VERSION "HNNBNNNYNNNNNNNNNNNNNNNNNNNNNNNNNNNNNNNNNN/4/%%%/4/'%**4NNN///"

NS_ :

BS_:

BU_: BAP_Tester BedienDisp_vo BedienSG_hi CGS DDA Gateway Gateway_PAG GurtMikrofon OTA_FC ZR_High ZR_LIMU ZR_MIB_TOP_ab_Gen3 ZR_Standard

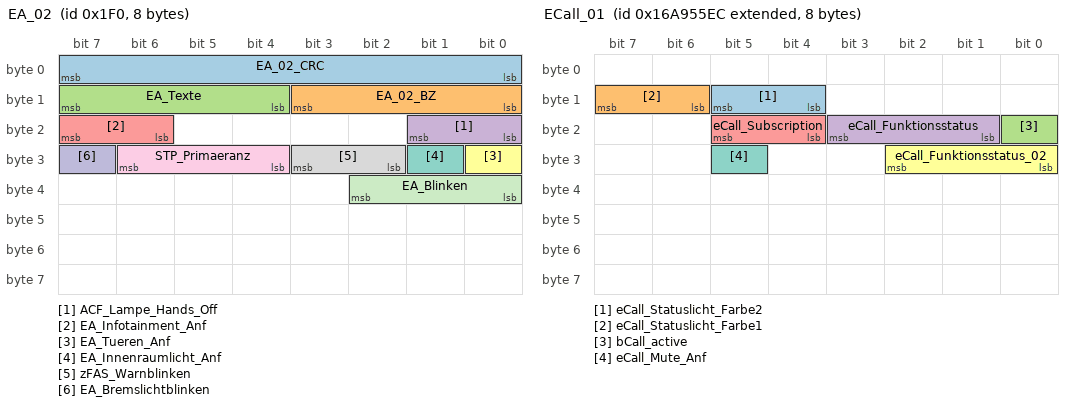
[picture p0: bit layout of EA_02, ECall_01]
BO_ 496 EA_02: 8 Gateway
 SG_ EA_02_CRC : 0|8@1+ (1,0) [0|255] ""  Vector__XXX
 SG_ EA_02_BZ : 8|4@1+ (1,0) [0|15] ""  Vector__XXX
 SG_ EA_Texte : 12|4@1+ (1.0,0.0) [0.0|15] ""  ZR_High
 SG_ ACF_Lampe_Hands_Off : 16|2@1+ (1.0,0.0) [0.0|3] ""  Vector__XXX
 SG_ EA_Infotainment_Anf : 22|2@1+ (1.0,0.0) [0.0|3] ""  ZR_High,ZR_LIMU,ZR_MIB_TOP_ab_Gen3,ZR_Standard
 SG_ EA_Tueren_Anf : 24|1@1+ (1.0,0.0) [0.0|1] ""  ZR_High
 SG_ EA_Innenraumlicht_Anf : 25|1@1+ (1.0,0.0) [0.0|1] ""  ZR_High
 SG_ zFAS_Warnblinken : 26|2@1+ (1.0,0.0) [0.0|3] ""  ZR_High
 SG_ STP_Primaeranz : 28|3@1+ (1.0,0.0) [0.0|7] ""  Vector__XXX
 SG_ EA_Bremslichtblinken : 31|1@1+ (1.0,0.0) [0.0|1] ""  Vector__XXX
 SG_ EA_Blinken : 32|3@1+ (1.0,0.0) [0.0|7] ""  Vector__XXX

BO_ 2527679980 ECall_01: 8 Gateway
 SG_ eCall_Statuslicht_Farbe2 : 12|2@1+ (1.0,0.0) [0.0|3] ""  ZR_High
 SG_ eCall_Statuslicht_Farbe1 : 14|2@1+ (1.0,0.0) [0.0|3] ""  ZR_High
 SG_ bCall_active : 16|1@1+ (1.0,0.0) [0.0|1] ""  OTA_FC,ZR_High
 SG_ eCall_Funktionsstatus : 17|3@1+ (1.0,0.0) [0.0|7] ""  ZR_High
 SG_ eCall_Subscription : 20|2@1+ (1.0,0.0) [0.0|3] ""  Vector__XXX
 SG_ eCall_Funktionsstatus_02 : 24|3@1+ (1.0,0.0) [0.0|7] ""  ZR_High
 SG_ eCall_Mute_Anf : 29|1@1+ (1.0,0.0) [0.0|1] ""  Vector__XXX

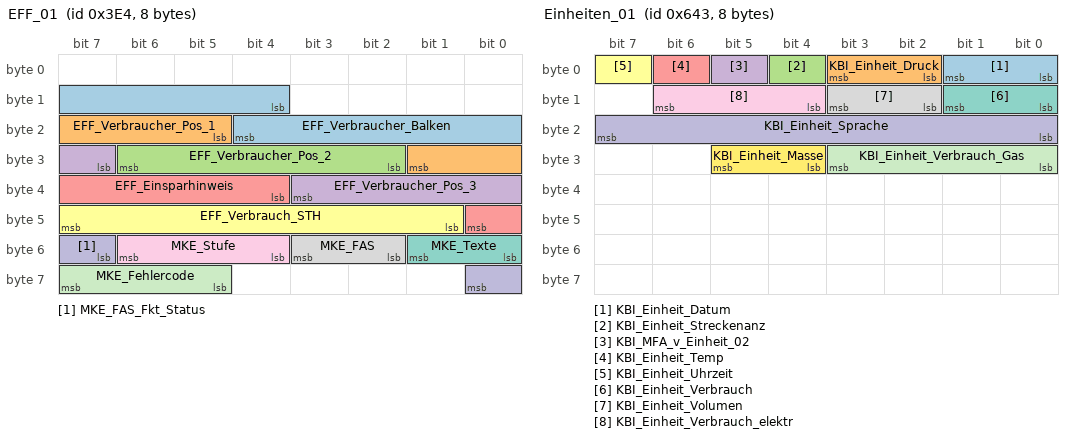
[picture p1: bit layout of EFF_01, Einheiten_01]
BO_ 996 EFF_01: 8 Gateway
 SG_ EFF_Verbraucher_Balken : 12|9@1+ (0.01,0) [0.00|5.09] "Unit_LiterPerHour"  Vector__XXX
 SG_ EFF_Verbraucher_Pos_1 : 21|5@1+ (1.0,0.0) [0.0|31] ""  Vector__XXX
 SG_ EFF_Verbraucher_Pos_2 : 26|5@1+ (1.0,0.0) [0.0|31] ""  Vector__XXX
 SG_ EFF_Verbraucher_Pos_3 : 31|5@1+ (1.0,0.0) [0.0|31] ""  Vector__XXX
 SG_ EFF_Einsparhinweis : 36|5@1+ (1.0,0.0) [0.0|31] ""  Vector__XXX
 SG_ EFF_Verbrauch_STH : 41|7@1+ (0.01,0) [0.00|1.26] "Unit_LiterPerHour"  ZR_High
 SG_ MKE_Texte : 48|2@1+ (1.0,0.0) [0.0|3] ""  ZR_High
 SG_ MKE_FAS : 50|2@1+ (1.0,0.0) [0.0|3] ""  ZR_High
 SG_ MKE_Stufe : 52|3@1+ (1.0,0.0) [0.0|7] ""  ZR_High
 SG_ MKE_FAS_Fkt_Status : 55|2@1+ (1.0,0.0) [0.0|3] ""  ZR_High
 SG_ MKE_Fehlercode : 61|3@1+ (1.0,0.0) [0.0|7] ""  Vector__XXX

BO_ 1603 Einheiten_01: 8 Gateway
 SG_ KBI_Einheit_Datum : 0|2@1+ (1.0,0.0) [0.0|3] ""  BedienSG_hi,OTA_FC,ZR_High,ZR_Standard
 SG_ KBI_Einheit_Druck : 2|2@1+ (1.0,0.0) [0.0|3] ""  BedienSG_hi,OTA_FC,ZR_High,ZR_Standard
 SG_ KBI_Einheit_Streckenanz : 4|1@1+ (1.0,0.0) [0.0|1] ""  BedienSG_hi,OTA_FC,ZR_High,ZR_Standard
 SG_ KBI_MFA_v_Einheit_02 : 5|1@1+ (1.0,0.0) [0.0|1] ""  OTA_FC,ZR_High,ZR_Standard
 SG_ KBI_Einheit_Temp : 6|1@1+ (1.0,0.0) [0.0|1] ""  BedienDisp_vo,BedienSG_hi,OTA_FC,ZR_High,ZR_Standard
 SG_ KBI_Einheit_Uhrzeit : 7|1@1+ (1.0,0.0) [0.0|1] ""  BedienSG_hi,OTA_FC,ZR_High,ZR_Standard
 SG_ KBI_Einheit_Verbrauch : 8|2@1+ (1.0,0.0) [0.0|3] ""  BedienSG_hi,OTA_FC,ZR_High,ZR_Standard
 SG_ KBI_Einheit_Volumen : 10|2@1+ (1.0,0.0) [0.0|3] ""  BedienSG_hi,OTA_FC,ZR_High,ZR_Standard
 SG_ KBI_Einheit_Verbrauch_elektr : 12|3@1+ (1.0,0.0) [0.0|7] ""  OTA_FC
 SG_ KBI_Einheit_Sprache : 16|8@1+ (1,0) [0|255] ""  BedienSG_hi,OTA_FC,ZR_High,ZR_Standard
 SG_ KBI_Einheit_Verbrauch_Gas : 24|4@1+ (1.0,0.0) [0.0|15] ""  Vector__XXX
 SG_ KBI_Einheit_Masse : 28|2@1+ (1.0,0.0) [0.0|3] ""  OTA_FC

BO_ 1622 ELV_01: 8 Gateway
 SG_ ELV_01_CRC : 0|8@1+ (1,0) [0|255] ""  Vector__XXX
 SG_ ELV_01_BZ : 8|4@1+ (1,0) [0|15] ""  Vector__XXX
 SG_ ELV_Anf_Klemme_S : 12|1@1+ (1.0,0.0) [0.0|1] ""  Vector__XXX
 SG_ ELV_Anf_Klemme_15 : 13|1@1+ (1.0,0.0) [0.0|1] ""  Vector__XXX
 SG_ ELV_Anf_Klemme_50 : 14|1@1+ (1.0,0.0) [0.0|1] ""  Vector__XXX
 SG_ ELV_01_Sendestatus : 15|1@1+ (1.0,0.0) [0.0|1] ""  Vector__XXX
 SG_ ELV_Verriegelt : 16|1@1+ (1.0,0.0) [0.0|1] ""  ZR_High
 SG_ ELV_Entriegelt : 17|1@1+ (1.0,0.0) [0.0|1] ""  ZR_High
 SG_ ELV_ZAT_betaetigt : 18|1@1+ (1.0,0.0) [0.0|1] ""  Vector__XXX
 SG_ ELV_Lebenszustand : 19|1@1+ (1.0,0.0) [0.0|1] ""  Vector__XXX
 SG_ ELV_Anlernmodus : 20|1@1+ (1.0,0.0) [0.0|1] ""  Vector__XXX
 SG_ ELV_Klemmenfreigabe : 22|1@1+ (1.0,0.0) [0.0|1] ""  Vector__XXX
 SG_ ELV_Abbruch_Anf_Klemmenfreigabe : 23|1@1+ (1.0,0.0) [0.0|1] ""  Vector__XXX
 SG_ ELV_LED_Rot : 24|1@1+ (1.0,0.0) [0.0|1] ""  ZR_High
 SG_ ELV_LED_Gelb : 25|1@1+ (1.0,0.0) [0.0|1] ""  Vector__XXX
 SG_ ELV_Txt_Panikabschaltung : 27|1@1+ (1.0,0.0) [0.0|1] ""  Vector__XXX
 SG_ ELV_Txt_Lkg_Bewegen : 28|1@1+ (1.0,0.0) [0.0|1] ""  ZR_High
 SG_ ELV_Txt_Werkstatt : 29|1@1+ (1.0,0.0) [0.0|1] ""  ZR_High
 SG_ ELV_Txt_Defekt : 30|1@1+ (1.0,0.0) [0.0|1] ""  ZR_High
 SG_ ELV_Txt_P_Gang : 31|1@1+ (1.0,0.0) [0.0|1] ""  Vector__XXX
 SG_ ELV_Txt_PN_Gang : 32|1@1+ (1.0,0.0) [0.0|1] ""  Vector__XXX
 SG_ ELV_Txt_Kupplung : 33|1@1+ (1.0,0.0) [0.0|1] ""  Vector__XXX
 SG_ ELV_Txt_Bremse : 34|1@1+ (1.0,0.0) [0.0|1] ""  Vector__XXX
 SG_ ELV_P_verriegelt : 35|1@1+ (1.0,0.0) [0.0|1] ""  Vector__XXX

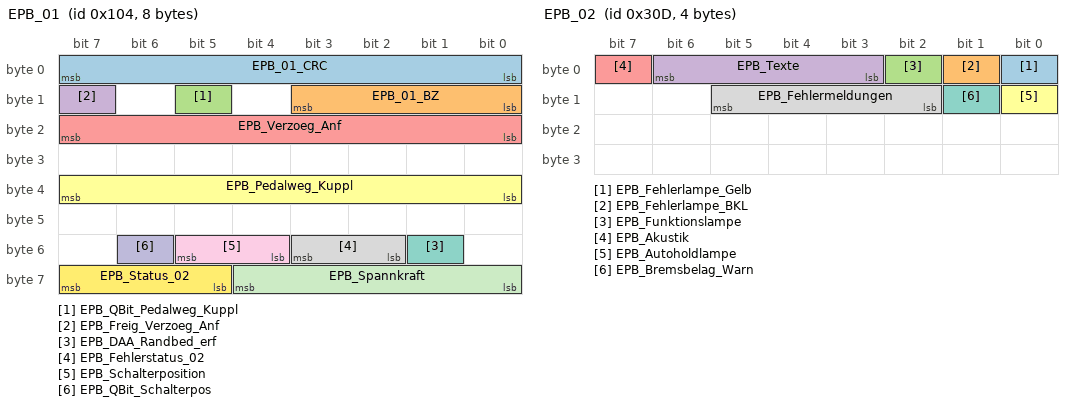
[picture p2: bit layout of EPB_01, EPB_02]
BO_ 260 EPB_01: 8 Gateway
 SG_ EPB_01_CRC : 0|8@1+ (1,0) [0|255] ""  Vector__XXX
 SG_ EPB_01_BZ : 8|4@1+ (1,0) [0|15] ""  Vector__XXX
 SG_ EPB_QBit_Pedalweg_Kuppl : 13|1@1+ (1.0,0.0) [0.0|1] ""  Vector__XXX
 SG_ EPB_Freig_Verzoeg_Anf : 15|1@1+ (1.0,0.0) [0.0|1] ""  Vector__XXX
 SG_ EPB_Verzoeg_Anf : 16|8@1+ (0.048,-7.968) [-7.968|4.224] "Unit_MeterPerSeconSquar"  Vector__XXX
 SG_ EPB_Pedalweg_Kuppl : 32|8@1+ (0.4,0) [8.0|92.0] "Unit_PerCent"  Vector__XXX
 SG_ EPB_DAA_Randbed_erf : 49|1@1+ (1.0,0.0) [0.0|1] ""  Vector__XXX
 SG_ EPB_Fehlerstatus_02 : 50|2@1+ (1.0,0.0) [0.0|3] ""  Vector__XXX
 SG_ EPB_Schalterposition : 52|2@1+ (1.0,0.0) [0.0|3] ""  OTA_FC
 SG_ EPB_QBit_Schalterpos : 54|1@1+ (1.0,0.0) [0.0|1] ""  Vector__XXX
 SG_ EPB_Spannkraft : 56|5@1+ (1,0) [0|29] "Unit_KiloNewto"  Vector__XXX
 SG_ EPB_Status_02 : 61|3@1+ (1.0,0.0) [0.0|7] ""  OTA_FC,ZR_High,ZR_LIMU,ZR_MIB_TOP_ab_Gen3,ZR_Standard

BO_ 781 EPB_02: 4 Gateway
 SG_ EPB_Fehlerlampe_Gelb : 0|1@1+ (1.0,0.0) [0.0|1] ""  Vector__XXX
 SG_ EPB_Fehlerlampe_BKL : 1|1@1+ (1.0,0.0) [0.0|1] ""  Vector__XXX
 SG_ EPB_Funktionslampe : 2|1@1+ (1.0,0.0) [0.0|1] ""  ZR_High
 SG_ EPB_Texte : 3|4@1+ (1.0,0.0) [0.0|15] ""  ZR_High
 SG_ EPB_Akustik : 7|1@1+ (1.0,0.0) [0.0|1] ""  Vector__XXX
 SG_ EPB_Autoholdlampe : 8|1@1+ (1.0,0.0) [0.0|1] ""  OTA_FC,ZR_High
 SG_ EPB_Bremsbelag_Warn : 9|1@1+ (1.0,0.0) [0.0|1] ""  Vector__XXX
 SG_ EPB_Fehlermeldungen : 10|4@1+ (1.0,0.0) [0.0|15] ""  ZR_High

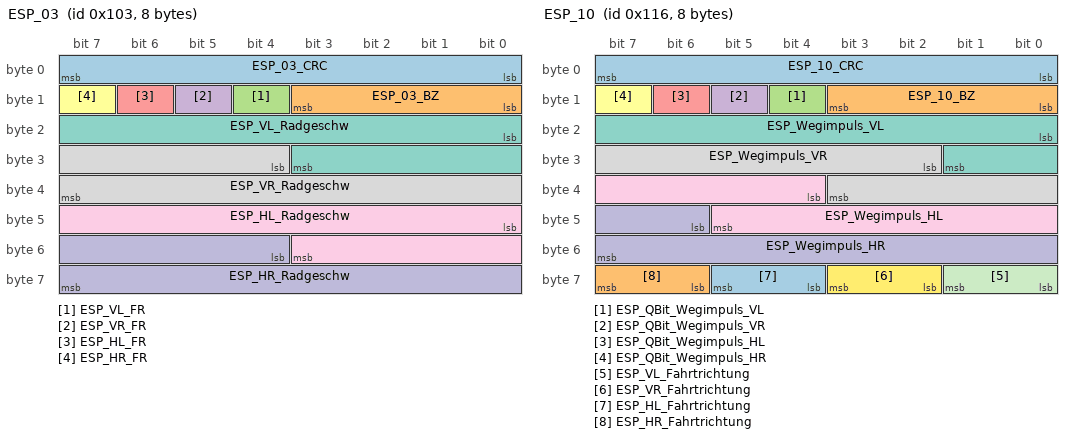
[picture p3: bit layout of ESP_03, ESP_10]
BO_ 259 ESP_03: 8 Gateway
 SG_ ESP_03_CRC : 0|8@1+ (1,0) [0|255] ""  Vector__XXX
 SG_ ESP_03_BZ : 8|4@1+ (1,0) [0|15] ""  Vector__XXX
 SG_ ESP_VL_FR : 12|1@1+ (1.0,0.0) [0.0|1] ""  OTA_FC
 SG_ ESP_VR_FR : 13|1@1+ (1.0,0.0) [0.0|1] ""  OTA_FC
 SG_ ESP_HL_FR : 14|1@1+ (1.0,0.0) [0.0|1] ""  OTA_FC
 SG_ ESP_HR_FR : 15|1@1+ (1.0,0.0) [0.0|1] ""  OTA_FC
 SG_ ESP_VL_Radgeschw : 16|12@1+ (0.1,0) [0.0|409.2] "Unit_KiloMeterPerHour"  OTA_FC,ZR_High,ZR_LIMU,ZR_MIB_TOP_ab_Gen3
 SG_ ESP_VR_Radgeschw : 28|12@1+ (0.1,0) [0.0|409.2] "Unit_KiloMeterPerHour"  OTA_FC,ZR_High,ZR_LIMU,ZR_MIB_TOP_ab_Gen3
 SG_ ESP_HL_Radgeschw : 40|12@1+ (0.1,0) [0.0|409.2] "Unit_KiloMeterPerHour"  OTA_FC,ZR_High,ZR_LIMU,ZR_MIB_TOP_ab_Gen3
 SG_ ESP_HR_Radgeschw : 52|12@1+ (0.1,0) [0.0|409.2] "Unit_KiloMeterPerHour"  OTA_FC,ZR_High,ZR_LIMU,ZR_MIB_TOP_ab_Gen3

BO_ 262 ESP_05: 8 Gateway
 SG_ ESP_05_CRC : 0|8@1+ (1,0) [0|255] ""  Vector__XXX
 SG_ ESP_05_BZ : 8|4@1+ (1,0) [0|15] ""  Vector__XXX
 SG_ ESP_QBit_Bremsdruck : 12|1@1+ (1.0,0.0) [0.0|1] ""  ZR_High,ZR_LIMU,ZR_MIB_TOP_ab_Gen3,ZR_Standard
 SG_ ESP_QBit_Fahrer_bremst : 13|1@1+ (1.0,0.0) [0.0|1] ""  Vector__XXX
 SG_ ESP_Schwelle_Unterdruck : 14|2@1+ (1.0,0.0) [0.0|3] ""  Vector__XXX
 SG_ ESP_Bremsdruck : 16|10@1+ (0.3,-30) [-30.0|276.6] "Unit_Bar"  OTA_FC,ZR_High,ZR_LIMU,ZR_MIB_TOP_ab_Gen3,ZR_Standard
 SG_ ESP_Fahrer_bremst : 26|1@1+ (1.0,0.0) [0.0|1] ""  Vector__XXX
 SG_ ESP_Lenkeingriff_ADS : 28|1@1+ (1.0,0.0) [0.0|1] ""  ZR_High
 SG_ ECD_Fehler : 32|1@1+ (1.0,0.0) [0.0|1] ""  Vector__XXX
 SG_ ECD_nicht_verfuegbar : 33|1@1+ (1.0,0.0) [0.0|1] ""  Vector__XXX
 SG_ ESP_Status_Bremsentemp : 34|1@1+ (1.0,0.0) [0.0|1] ""  Vector__XXX
 SG_ ESP_Autohold_Standby : 35|1@1+ (1.0,0.0) [0.0|1] ""  Vector__XXX
 SG_ ESP_HDC_Standby : 36|1@1+ (1.0,0.0) [0.0|1] ""  Vector__XXX
 SG_ ESP_HBA_aktiv : 37|1@1+ (1.0,0.0) [0.0|1] ""  Vector__XXX
 SG_ ESP_Prefill_ausgeloest : 38|1@1+ (1.0,0.0) [0.0|1] ""  Vector__XXX
 SG_ ESP_Rueckwaertsfahrt_erkannt : 39|1@1+ (1.0,0.0) [0.0|1] ""  Vector__XXX
 SG_ ESP_Status_Anfahrhilfe : 40|1@1+ (1.0,0.0) [0.0|1] ""  ZR_High
 SG_ ESP_HDC_aktiv : 41|1@1+ (1.0,0.0) [0.0|1] ""  ZR_High
 SG_ ESP_StartStopp_Info : 42|2@1+ (1.0,0.0) [0.0|3] ""  Vector__XXX
 SG_ ESP_Eingr_HL : 44|1@1+ (1.0,0.0) [0.0|1] ""  ZR_High,ZR_LIMU,ZR_MIB_TOP_ab_Gen3
 SG_ ESP_Eingr_HR : 45|1@1+ (1.0,0.0) [0.0|1] ""  ZR_High,ZR_LIMU,ZR_MIB_TOP_ab_Gen3
 SG_ ESP_Eingr_VL : 46|1@1+ (1.0,0.0) [0.0|1] ""  ZR_High,ZR_LIMU,ZR_MIB_TOP_ab_Gen3
 SG_ ESP_Eingr_VR : 47|1@1+ (1.0,0.0) [0.0|1] ""  ZR_High,ZR_LIMU,ZR_MIB_TOP_ab_Gen3
 SG_ ESP_BKV_Unterdruck : 48|8@1+ (4,0) [4|1012] "Unit_MilliBar"  Vector__XXX
 SG_ ESP_Autohold_aktiv : 56|1@1+ (1.0,0.0) [0.0|1] ""  ZR_High
 SG_ ESP_FStatus_Anfahrhilfe : 57|1@1+ (1.0,0.0) [0.0|1] ""  Vector__XXX
 SG_ ESP_Verz_EPB_aktiv : 58|1@1+ (1.0,0.0) [0.0|1] ""  Vector__XXX
 SG_ ESC_Bremslicht : 59|1@1+ (1.0,0.0) [0.0|1] ""  OTA_FC
 SG_ ESP_Verzoeg_EPB_verf : 60|1@1+ (1.0,0.0) [0.0|1] ""  Vector__XXX
 SG_ ESP_Status_Bremsdruck : 61|1@1+ (1.0,0.0) [0.0|1] ""  Vector__XXX
 SG_ ESP_Anforderung_EPB : 62|2@1+ (1.0,0.0) [0.0|3] ""  Vector__XXX

BO_ 914 ESP_07: 8 Gateway
 SG_ ESP_07_CRC : 0|8@1+ (1,0) [0|255] ""  Vector__XXX
 SG_ ESP_07_BZ : 8|4@1+ (1,0) [0|15] ""  Vector__XXX
 SG_ ESP_Allrad_Antrieb : 13|1@1+ (1.0,0.0) [0.0|1] ""  Vector__XXX
 SG_ ESP_Codierung_ADS : 14|2@1+ (1.0,0.0) [0.0|3] ""  Vector__XXX
 SG_ ESP_RTA_HL : 16|8@1+ (0.048828125,-6.20117) [-6.201170000|6.152345625] "Unit_PerCent"  Vector__XXX
 SG_ ESP_RTA_HR : 24|8@1+ (0.048828125,-6.20117) [-6.201170000|6.152345625] "Unit_PerCent"  Vector__XXX
 SG_ ESP_RTA_VR : 32|8@1+ (0.048828125,-6.20117) [-6.201170000|6.152345625] "Unit_PerCent"  Vector__XXX
 SG_ OBD_Fehler_Radsensor_HL : 40|4@1+ (1.0,0.0) [0.0|15] ""  Vector__XXX
 SG_ OBD_Fehler_Radsensor_HR : 44|4@1+ (1.0,0.0) [0.0|15] ""  Vector__XXX
 SG_ OBD_Fehler_Radsensor_VL : 48|4@1+ (1.0,0.0) [0.0|15] ""  Vector__XXX
 SG_ OBD_Fehler_Radsensor_VR : 52|4@1+ (1.0,0.0) [0.0|15] ""  Vector__XXX
 SG_ ESP_Qualifizierung_Antriebsart : 56|1@1+ (1.0,0.0) [0.0|1] ""  Vector__XXX
 SG_ ESP_Offroad_Modus : 57|1@1+ (1.0,0.0) [0.0|1] ""  Vector__XXX
 SG_ ESP_MKB_ausloesbar : 58|1@1+ (1.0,0.0) [0.0|1] ""  Vector__XXX
 SG_ ESP_Stat_FallBack_eBKV : 59|1@1+ (1.0,0.0) [0.0|1] ""  Vector__XXX
 SG_ ESC_cAQP_Trigger : 60|1@1+ (1.0,0.0) [0.0|1] ""  Vector__XXX
 SG_ ESP_OBD_Status : 61|1@1+ (1.0,0.0) [0.0|1] ""  Vector__XXX
 SG_ ESP_Rollenmodus_Deaktivieren : 62|1@1+ (1.0,0.0) [0.0|1] ""  ZR_High,ZR_LIMU,ZR_MIB_TOP_ab_Gen3
 SG_ ESP_nachtr_Stopp_Anf : 63|1@1+ (1.0,0.0) [0.0|1] ""  Vector__XXX

BO_ 278 ESP_10: 8 Gateway
 SG_ ESP_10_CRC : 0|8@1+ (1,0) [0|255] ""  Vector__XXX
 SG_ ESP_10_BZ : 8|4@1+ (1,0) [0|15] ""  Vector__XXX
 SG_ ESP_QBit_Wegimpuls_VL : 12|1@1+ (1.0,0.0) [0.0|1] ""  ZR_High,ZR_LIMU,ZR_MIB_TOP_ab_Gen3,ZR_Standard
 SG_ ESP_QBit_Wegimpuls_VR : 13|1@1+ (1.0,0.0) [0.0|1] ""  ZR_High,ZR_LIMU,ZR_MIB_TOP_ab_Gen3,ZR_Standard
 SG_ ESP_QBit_Wegimpuls_HL : 14|1@1+ (1.0,0.0) [0.0|1] ""  ZR_High,ZR_LIMU,ZR_MIB_TOP_ab_Gen3,ZR_Standard
 SG_ ESP_QBit_Wegimpuls_HR : 15|1@1+ (1.0,0.0) [0.0|1] ""  ZR_High,ZR_LIMU,ZR_MIB_TOP_ab_Gen3,ZR_Standard
 SG_ ESP_Wegimpuls_VL : 16|10@1+ (1,0) [0|1000] ""  ZR_High,ZR_LIMU,ZR_MIB_TOP_ab_Gen3,ZR_Standard
 SG_ ESP_Wegimpuls_VR : 26|10@1+ (1,0) [0|1000] ""  ZR_High,ZR_LIMU,ZR_MIB_TOP_ab_Gen3,ZR_Standard
 SG_ ESP_Wegimpuls_HL : 36|10@1+ (1,0) [0|1000] ""  ZR_High,ZR_LIMU,ZR_MIB_TOP_ab_Gen3,ZR_Standard
 SG_ ESP_Wegimpuls_HR : 46|10@1+ (1,0) [0|1000] ""  ZR_High,ZR_LIMU,ZR_MIB_TOP_ab_Gen3,ZR_Standard
 SG_ ESP_VL_Fahrtrichtung : 56|2@1+ (1.0,0.0) [0.0|3] ""  OTA_FC,ZR_High,ZR_LIMU,ZR_MIB_TOP_ab_Gen3,ZR_Standard
 SG_ ESP_VR_Fahrtrichtung : 58|2@1+ (1.0,0.0) [0.0|3] ""  OTA_FC,ZR_High,ZR_LIMU,ZR_MIB_TOP_ab_Gen3,ZR_Standard
 SG_ ESP_HL_Fahrtrichtung : 60|2@1+ (1.0,0.0) [0.0|3] ""  OTA_FC,ZR_High,ZR_LIMU,ZR_MIB_TOP_ab_Gen3,ZR_Standard
 SG_ ESP_HR_Fahrtrichtung : 62|2@1+ (1.0,0.0) [0.0|3] ""  OTA_FC,ZR_High,ZR_LIMU,ZR_MIB_TOP_ab_Gen3,ZR_Standard

BO_ 418 ESP_15: 8 Gateway
 SG_ ESP_15_CRC : 0|8@1+ (1,0) [0|255] ""  Vector__XXX
 SG_ ESP_15_BZ : 8|4@1+ (1,0) [0|15] ""  Vector__XXX
 SG_ HMS_P_beibehalten_GE : 12|2@1+ (1.0,0.0) [0.0|3] ""  Vector__XXX
 SG_ HMS_Konsistenz_GE : 14|1@1+ (1.0,0.0) [0.0|1] ""  Vector__XXX
 SG_ HMS_Konsistenz_IPA : 15|1@1+ (1.0,0.0) [0.0|1] ""  Vector__XXX
 SG_ HMS_Konsistenz_STA : 18|1@1+ (1.0,0.0) [0.0|1] ""  Vector__XXX
 SG_ HMS_Konsistenz_MO : 19|1@1+ (1.0,0.0) [0.0|1] ""  Vector__XXX
 SG_ HMS_halten_nicht_verfuegbar : 20|1@1+ (1.0,0.0) [0.0|1] ""  Vector__XXX
 SG_ NL_PRIM_STP_01_Status : 21|3@1+ (1.0,0.0) [0.0|7] ""  Vector__XXX
 SG_ VMM_Warnblinken : 24|1@1+ (1.0,0.0) [0.0|1] ""  Vector__XXX
 SG_ VZM_Status : 26|3@1+ (1.0,0.0) [0.0|7] ""  Vector__XXX
 SG_ HMS_Notstopp_Status : 29|3@1+ (1.0,0.0) [0.0|7] ""  Vector__XXX
 SG_ HMS_parken_nicht_verfuegbar : 32|1@1+ (1.0,0.0) [0.0|1] ""  Vector__XXX
 SG_ HMS_Anforderung_GE : 33|3@1+ (1.0,0.0) [0.0|7] ""  Vector__XXX
 SG_ HMS_Systemstatus : 36|4@1+ (1.0,0.0) [0.0|15] ""  DDA,ZR_High
 SG_ HMS_Stillstand : 40|3@1+ (1.0,0.0) [0.0|7] ""  Vector__XXX
 SG_ HMS_aktives_System : 43|5@1+ (1.0,0.0) [0.0|31] ""  Vector__XXX
 SG_ HMS_Konsistenz_HVLM : 48|1@1+ (1.0,0.0) [0.0|1] ""  Vector__XXX
 SG_ HMS_Konsistenz_ACC : 49|1@1+ (1.0,0.0) [0.0|1] ""  Vector__XXX
 SG_ HMS_Fehlerstatus : 50|3@1+ (1.0,0.0) [0.0|7] ""  Vector__XXX
 SG_ ESP_Index_Haltemoment : 53|1@1+ (1.0,0.0) [0.0|1] ""  Vector__XXX
 SG_ ESP_Haltemoment : 54|10@1+ (10,0) [0|10210] "Unit_NewtoMeter"  Vector__XXX

BO_ 1629 ESP_20: 8 Gateway
 SG_ ESP_20_CRC : 0|8@1+ (1,0) [0|255] ""  Vector__XXX
 SG_ ESP_20_BZ : 8|4@1+ (1,0) [0|15] ""  Vector__XXX
 SG_ BR_Systemart : 12|2@1+ (1.0,0.0) [0.0|3] ""  Vector__XXX
 SG_ ESP_SpannungsAnf_02 : 14|2@1+ (1.0,0.0) [0.0|3] ""  Vector__XXX
 SG_ ESP_Zaehnezahl : 16|8@1+ (1,0) [0|255] ""  ZR_High,ZR_LIMU,ZR_MIB_TOP_ab_Gen3,ZR_Standard
 SG_ ESP_Charisma_FahrPr : 24|4@1+ (1.0,0.0) [0.0|15] ""  Vector__XXX
 SG_ ESP_Charisma_Status : 28|2@1+ (1.0,0.0) [0.0|3] ""  Vector__XXX
 SG_ ESP_Wiederstart_Anz_01 : 30|1@1+ (1.0,0.0) [0.0|1] ""  ZR_High
 SG_ ESP_Wiederstart_Anz_02 : 31|1@1+ (1.0,0.0) [0.0|1] ""  Vector__XXX
 SG_ ESP_Wiederstart_Anz_03 : 32|1@1+ (1.0,0.0) [0.0|1] ""  Vector__XXX
 SG_ ESP_Wiederstart_Anz_04 : 33|1@1+ (1.0,0.0) [0.0|1] ""  ZR_High
 SG_ ESP_Stoppverbot_Anz_01 : 34|1@1+ (1.0,0.0) [0.0|1] ""  ZR_High
 SG_ ESP_Stoppverbot_Anz_02 : 35|1@1+ (1.0,0.0) [0.0|1] ""  Vector__XXX
 SG_ ESP_Stoppverbot_Anz_03 : 36|1@1+ (1.0,0.0) [0.0|1] ""  Vector__XXX
 SG_ ESP_Stoppverbot_Anz_04 : 37|1@1+ (1.0,0.0) [0.0|1] ""  Vector__XXX
 SG_ ESP_Stoppverbot_Anz_05 : 38|1@1+ (1.0,0.0) [0.0|1] ""  ZR_High
 SG_ ESP_Stoppverbot_Anz_06 : 39|1@1+ (1.0,0.0) [0.0|1] ""  ZR_High
 SG_ ESP_Stoppverbot_Anz_07 : 40|1@1+ (1.0,0.0) [0.0|1] ""  Vector__XXX
 SG_ ESP_Stoppverbot_Anz_Std : 41|1@1+ (1.0,0.0) [0.0|1] ""  Vector__XXX
 SG_ ESP_Dachrelingsensor : 42|2@1+ (1.0,0.0) [0.0|3] ""  ZR_High
 SG_ ESP_Stoppverbot_Anz_08 : 44|1@1+ (1.0,0.0) [0.0|1] ""  Vector__XXX
 SG_ HDC_Charisma_FahrPr : 45|4@1+ (1.0,0.0) [0.0|15] ""  Vector__XXX
 SG_ HDC_Charisma_Status : 49|2@1+ (1.0,0.0) [0.0|3] ""  Vector__XXX
 SG_ BR_QBit_Reifenumfang : 51|1@1+ (1.0,0.0) [0.0|1] ""  ZR_High
 SG_ BR_Reifenumfang : 52|12@1+ (1,0) [0|4095] "Unit_MilliMeter"  ZR_High

BO_ 253 ESP_21: 8 Gateway
 SG_ ESP_21_CRC : 0|8@1+ (1,0) [0|255] ""  Vector__XXX
 SG_ ESP_21_BZ : 8|4@1+ (1,0) [0|15] ""  Vector__XXX
 SG_ BR_Eingriffsmoment : 12|10@1+ (1,-509) [-509|509] ""  Vector__XXX
 SG_ ESP_Diagnose : 23|1@1+ (1.0,0.0) [0.0|1] ""  ZR_High
 SG_ ESC_v_Signal_Qualifier_High_Low : 24|3@1+ (1.0,0.0) [0.0|7] ""  Vector__XXX
 SG_ ESP_Vorsteuerung : 28|1@1+ (1.0,0.0) [0.0|1] ""  Vector__XXX
 SG_ OBD_Schlechtweg : 30|1@1+ (1.0,0.0) [0.0|1] ""  ZR_High
 SG_ OBD_QBit_Schlechtweg : 31|1@1+ (1.0,0.0) [0.0|1] ""  ZR_High
 SG_ ESP_v_Signal : 32|16@1+ (0.01,0) [0.00|655.32] "Unit_KiloMeterPerHour"  BedienSG_hi,DDA,OTA_FC,ZR_High,ZR_LIMU,ZR_MIB_TOP_ab_Gen3,ZR_Standard
 SG_ ASR_Tastung_passiv : 48|1@1+ (1.0,0.0) [0.0|1] ""  OTA_FC
 SG_ ESP_Tastung_passiv : 49|1@1+ (1.0,0.0) [0.0|1] ""  OTA_FC,ZR_High,ZR_LIMU,ZR_MIB_TOP_ab_Gen3
 SG_ ESP_Systemstatus : 50|1@1+ (1.0,0.0) [0.0|1] ""  OTA_FC
 SG_ ASR_Schalteingriff : 51|2@1+ (1.0,0.0) [0.0|3] ""  Vector__XXX
 SG_ ESP_QBit_v_Signal : 55|1@1+ (1.0,0.0) [0.0|1] ""  ZR_High,ZR_LIMU,ZR_MIB_TOP_ab_Gen3,ZR_Standard
 SG_ ABS_Bremsung : 56|1@1+ (1.0,0.0) [0.0|1] ""  OTA_FC,ZR_High,ZR_LIMU,ZR_MIB_TOP_ab_Gen3
 SG_ ASR_Anf : 57|1@1+ (1.0,0.0) [0.0|1] ""  ZR_High
 SG_ MSR_Anf : 58|1@1+ (1.0,0.0) [0.0|1] ""  OTA_FC,ZR_High
 SG_ EBV_Eingriff : 59|1@1+ (1.0,0.0) [0.0|1] ""  Vector__XXX
 SG_ EDS_Eingriff : 60|1@1+ (1.0,0.0) [0.0|1] ""  Vector__XXX
 SG_ ESP_Eingriff : 61|1@1+ (1.0,0.0) [0.0|1] ""  OTA_FC,ZR_High
 SG_ ESP_ASP : 62|1@1+ (1.0,0.0) [0.0|1] ""  ZR_High
 SG_ ESC_Neutralschaltung : 63|1@1+ (1.0,0.0) [0.0|1] ""  Vector__XXX

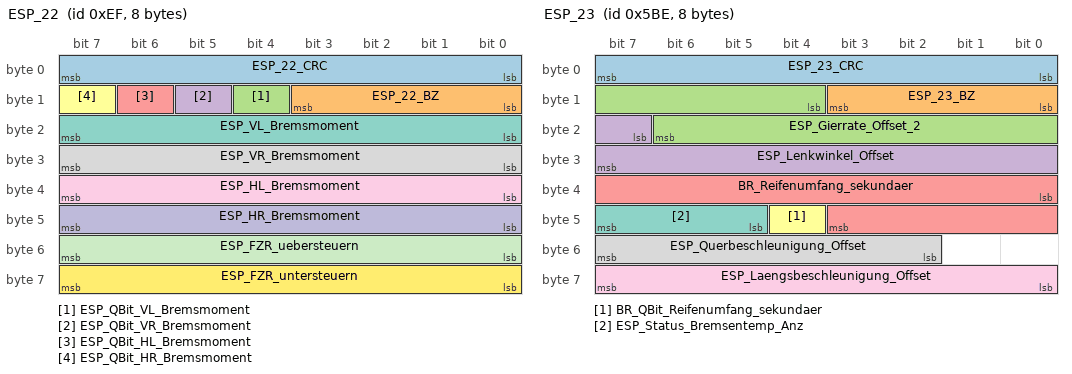
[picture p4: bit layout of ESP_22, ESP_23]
BO_ 239 ESP_22: 8 Gateway
 SG_ ESP_22_CRC : 0|8@1+ (1,0) [0|255] ""  Vector__XXX
 SG_ ESP_22_BZ : 8|4@1+ (1,0) [0|15] ""  Vector__XXX
 SG_ ESP_QBit_VL_Bremsmoment : 12|1@1+ (1.0,0.0) [0.0|1] ""  Vector__XXX
 SG_ ESP_QBit_VR_Bremsmoment : 13|1@1+ (1.0,0.0) [0.0|1] ""  Vector__XXX
 SG_ ESP_QBit_HL_Bremsmoment : 14|1@1+ (1.0,0.0) [0.0|1] ""  Vector__XXX
 SG_ ESP_QBit_HR_Bremsmoment : 15|1@1+ (1.0,0.0) [0.0|1] ""  Vector__XXX
 SG_ ESP_VL_Bremsmoment : 16|8@1+ (40,0) [0|10120] "Unit_NewtoMeter"  OTA_FC
 SG_ ESP_VR_Bremsmoment : 24|8@1+ (40,0) [0|10120] "Unit_NewtoMeter"  OTA_FC
 SG_ ESP_HL_Bremsmoment : 32|8@1+ (20,0) [0|5060] "Unit_NewtoMeter"  OTA_FC
 SG_ ESP_HR_Bremsmoment : 40|8@1+ (20,0) [0|5060] "Unit_NewtoMeter"  OTA_FC
 SG_ ESP_FZR_uebersteuern : 48|8@1+ (0.004,0) [0.000|1.000] ""  OTA_FC,ZR_High,ZR_LIMU,ZR_MIB_TOP_ab_Gen3
 SG_ ESP_FZR_untersteuern : 56|8@1+ (0.004,0) [0.000|1.000] ""  OTA_FC,ZR_High,ZR_LIMU,ZR_MIB_TOP_ab_Gen3

BO_ 1470 ESP_23: 8 Gateway
 SG_ ESP_23_CRC : 0|8@1+ (1,0) [0|255] ""  Vector__XXX
 SG_ ESP_23_BZ : 8|4@1+ (1,0) [0|15] ""  Vector__XXX
 SG_ ESP_Gierrate_Offset_2 : 12|11@1+ (0.01,-10.23) [-10.23|10.22] "Unit_DegreOfArcPerSecon"  Vector__XXX
 SG_ ESP_Lenkwinkel_Offset : 23|9@1+ (0.1,-25.5) [-25.5|25.4] "Unit_DegreOfArc"  Vector__XXX
 SG_ BR_Reifenumfang_sekundaer : 32|12@1+ (1,0) [0|4095] "Unit_MilliMeter"  Vector__XXX
 SG_ BR_QBit_Reifenumfang_sekundaer : 44|1@1+ (1.0,0.0) [0.0|1] ""  Vector__XXX
 SG_ ESP_Status_Bremsentemp_Anz : 45|3@1+ (1.0,0.0) [0.0|7] ""  ZR_High,ZR_LIMU,ZR_MIB_TOP_ab_Gen3
 SG_ ESP_Querbeschleunigung_Offset : 50|6@1+ (0.01,-0.3) [-0.30|0.31] "Unit_ForceOfGravi"  ZR_High
 SG_ ESP_Laengsbeschleunigung_Offset : 56|8@1+ (0.03125,-3.9375) [-3.93750|3.93750] "Unit_MeterPerSeconSquar"  ZR_High

BO_ 795 ESP_24: 8 Gateway
 SG_ ESP_24_CRC : 0|8@1+ (1,0) [0|255] ""  Vector__XXX
 SG_ ESP_24_BZ : 8|4@1+ (1,0) [0|15] ""  Vector__XXX
 SG_ ESP_Lampe : 12|1@1+ (1.0,0.0) [0.0|1] ""  OTA_FC,ZR_High,ZR_LIMU,ZR_MIB_TOP_ab_Gen3
 SG_ ABS_Lampe : 13|1@1+ (1.0,0.0) [0.0|1] ""  OTA_FC,ZR_High
 SG_ BK_Lampe_02 : 14|2@1+ (1.0,0.0) [0.0|3] ""  OTA_FC
 SG_ TC_Lampe : 16|1@1+ (1.0,0.0) [0.0|1] ""  Vector__XXX
 SG_ ESP_m_Raddrehz : 17|15@1+ (0.002,0) [0.000|65.278] "Unit_Hertz"  Vector__XXX
 SG_ ESP_Textanzeigen_03 : 32|5@1+ (1.0,0.0) [0.0|31] ""  OTA_FC
 SG_ ESP_Meldungen : 37|3@1+ (1.0,0.0) [0.0|7] ""  Vector__XXX
 SG_ ESP_Wegimp_VA : 40|11@1+ (1,0) [0|2047] ""  ZR_High,ZR_LIMU,ZR_MIB_TOP_ab_Gen3,ZR_Standard
 SG_ ESP_Fehlerstatus_Wegimp : 51|1@1+ (1.0,0.0) [0.0|1] ""  ZR_High,ZR_LIMU,ZR_MIB_TOP_ab_Gen3,ZR_Standard
 SG_ ESP_Wegimp_Ueberlauf : 52|1@1+ (1.0,0.0) [0.0|1] ""  ZR_High,ZR_LIMU,ZR_MIB_TOP_ab_Gen3,ZR_Standard
 SG_ ESP_QBit_Wegimp_VA : 53|1@1+ (1.0,0.0) [0.0|1] ""  ZR_High,ZR_LIMU,ZR_MIB_TOP_ab_Gen3,ZR_Standard
 SG_ ESP_HDC_Geschw_Farbe : 54|1@1+ (1.0,0.0) [0.0|1] ""  ZR_High,ZR_LIMU,ZR_MIB_TOP_ab_Gen3
 SG_ ESP_Off_Lampe : 55|1@1+ (1.0,0.0) [0.0|1] ""  OTA_FC,ZR_High
 SG_ ESP_HDC_Regelgeschw : 56|7@1+ (0.32,0) [0.32|39.68] "Unit_KiloMeterPerHour"  ZR_High,ZR_LIMU,ZR_MIB_TOP_ab_Gen3,ZR_Standard
 SG_ ESP_BKV_Warnung : 63|1@1+ (1.0,0.0) [0.0|1] ""  OTA_FC

BO_ 508 ESP_32: 8 Gateway
 SG_ ESP_32_CRC : 0|8@1+ (1,0) [0|255] ""  Vector__XXX
 SG_ ESP_32_BZ : 8|4@1+ (1,0) [0|15] ""  Vector__XXX
 SG_ ESP_Status_Bremsentemp_02 : 12|2@1+ (1.0,0.0) [0.0|3] ""  ZR_LIMU,ZR_MIB_TOP_ab_Gen3
 SG_ ESP_Aggregataktivitaet : 14|1@1+ (1.0,0.0) [0.0|1] ""  Vector__XXX
 SG_ ESP_Stillstandsflag : 15|1@1+ (1.0,0.0) [0.0|1] ""  Vector__XXX
 SG_ ESC_MBK_Meldungen : 16|2@1+ (1.0,0.0) [0.0|3] ""  Vector__XXX
 SG_ ESP_EDS_Anzeige : 32|3@1+ (1.0,0.0) [0.0|7] ""  ZR_High,ZR_LIMU,ZR_MIB_TOP_ab_Gen3
 SG_ RLE_Anzeigen : 35|3@1+ (1.0,0.0) [0.0|7] ""  Vector__XXX
 SG_ ESP_Wiederstart_Anz_Std : 38|1@1+ (1.0,0.0) [0.0|1] ""  Vector__XXX
 SG_ ESC_Anforderung_Airbrake : 39|1@1+ (1.0,0.0) [0.0|1] ""  Vector__XXX
 SG_ ESC_FBA_Meldungen : 40|2@1+ (1.0,0.0) [0.0|3] ""  Vector__XXX
 SG_ ESP_Rollover_Status_dyn : 42|2@1+ (1.0,0.0) [0.0|3] ""  Vector__XXX
 SG_ ESP_Rollover_Status_stat : 44|2@1+ (1.0,0.0) [0.0|3] ""  Vector__XXX
 SG_ ESP_AVH_LED : 46|3@1+ (1.0,0.0) [0.0|7] ""  Vector__XXX
 SG_ ESP_HDC_LED : 49|3@1+ (1.0,0.0) [0.0|7] ""  Vector__XXX
 SG_ ESP_Off_LED : 52|3@1+ (1.0,0.0) [0.0|7] ""  Vector__XXX
 SG_ ESP_Notbremsanzeige : 55|1@1+ (1.0,0.0) [0.0|1] ""  Vector__XXX
 SG_ ESC_Motorstartverzoegerung : 56|1@1+ (1.0,0.0) [0.0|1] ""  Vector__XXX
 SG_ ESP_Offroad_Lampe : 57|1@1+ (1.0,0.0) [0.0|1] ""  Vector__XXX
 SG_ ESP_HDC_Textanzeigen : 58|5@1+ (1.0,0.0) [0.0|31] ""  Vector__XXX
 SG_ ESP_HOLD_verf : 63|1@1+ (1.0,0.0) [0.0|1] ""  OTA_FC

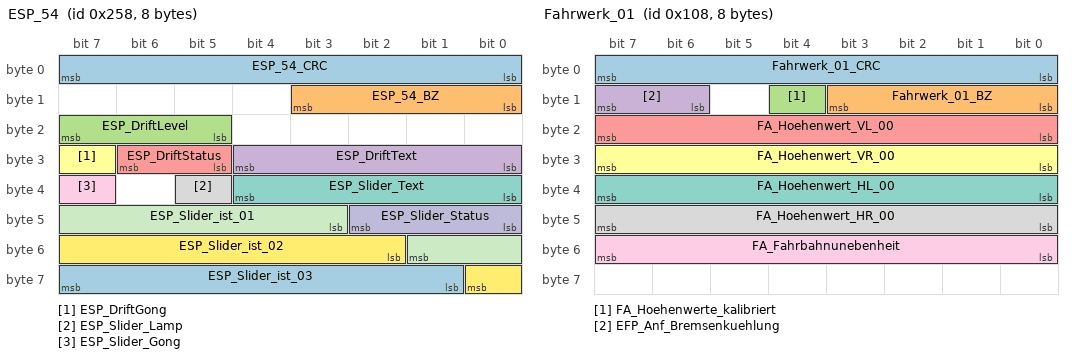
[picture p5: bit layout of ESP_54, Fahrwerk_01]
BO_ 600 ESP_54: 8 Gateway
 SG_ ESP_54_CRC : 0|8@1+ (1,0) [0|255] ""  ZR_LIMU
 SG_ ESP_54_BZ : 8|4@1+ (1,0) [0|15] ""  ZR_LIMU
 SG_ ESP_DriftLevel : 21|3@1+ (1.0,0.0) [0.0|7] ""  Vector__XXX
 SG_ ESP_DriftText : 24|5@1+ (1.0,0.0) [0.0|31] ""  Vector__XXX
 SG_ ESP_DriftStatus : 29|2@1+ (1.0,0.0) [0.0|3] ""  Vector__XXX
 SG_ ESP_DriftGong : 31|1@1+ (1.0,0.0) [0.0|1] ""  Vector__XXX
 SG_ ESP_Slider_Text : 32|5@1+ (1.0,0.0) [0.0|31] ""  ZR_LIMU
 SG_ ESP_Slider_Lamp : 37|1@1+ (1.0,0.0) [0.0|1] ""  Vector__XXX
 SG_ ESP_Slider_Gong : 39|1@1+ (1.0,0.0) [0.0|1] ""  Vector__XXX
 SG_ ESP_Slider_Status : 40|3@1+ (1.0,0.0) [0.0|7] ""  ZR_LIMU
 SG_ ESP_Slider_ist_01 : 43|7@1+ (1,0) [0|126] ""  ZR_LIMU
 SG_ ESP_Slider_ist_02 : 50|7@1+ (1,0) [0|126] ""  ZR_LIMU
 SG_ ESP_Slider_ist_03 : 57|7@1+ (1,0) [0|126] ""  ZR_LIMU

BO_ 264 Fahrwerk_01: 8 Gateway
 SG_ Fahrwerk_01_CRC : 0|8@1+ (1,0) [0|255] ""  Vector__XXX
 SG_ Fahrwerk_01_BZ : 8|4@1+ (1,0) [0|15] ""  Vector__XXX
 SG_ FA_Hoehenwerte_kalibriert : 12|1@1+ (1.0,0.0) [0.0|1] ""  ZR_High
 SG_ EFP_Anf_Bremsenkuehlung : 14|2@1+ (1.0,0.0) [0.0|3] ""  Vector__XXX
 SG_ FA_Hoehenwert_VL_00 : 16|8@1+ (1,-127) [-127|126] "Unit_MilliMeter"  DDA,OTA_FC,ZR_High
 SG_ FA_Hoehenwert_VR_00 : 24|8@1+ (1,-127) [-127|126] "Unit_MilliMeter"  DDA,OTA_FC,ZR_High
 SG_ FA_Hoehenwert_HL_00 : 32|8@1+ (1,-127) [-127|126] "Unit_MilliMeter"  DDA,OTA_FC,ZR_High
 SG_ FA_Hoehenwert_HR_00 : 40|8@1+ (1,-127) [-127|126] "Unit_MilliMeter"  DDA,OTA_FC,ZR_High
 SG_ FA_Fahrbahnunebenheit : 48|8@1+ (1,0) [0|253] ""  OTA_FC,ZR_High

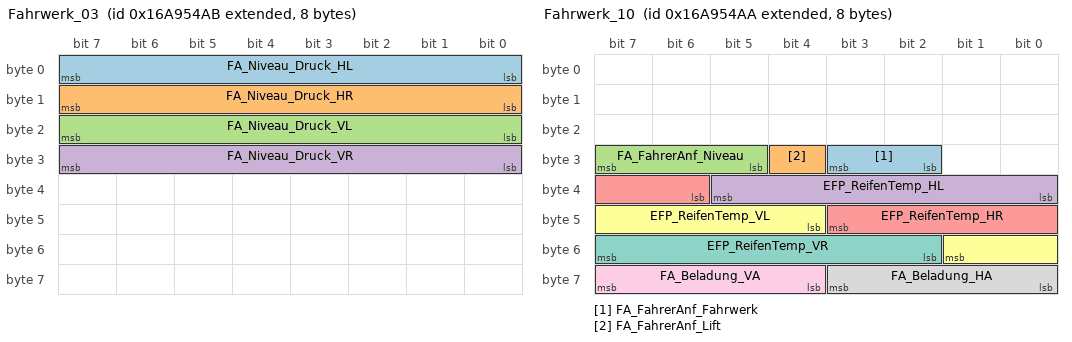
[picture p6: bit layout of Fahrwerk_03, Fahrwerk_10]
BO_ 2527679659 Fahrwerk_03: 8 Gateway
 SG_ FA_Niveau_Druck_HL : 0|8@1+ (0.1,0) [0.0|25.3] "Unit_Bar"  OTA_FC,ZR_High
 SG_ FA_Niveau_Druck_HR : 8|8@1+ (0.1,0) [0.0|25.3] "Unit_Bar"  OTA_FC,ZR_High
 SG_ FA_Niveau_Druck_VL : 16|8@1+ (0.1,0) [0.0|25.3] "Unit_Bar"  OTA_FC,ZR_High
 SG_ FA_Niveau_Druck_VR : 24|8@1+ (0.1,0) [0.0|25.3] "Unit_Bar"  OTA_FC,ZR_High

BO_ 429 Fahrwerk_06: 8 Gateway
 SG_ Fahrwerk_06_CRC : 0|8@1+ (1,0) [0|255] ""  Vector__XXX
 SG_ Fahrwerk_06_BZ : 8|4@1+ (1,0) [0|15] ""  Vector__XXX
 SG_ NR_Reglerstatus : 12|4@1+ (1.0,0.0) [0.0|15] ""  OTA_FC,ZR_High
 SG_ FA_Verstellung_in_Kuerze : 16|1@1+ (1.0,0.0) [0.0|1] ""  ZR_High
 SG_ FA_Verstellung_aktiv : 17|1@1+ (1.0,0.0) [0.0|1] ""  ZR_High
 SG_ FA_Kompressor_laeuft_in_Kuerze : 18|1@1+ (1.0,0.0) [0.0|1] ""  Vector__XXX
 SG_ FA_Kompressor_laeuft : 19|1@1+ (1.0,0.0) [0.0|1] ""  OTA_FC
 SG_ NR_Anforderung_v_Begrenzung : 20|2@1+ (1.0,0.0) [0.0|3] ""  Vector__XXX
 SG_ NR_LED_SGN : 22|1@1+ (1.0,0.0) [0.0|1] ""  ZR_High
 SG_ NR_LED_TN : 23|1@1+ (1.0,0.0) [0.0|1] ""  ZR_High
 SG_ NR_LED_BN : 24|1@1+ (1.0,0.0) [0.0|1] ""  ZR_High
 SG_ FA_Absenkung_Fahrzeug : 25|1@1+ (1.0,0.0) [0.0|1] ""  OTA_FC,ZR_High
 SG_ FA_Anhaengerstatus_intern : 26|3@1+ (1.0,0.0) [0.0|7] ""  OTA_FC,ZR_High
 SG_ FA_Anhebung_Fahrzeug : 29|1@1+ (1.0,0.0) [0.0|1] ""  OTA_FC,ZR_High
 SG_ FA_Druckspeicher_verfuegbar : 30|1@1+ (1.0,0.0) [0.0|1] ""  OTA_FC
 SG_ FA_HAL_Abschaltung : 31|1@1+ (1.0,0.0) [0.0|1] ""  OTA_FC
 SG_ FA_ESP_Zuschaltung : 32|1@1+ (1.0,0.0) [0.0|1] ""  OTA_FC
 SG_ NR_LED_HN : 33|1@1+ (1.0,0.0) [0.0|1] ""  OTA_FC,ZR_High
 SG_ FA_Zwischenniveau : 34|1@1+ (1.0,0.0) [0.0|1] ""  OTA_FC
 SG_ FA_Systemstatus : 35|1@1+ (1.0,0.0) [0.0|1] ""  ZR_High
 SG_ EFP_Soll_FahrPr_HAL : 36|4@1+ (1.0,0.0) [0.0|15] ""  Vector__XXX
 SG_ NR_Kompressor_Strom_02 : 40|8@1+ (0.2,0) [0.0|50.8] "Unit_Amper"  OTA_FC
 SG_ NR_Kompressor_Temp_Zylinderkopf : 48|8@1+ (1,-40) [-40|213] "Unit_DegreCelsi"  OTA_FC
 SG_ FA_Signal_Drucksensor : 56|8@1+ (0.1,0) [0.0|25.3] "Unit_Bar"  OTA_FC

BO_ 2527679658 Fahrwerk_10: 8 Gateway
 SG_ FA_FahrerAnf_Fahrwerk : 26|2@1+ (1.0,0.0) [0.0|3] ""  OTA_FC,ZR_MIB_TOP_ab_Gen3
 SG_ FA_FahrerAnf_Lift : 28|1@1+ (1.0,0.0) [0.0|1] ""  OTA_FC,ZR_MIB_TOP_ab_Gen3
 SG_ FA_FahrerAnf_Niveau : 29|3@1+ (1.0,0.0) [0.0|7] ""  OTA_FC,ZR_MIB_TOP_ab_Gen3
 SG_ EFP_ReifenTemp_HL : 32|6@1+ (2,-25) [-25|99] "Unit_DegreCelsi"  OTA_FC
 SG_ EFP_ReifenTemp_HR : 38|6@1+ (2,-25) [-25|99] "Unit_DegreCelsi"  OTA_FC
 SG_ EFP_ReifenTemp_VL : 44|6@1+ (2,-25) [-25|99] "Unit_DegreCelsi"  OTA_FC
 SG_ EFP_ReifenTemp_VR : 50|6@1+ (2,-25) [-25|99] "Unit_DegreCelsi"  OTA_FC
 SG_ FA_Beladung_HA : 56|4@1+ (50,0) [0|650] "Unit_KiloGram"  ZR_High
 SG_ FA_Beladung_VA : 60|4@1+ (50,0) [0|650] "Unit_KiloGram"  ZR_High

BO_TX_BU_ 496 :Gateway,Gateway_PAG;
BO_TX_BU_ 2527679980 :Gateway,Gateway_PAG;
BO_TX_BU_ 996 :Gateway,Gateway_PAG;
BO_TX_BU_ 1603 :Gateway,Gateway_PAG;
BO_TX_BU_ 1622 :Gateway,Gateway_PAG;
BO_TX_BU_ 260 :Gateway,Gateway_PAG;
BO_TX_BU_ 781 :Gateway,Gateway_PAG;
BO_TX_BU_ 259 :Gateway,Gateway_PAG;
BO_TX_BU_ 262 :Gateway,Gateway_PAG;
BO_TX_BU_ 914 :Gateway,Gateway_PAG;
BO_TX_BU_ 278 :Gateway,Gateway_PAG;
BO_TX_BU_ 418 :Gateway,Gateway_PAG;
BO_TX_BU_ 1629 :Gateway,Gateway_PAG;
BO_TX_BU_ 253 :Gateway,Gateway_PAG;
BO_TX_BU_ 239 :Gateway,Gateway_PAG;
BO_TX_BU_ 1470 :Gateway,Gateway_PAG;
BO_TX_BU_ 795 :Gateway,Gateway_PAG;
BO_TX_BU_ 508 :Gateway,Gateway_PAG;
BO_TX_BU_ 264 :Gateway,Gateway_PAG;
BO_TX_BU_ 2527679659 :Gateway,Gateway_PAG;
BO_TX_BU_ 429 :Gateway,Gateway_PAG;
BO_TX_BU_ 2527679658 :Gateway,Gateway_PAG;
CM_ BO_ 1603 "ab MQB mit 8 Byte";
CM_ BO_ 260 "ab MQB mit CRC-8";
CM_ BO_ 259 "MLBevo - CRC-Absicherung";
CM_ BO_ 418 "MLBevo verlangsamte 100ms-Botschaft";
CM_ BO_ 1629 "neu im MQB";
CM_ BO_ 253 "Neue Momente im MQB
Struktur ab MQB mit CRC8 entstanden aus ESP_01";
CM_ BO_ 1470 "MSS (AU724/5, LBxxx) Botschaft zur Offsetkompentation";
CM_ BO_ 795 "neu für MQB wg. Absicherung
Entstanden aus ESP_04";
CM_ BO_ 508 "CAN-Botschaft";
CM_ BO_ 264 "ab MLBevo mit CRC";

CM_ SG_ 496 ACF_Lampe_Hands_Off "Anzeige, ob der Fahrer die Hände am Lenkrad hat.";
CM_ SG_ 496 EA_02_BZ "Botschaftszähler
Botschaft asynchron geroutet. Zählerwert kann springen.";
CM_ SG_ 496 EA_02_CRC "Für MLB:
'Berechnung siehe Lastenheft 'Kommunikationsabsicherung für Flexray und CAN''

Ab MQB und MLBevo:
'Berechnung siehe Lastenheft 'End-to-End Kommunikationsabsicherung'

Endwerte siehe Begleitdokument 'S-PDU Kennungsfolge'";
CM_ SG_ 496 EA_Blinken "Emergency Assist Anforderung Blinker";
CM_ SG_ 496 EA_Bremslichtblinken "Die Funktion Emergency Alert fordert ein Blinken der Bremsleuchten an.";
CM_ SG_ 496 EA_Infotainment_Anf "Emergency Assist Anforderung Absenkung Infotainment-Funktionen";
CM_ SG_ 496 EA_Innenraumlicht_Anf "Anforderung Innenraumbeleuchtung durch den Emergency Assist";
CM_ SG_ 496 EA_Texte "Anzeige der EA Texte";
CM_ SG_ 496 EA_Tueren_Anf "Emergency Assist Anforderung Türen entriegeln";
CM_ SG_ 496 STP_Primaeranz "Primäranzeige des Staupiloten";
CM_ SG_ 496 zFAS_Warnblinken "Anforderung Warnblinken durch zFAS Funktionen.";

CM_ SG_ 2527679980 bCall_active "1: Breakdown call is active
0: BreakdownCall is inactive";
CM_ SG_ 2527679980 eCall_Funktionsstatus "HMI-Aufruf im Kombi (Broadcast)
Fehlerfälle die im Kombi angezeigt werden können";
CM_ SG_ 2527679980 eCall_Funktionsstatus_02 "Erweiterung des Funktionsstatus für andere Funktionen
ACN aktiv, MEC aktiv
MEC = manual emergency call = maueller Notruf
ACN = automatic emergency call = automatischer Notruf";
CM_ SG_ 2527679980 eCall_Mute_Anf "Signalisiert die Aufforderungen alle Soundquellen im Fahrzeug während eines aktiven Notrufs zu muten";
CM_ SG_ 2527679980 eCall_Statuslicht_Farbe1 "Steuerung Statuslicht (Farbe1) für Funktionsrückmeldungen Emergency Call / SOS Hilferuf,
z.B. LED-Anzeige im Dachmodul.";
CM_ SG_ 2527679980 eCall_Statuslicht_Farbe2 "Steuerung Statuslicht (Farbe2) für Funktionsrückmeldungen Emergency Call / SOS Hilferuf,
z.B. LED-Anzeige im Dachmodul.";
CM_ SG_ 2527679980 eCall_Subscription "Anzeige 'Service Unsubscribed' im Kombi - Aktualisierte Namensgebung";

CM_ SG_ 996 EFF_Einsparhinweis "Anforderung der Anzeige von veschiedenen Life-Tipps";
CM_ SG_ 996 EFF_Verbrauch_STH "Verbrauchsanteil der Standheizung im Komfortverbrauch (siehe EFF_Verbraucher_Balken)";
CM_ SG_ 996 EFF_Verbraucher_Balken "Anzeige der Zusatzverbraucher (Anzeige 0-5,09 l/h in 0,01 l/h - Schritten) für BCmE (Bordcomputer mit Effizienzprogramm)";
CM_ SG_ 996 EFF_Verbraucher_Pos_1 "Name des Zusatzverbraucher an Listenposition '1' der Top-Verbraucher für die Balkenanzeige 'Zusatzverbraucher'";
CM_ SG_ 996 EFF_Verbraucher_Pos_2 "Name des Zusatzverbraucher an Listenposition '2' der Top-Verbraucher für die Balkenanzeige 'Zusatzverbraucher'";
CM_ SG_ 996 EFF_Verbraucher_Pos_3 "Name des Zusatzverbraucher an Listenposition '3' der Top-Verbraucher für die Balkenanzeige 'Zusatzverbraucher'";
CM_ SG_ 996 MKE_FAS "Sicherheitshinweis für FAS.";
CM_ SG_ 996 MKE_FAS_Fkt_Status "Statussignal für FAS-Profilemaster.";
CM_ SG_ 996 MKE_Fehlercode "Fehlercode der Funktion Müdigkeitserkennung.";
CM_ SG_ 996 MKE_Stufe "Das Signal bildet die Müdigkeitsstufe im Kombi ab:
0 - deaktiviert
1 - nicht_verfügbar
2 - Stufe_1
3 - Stufe_2
4 - Stufe_3
5 - Stufe_4
6 - reserviert
7 - reserviert";
CM_ SG_ 996 MKE_Texte "Systemhinweis und Sicherheitshinweis für Anzeige im Kombi";

CM_ SG_ 1603 KBI_Einheit_Datum "Anzeigevariante des Datums";
CM_ SG_ 1603 KBI_Einheit_Druck "Einheit des Druckes";
CM_ SG_ 1603 KBI_Einheit_Masse "Einheit der Masse (Verwendung z.B. ASTA)";
CM_ SG_ 1603 KBI_Einheit_Sprache "Siehe BAP-Datenfestlegung UnitMaster";
CM_ SG_ 1603 KBI_Einheit_Streckenanz "Einheit der Streckenanzeige";
CM_ SG_ 1603 KBI_Einheit_Temp "Einheit der Temperatur";
CM_ SG_ 1603 KBI_Einheit_Uhrzeit "Anzeigevariante der Uhrzeit";
CM_ SG_ 1603 KBI_Einheit_Verbrauch "Einheit der Verbrauchs";
CM_ SG_ 1603 KBI_Einheit_Verbrauch_elektr "Einheit elektrischer Verbrauch";
CM_ SG_ 1603 KBI_Einheit_Verbrauch_Gas "Unterscheidung zwischen M3/h und kg/h für Komfortverbrauchsberechnung.";
CM_ SG_ 1603 KBI_Einheit_Volumen "Einheit des Volumens";
CM_ SG_ 1603 KBI_MFA_v_Einheit_02 "Einheit der Geschwindigkeit, die vom Fahrer im Car-Menü gewählt wurde. Veränderliche Grösse, im Gegensatz zur Einheit des Tachokranzes.

Redundant in der Einheiten_01 Botschaft definiert, um Konsistenz zur BAP-Festlegung zu haben.";

CM_ SG_ 1622 ELV_01_BZ "4bit Botschaftszaehler, wird mit jeder Sendebotschaft inkrementiert";
CM_ SG_ 1622 ELV_01_CRC "Ab MQB und MLBevo:
'Berechnung siehe Lastenheft 'End-to-End Kommunikationsabsicherung''

Endwerte siehe Begleitdokument 'S-PDU Kennungsfolgen'";
CM_ SG_ 1622 ELV_01_Sendestatus "Zeigt an, ob die ELV für einen begrenzten Zeitraum mit verkürzter Zykluszeit (50ms) sendet. Das ist bis zur KL15ein notwendig, um eine Motorstartverzögerung zu vermeiden.";
CM_ SG_ 1622 ELV_Abbruch_Anf_Klemmenfreigabe "Klemmenanforderung des Kessy-SG wird von der ELV verworfen und muss vom Kessy zurückgenommen werden.";
CM_ SG_ 1622 ELV_Anf_Klemme_15 "Signal wird zur Plausibilisierung parrallel zum Klemmensignal auf dem CAN übertragen
Anforderung Klemme_15";
CM_ SG_ 1622 ELV_Anf_Klemme_50 "Signal wird zur Plausibilisierung parrallel zum Klemmensignal auf dem CAN übertragen
Anforderung Klemme_50";
CM_ SG_ 1622 ELV_Anf_Klemme_S "Signal wird zur Plausibilisierung parallel zum Klemmensignal auf dem CAN übertragen
Anforderung Klemme_S";
CM_ SG_ 1622 ELV_Anlernmodus "Im Anlernmodus (1) ist zum Einschalten der KLS u.KL15 keine Authentifizierung der WFS notwendig. KL50 ist nicht einschaltbar.
Auslieferungszustand ist (1)";
CM_ SG_ 1622 ELV_Entriegelt "ELV im Zustand entriegelt
";
CM_ SG_ 1622 ELV_Klemmenfreigabe "Freigabe/Quittierung der ELV für das Einschalten der Klemme 15 und Klemme S";
CM_ SG_ 1622 ELV_Lebenszustand "Auslieferungszustand ist (0)
Lebenszustand";
CM_ SG_ 1622 ELV_LED_Gelb "Warnlampe Gelb";
CM_ SG_ 1622 ELV_LED_Rot "Warnlampe Rot";
CM_ SG_ 1622 ELV_P_verriegelt "Position P-verriegelt vom Gangwahlhebel";
CM_ SG_ 1622 ELV_Txt_Bremse "Text: 'Bremspedal betätigen!'";
CM_ SG_ 1622 ELV_Txt_Defekt "Text: 'Lenkungsverriegelung defekt!'";
CM_ SG_ 1622 ELV_Txt_Kupplung "Text: 'Kupplungspedal betätigen!'";
CM_ SG_ 1622 ELV_Txt_Lkg_Bewegen "Text: 'Lenkrad bewegen!'";
CM_ SG_ 1622 ELV_Txt_P_Gang "Text: 'Wählhebel in Position P bringen!'";
CM_ SG_ 1622 ELV_Txt_Panikabschaltung "Text: 'Notabschaltung''";
CM_ SG_ 1622 ELV_Txt_PN_Gang "Text: 'Wählhebel in Position P/N bringen!'";
CM_ SG_ 1622 ELV_Txt_Werkstatt "Text: 'Lenkungsverriegelung! Werkstatt!'";
CM_ SG_ 1622 ELV_Verriegelt "ELV im Zustand verriegelt
";
CM_ SG_ 1622 ELV_ZAT_betaetigt "Zündanlass-Taster (ZAT) betätigt";

CM_ SG_ 260 EPB_01_BZ "Botschaft asynchron geroutet. Zählerwert kann springen.";
CM_ SG_ 260 EPB_01_CRC "Für MLB:
'Berechnung siehe Lastenheft 'Kommunikationsabsicherung für FlexRay und CAN''

Ab MQB und MLBevo:
'Berechnung siehe Lastenheft 'End-to-End Kommunikationsabsicherung''

Endwerte siehe Begleitdokument 'S-PDU Kennungsfolgen'";
CM_ SG_ 260 EPB_DAA_Randbed_erf "Die Randbedingungen zum automatischen Öffnen der EPB (Funktion DAA) sind erfüllt und ein Betätigen des Fahrpedals führt zum Öffnen der EPB.";
CM_ SG_ 260 EPB_Fehlerstatus_02 "Anpassung der Texte an die  aktuellen Zustände für weitergehende Funktionen (Stillstandsmanager)";
CM_ SG_ 260 EPB_Freig_Verzoeg_Anf "Verzögerungsanforderung	";
CM_ SG_ 260 EPB_Pedalweg_Kuppl "Signal entspricht Tastverhältnis des PWM. Gesamtweg Kupplungspedal 10% bis 90%, damit zu erwartende Werte 25 bis 225. 25 bei Kupplungspedal nicht getreten, 225 bei Kupplungspedal voll durchgetreten.
2% Toleranz wird im Wertebereich ermöglicht (8%-92%).
";
CM_ SG_ 260 EPB_Schalterposition "Spiegelt die Schalterstellung wieder.

0x3 = Schalterfehler ";
CM_ SG_ 260 EPB_Spannkraft "Erzeugte Spannkraft. Bezieht sich auf die Aktuatoren.

MQB: Spannkraftwerte entsprechen nicht den tatsächlichen Spannkräften. Genauere Informationen bitte in der Fachabteilung erfragen! ";
CM_ SG_ 260 EPB_Status_02 "Erweiterung der Zustände um ein genaueres Bild des aktuellen Zustandes zu erhalten für weitergehende Funktionen ( Stillstandsmanager)
";
CM_ SG_ 260 EPB_Verzoeg_Anf "Steuerungsanforderung an andere Systeme (z.B. ESP), um während der Fahrt, durch den Handbremsschalter ausgelöst, zu bremsen (ECD-Funktion)";

CM_ SG_ 781 EPB_Akustik "Bit wird gesetzt, wenn bei v > 0 eine Fahreran-forderung schließen vorhanden ist (ECD angefordert). PQ46-Kombi sendet Warnton (600Hz) solange dieses Bit gesetzt ist.
Anzeige eines Warntextes
";
CM_ SG_ 781 EPB_Autoholdlampe "Autoholdlampe im Kombi, grünes P
";
CM_ SG_ 781 EPB_Bremsbelag_Warn "Mindestens ein Bremsbelag an der Hinterachse am Fahrzeug ist unter Minimum";
CM_ SG_ 781 EPB_Fehlerlampe_BKL "Die BKL dient als rote Fehlerlampe für die EPB. Sie wird vom EPB-SG aktiv ausgeschaltet.";
CM_ SG_ 781 EPB_Fehlerlampe_Gelb "Fehlerlampe für nicht liegenbleiberreleavante Fehler";
CM_ SG_ 781 EPB_Fehlermeldungen "Über das Signal werden bestimmte Fehlertexte und -lampen im Kombi angefordert.";
CM_ SG_ 781 EPB_Funktionslampe "Bit wird nur gesetzt, wenn volle Spannkraft auf beiden Seiten erreicht. PQ46: Bit wird gesetzt, wenn BKL direkt vom EPB-SG als Funktionslampe angesteuert wird.

Bei Audi: Rote Lampe (rotes P) im Kombiinstrument
";
CM_ SG_ 781 EPB_Texte "EPB-Texte für Kombi
9 bei Audi aktuell nicht bedient.
10 bei Audi hinzugefügt für RSe
11 bei PAG Duo Servo Parkbremse aktuell nicht bedient 
12 bei PAG Duo Servo Parkbremse aktuell nicht bedient 
13 nur bei ParkPilot/IPA verwendet";

CM_ SG_ 259 ESP_03_BZ "Botschaft asynchron geroutet. Zählerwert kann springen.";
CM_ SG_ 259 ESP_03_CRC "Ab MQB und MLBevo:
'Berechnung siehe Lastenheft 'End-to-End Kommunikationsabsicherung''

Endwerte siehe Begleitdokument 'S-PDU Kennungsfolgen'";
CM_ SG_ 259 ESP_HL_FR "Fahrtrichtungserkennung Rad Hinten Links
";
CM_ SG_ 259 ESP_HL_Radgeschw "Radgeschwindigkeit hinten links";
CM_ SG_ 259 ESP_HR_FR "Fahrtrichtungserkennung Rad Hinten Rechts
";
CM_ SG_ 259 ESP_HR_Radgeschw "Radgeschwindigkeit hinten rechts";
CM_ SG_ 259 ESP_VL_FR "Fahrtrichtungserkennung Rad Vorne Links
";
CM_ SG_ 259 ESP_VL_Radgeschw "Radgeschwindigkeit vorne links";
CM_ SG_ 259 ESP_VR_FR "Fahrtrichtungserkennung Rad Vorne Rechts

";
CM_ SG_ 259 ESP_VR_Radgeschw "Radgeschwindigkeit vorne rechts";

CM_ SG_ 262 ECD_Fehler "ESP kann die Verzögerungsregelung/Bremsenregelung aufgrund eines internen Fehlers nicht ausführen, mit Fehlereintrag im ESP.
";
CM_ SG_ 262 ECD_nicht_verfuegbar "ESP kann die Verzögerungsregelung/Bremsenregelung temporär nicht ausführen (z.B. Netzwerkmanagement-Betriebe - KL15 Aus; v<18km/h; ESP in Diagnose, ...), ohne Fehlereintrag im ESP.

";
CM_ SG_ 262 ESC_Bremslicht "Die Bremslichtansteuerung erfolgt, wenn die Ist_Verzögerung für eine Dauer von  (ca.100 ms) die bewertete Verzögerungsschwelle unterschreitet (Einschaltschwelle Bremslicht),  Bremsdruck vorhanden aufgrund ECD , EMP, HMS oder HDC. Bei AWV2 wird von Beginn ";
CM_ SG_ 262 ESP_05_BZ "Botschaft asynchron geroutet. Zählerwert kann springen.";
CM_ SG_ 262 ESP_05_CRC "Für MLB:
'Berechnung siehe Lastenheft 'Kommunikationsabsicherung für FlexRay und CAN''

Ab MQB und MLBevo:
'Berechnung siehe Lastenheft 'End-to-End Kommunikationsabsicherung''

Endwerte siehe Begleitdokument 'S-PDU Kennungsfolgen'";
CM_ SG_ 262 ESP_Anforderung_EPB "ESP fordert von der EPB Öffnen bzw. Schliessen an. Notwendig wegen Autohold-Funktion.";
CM_ SG_ 262 ESP_Autohold_aktiv "Rückmeldung an EPB, dass Autohold aktiv ist.";
CM_ SG_ 262 ESP_Autohold_Standby "Rückmeldung an EPB, dass der Fahrer die Funktion Autohold mindestens einmal angefordert hat. Im Fall eines ESP-Ausfalles oder einer Übernahmeaufforderung erfolgt die EPB-Zuschaltung nur nach Setzen dieses Bits. Bit wird gesetzt nach Betätigung des Autohol";
CM_ SG_ 262 ESP_BKV_Unterdruck "Der maximale Wert wird auf 1012 mbar begrenzt.
Dieses Signal wird im AU64x nicht unterstützt.

Hinweis: Auch bei nicht verbautem BKV-Unterdrucksensor könnte während der Initialisierung der Initialisierungswert gesendet werden.";
CM_ SG_ 262 ESP_Bremsdruck "Rohwert des Bremsdrucks
Für Fahrzeuge mit elektrischem Bremskraftverstärker gilt: Aus dem Signal ESP_Bremsdruck lässt sich kein Fahrerbremswunsch ableiten. Das Signal bildet lediglich den hydraulischen Anteil der Fahrzeugverzögerung ab. Der Rohwert des S";
CM_ SG_ 262 ESP_Eingr_HL "wird von QSP und Neigungsanzeige verwendet

Flag wird vom ESP gesetzt, sobald aufgrund eines ESP-Eingriffs am Rad aktiv Druck aufgebaut wird.
Frühestens mit öffnen des Ventils und spätestens bei einem Bremsmoment von 100Nm. Flag bleibt solange gesetzt ";
CM_ SG_ 262 ESP_Eingr_HR "wird von QSP und Neigungsanzeige verwendet

Flag wird vom ESP gesetzt, sobald aufgrund eines ESP-Eingriffs am Rad aktiv Druck aufgebaut wird.
Frühestens mit öffnen des Ventils und spätestens bei einem Bremsmoment von 100Nm. Flag bleibt solange gesetzt ";
CM_ SG_ 262 ESP_Eingr_VL "wird von QSP und Neigungsanzeige verwendet

Flag wird vom ESP gesetzt, sobald aufgrund eines ESP-Eingriffs am Rad aktiv Druck aufgebaut wird.
Frühestens mit öffnen des Ventils und spätestens bei einem Bremsmoment von 100Nm. Flag bleibt solange gesetzt ";
CM_ SG_ 262 ESP_Eingr_VR "wird von QSP und Neigungsanzeige verwendet

Flag wird vom ESP gesetzt, sobald aufgrund eines ESP-Eingriffs am Rad aktiv Druck aufgebaut wird.
Frühestens mit öffnen des Ventils und spätestens bei einem Bremsmoment von 100Nm. Flag bleibt solange gesetzt ";
CM_ SG_ 262 ESP_Fahrer_bremst "Bit wird gesetzt beim Überschreiten der Bremsdruckschwelle

Weiterführende Informationen im Lastenheft spezifiziert und in der entsprechenden Fachabteilung zu erfragen.
";
CM_ SG_ 262 ESP_FStatus_Anfahrhilfe "Bei gesetztem Bit steht die Funktion Berganfahrassistent (Hillhold) nicht zur Verfügung";
CM_ SG_ 262 ESP_HBA_aktiv "Verwendung/Bedienung ab D4
Signal gibt an, ob der hydraulische Bremsassistent im Regler aktiviert wurde

Im MQB wird das Signal nicht unterstützt!

";
CM_ SG_ 262 ESP_HDC_aktiv "MQB und AU57x Allroad: Mit diesem Statusbit wird eine gerade aktive Regelung des Bergabfahrassistenten (Hill Descent Control) signalisiert.";
CM_ SG_ 262 ESP_HDC_Standby "Verwendung/Bedienung im MQB und AU57x Allroad:
Flag wird vom ESP gesetzt, wenn über den HDC-Taster die HDC-Funktion eingeschalten wurde";
CM_ SG_ 262 ESP_Lenkeingriff_ADS "Im Falle eines fahrzeugstabilisierenden Lenkeingriffs des ADS-Systems soll ACC/GRA deaktiviert werden.

Im MQB wird dieses Signal nicht unterstützt!";
CM_ SG_ 262 ESP_Prefill_ausgeloest "MLB: Verwendung/Bedienung ab D4
zeigt, ob die Funktion Prefill (aufgrund Fahrpedalgradient) ausgelöst wird; zeigt keinen Funktionszustand bezüglich Fehlerstilllegung

MQB: Wird gesetzt bei jeder Art von aktivem Prefill";
CM_ SG_ 262 ESP_QBit_Bremsdruck "QBit des Bremsdrucks. Gesetzt bei Ersatzwert, Init oder Fehler.";
CM_ SG_ 262 ESP_QBit_Fahrer_bremst "Gültigkeit der Bremsdruckschwelleninformation des Signals ESP_Fahrer_bremst vom ESP SG
0x1 = Druckschwelleninformation kann noch nicht oder aufgrund eines Fehlers nicht ausgegeben werden
";
CM_ SG_ 262 ESP_Rueckwaertsfahrt_erkannt "nur bei AU57x und AU416 sowie Audi B8PA
Info, ob Rückwärtsfahrt über internen Algorithmus sicher erkannt

Im MQB wird das Signal nicht unterstützt!";
CM_ SG_ 262 ESP_Schwelle_Unterdruck "Verwendung im MQB für HBV-Projekte oder wenn für St/St ein Unterdrucksensor verbaut ist";
CM_ SG_ 262 ESP_StartStopp_Info "Stopp-Freigabe und Start-Anforderung an den Start-Stopp-Koordinator";
CM_ SG_ 262 ESP_Status_Anfahrhilfe "Funktionsstatus des Berganfahrassistenten
MQB: Auswertung im Getriebe zwecks Standabkopplung";
CM_ SG_ 262 ESP_Status_Bremsdruck "MLB: Bei gesetztem Bit liegt p > ca. 2 bar an, hervorgerufen durch Fahrer, ASR, FZR, ECD, Bremsregler ... bei Abfall des Bits ist p < X bar, bei aktivem ECD-Eingriff Ende des Eingriffs 

Weiterführende Informationen im Lastenheft spezifiziert und in der";
CM_ SG_ 262 ESP_Status_Bremsentemp "ECD-Bremsscheibentemperaturmodell. Rückmeldung für Sender einer ECD Verzögerungsanforderung, ohne Fehlereintrag im ESP";
CM_ SG_ 262 ESP_Verz_EPB_aktiv "Bei gesetztem Bit wird die Verzögerungsanforderung von EPB umgesetzt.";
CM_ SG_ 262 ESP_Verzoeg_EPB_verf "Bei gesetztem Bit ist der Verzögerungsregeler für EPB verfügbar.";

CM_ SG_ 914 ESC_cAQP_Trigger "Trigger zur statistischen Auswertung durch die Connected Car Funktion Aquaplaning Praediktion (AQP).

Ansprechpartner: Timo Maise (PAG- EEC2)";
CM_ SG_ 914 ESP_07_BZ "Botschaft asynchron geroutet. Zählerwert kann springen.";
CM_ SG_ 914 ESP_07_CRC "Für MLB:
'Berechnung siehe Lastenheft 'Kommunikationsabsicherung für FlexRay und CAN''

Ab MQB und MLBevo:
'Berechnung siehe Lastenheft 'End-to-End Kommunikationsabsicherung''

Endwerte siehe Begleitdokument 'S-PDU Kennungsfolgen'";
CM_ SG_ 914 ESP_Allrad_Antrieb "Im MQB wird das Signal nicht unterstützt!";
CM_ SG_ 914 ESP_Codierung_ADS "ESP gibt für Empfänger im Fahrzeug aus, ob ADS verbaut/nicht verbaut ist.

Im MQB wird das Signal nicht unterstützt!
";
CM_ SG_ 914 ESP_MKB_ausloesbar "ESP hat Funktion Multi-Kollisions-Bremsung freigeschaltet";
CM_ SG_ 914 ESP_nachtr_Stopp_Anf "Dieses Signal dient dem Motor als Trigger, dass ein nachträglicher Motorstopp eingeleitet werden kann, wenn es die Bedingungen des StSt Koordinators dies zulassen. ";
CM_ SG_ 914 ESP_OBD_Status "Dieses Bit steuert die MIL-Lampe an (Motorsteuergerät reicht diese Info an Kombi weiter).";
CM_ SG_ 914 ESP_Offroad_Modus "Nur VW526: Bei Offroad-Fahrzeugen kann über einen Schalter ein Offroadmodus gewählt werden, dieser wird hier angezeigt. Bei Offroad Plus- Fahrzeugen wird hier der Offroadmodus indirekt durch das Verteilergetriebe vorgegeben (ALR_Offroad = 1) und eingespie";
CM_ SG_ 914 ESP_Qualifizierung_Antriebsart "Signal for Bentley BY83x: ESP_wheel_drive_selector

Bit qualifiziert für neue Projekte (ab D4 ff.) das Signal 'ESP_Quattro_Antrieb', d.h. ist 'ESP_Qualifizierung_Antriebsart'
auf 0x1 gesetzt, ändert sich die bisherige Bedeutung des Signals 'ESP_Quattro";
CM_ SG_ 914 ESP_Rollenmodus_Deaktivieren "Zwang zum Abbruch des Rollenmodus mit anschließender ESP-Vollfunktion.
MQB: Zwang zum Abbruch des Rollenmodus in allen Funktionsteilnehmern (Empfänger) mit anschließender ESP-Vollfunktion (Sender).
Signal wird vom ESP dauerhaft mit gültigen Werten bedat";
CM_ SG_ 914 ESP_RTA_HL "Physikalischer Wertebereich +/-5%. Der Reifentoleranzabgleich bezieht sich auf das linke Vorderrad.

physikalischer Wert = ( (Hex-Wert - 0x7F) / 2048 )*100%

Im MQB wird das Signal nicht unterstützt!";
CM_ SG_ 914 ESP_RTA_HR "Physikalischer Wertebereich +/-5%. Der Reifentoleranzabgleich bezieht sich auf das linke Vorderrad.

physikalischer Wert = ( (Hex-Wert - 0x7F) / 2048 )*100%

Im MQB wird das Signal nicht unterstützt!";
CM_ SG_ 914 ESP_RTA_VR "Physikalischer Wertebereich +/-5%. Der Reifentoleranzabgleich bezieht sich auf das linke Vorderrad.

physikalischer Wert = ( (Hex-Wert - 0x7F) / 2048 )*100%

Im MQB wird das Signal nicht unterstützt!";
CM_ SG_ 914 ESP_Stat_FallBack_eBKV "Das Signal zeigt dem eBKV an, ob seine Rückfallebene im ESP verfügbar ist.";
CM_ SG_ 914 OBD_Fehler_Radsensor_HL "Für Motor-SG (gesetzliche Vorgabe)";
CM_ SG_ 914 OBD_Fehler_Radsensor_HR "Für Motor-SG (gesetzliche Vorgabe)";
CM_ SG_ 914 OBD_Fehler_Radsensor_VL "Für Motor-SG (gesetzliche Vorgabe)";
CM_ SG_ 914 OBD_Fehler_Radsensor_VR "Für Motor-SG (gesetzliche Vorgabe)";

CM_ SG_ 278 ESP_10_BZ "Botschaftszähler

Wird im Projekt D4 und D4Hybrid nicht verwendet!  Wird im D4 PA verwendet
Botschaft asynchron geroutet. Zählerwert kann springen.";
CM_ SG_ 278 ESP_10_CRC "Für MLB:
'Berechnung siehe Lastenheft 'Kommunikationsabsicherung für FlexRay und CAN''

Ab MQB und MLBevo:
'Berechnung siehe Lastenheft 'End-to-End Kommunikationsabsicherung''

Endwerte siehe Begleitdokument 'S-PDU Kennungsfolgen'

Wird im Projekt";
CM_ SG_ 278 ESP_HL_Fahrtrichtung "Drehrichtung Rad HL

Weiterführende Informationen im Lastenheft spezifiziert und in der entsprechenden Fachabteilung zu erfragen.

Wird im Projekt D4 und D4Hybrid nicht verwendet!  Wird im D4 PA verwendet";
CM_ SG_ 278 ESP_HR_Fahrtrichtung "Drehrichtung Rad HR

Weiterführende Informationen im Lastenheft spezifiziert und in der entsprechenden Fachabteilung zu erfragen.

Wird im Projekt D4 und D4Hybrid nicht verwendet!  Wird im D4 PA verwendet";
CM_ SG_ 278 ESP_QBit_Wegimpuls_HL "Qualifizierungsbit Wegimpulszähler HL

Wird im Projekt D4 und D4Hybrid nicht verwendet!  Wird im D4 PA verwendet";
CM_ SG_ 278 ESP_QBit_Wegimpuls_HR "Qualifizierungsbit Wegimpulszähler HR

Wird im Projekt D4 und D4Hybrid nicht verwendet!  Wird im D4 PA verwendet";
CM_ SG_ 278 ESP_QBit_Wegimpuls_VL "Qualifizierungsbit Wegimpulszähler VL

Wird im Projekt D4 und D4Hybrid nicht verwendet!  Wird im D4 PA verwendet";
CM_ SG_ 278 ESP_QBit_Wegimpuls_VR "Qualifizierungsbit Wegimpulszähler VR

Wird im Projekt D4 und D4Hybrid nicht verwendet!  Wird im D4 PA verwendet";
CM_ SG_ 278 ESP_VL_Fahrtrichtung "Drehrichtung Rad VL

Weiterführende Informationen im Lastenheft spezifiziert und in der entsprechenden Fachabteilung zu erfragen.

Wird im Projekt D4 und D4Hybrid nicht verwendet!  Wird im D4 PA verwendet";
CM_ SG_ 278 ESP_VR_Fahrtrichtung "Drehrichtung Rad VR

Weiterführende Informationen im Lastenheft spezifiziert und in der entsprechenden Fachabteilung zu erfragen.

Wird im Projekt D4 und D4Hybrid nicht verwendet!  Wird im D4 PA verwendet";
CM_ SG_ 278 ESP_Wegimpuls_HL "Wegimpulszähler HL.
Anzahl der Wegimpulse Hinterrad links (steigende und fallende Flanke)
Zähler läuft grundsätzlich vorwärts, auch bei Rückwärtsfahrt.
Nach SG-Reset ist immer, ohne Ausnahme, 1mal der Init Wert 1021 zu senden.

Wird im Projekt D4 und";
CM_ SG_ 278 ESP_Wegimpuls_HR "Wegimpulszähler HR.
Anzahl der Wegimpulse Hinterrad rechts (steigende und fallende Flanke)
Zähler läuft grundsätzlich vorwärts, auch bei Rückwärtsfahrt.
Nach SG-Reset ist immer, ohne Ausnahme, 1mal der Init Wert 1021 zu senden.

Wird im Projekt D4 un";
CM_ SG_ 278 ESP_Wegimpuls_VL "Wegimpulszähler VL.
Anzahl der Wegimpulse Vorderrad links (steigende und fallende Flanke)
Zähler läuft grundsätzlich vorwärts, auch bei Rückwärtsfahrt.
Nach SG-Reset ist immer, ohne Ausnahme, 1mal der Init Wert 1021 zu senden.

Wird im Projekt D4 und";
CM_ SG_ 278 ESP_Wegimpuls_VR "Wegimpulszähler VR.
Anzahl der Wegimpulse Vorderrad rechts (steigende und fallende Flanke)
Zähler läuft grundsätzlich vorwärts, auch bei Rückwärtsfahrt.
Nach SG-Reset ist immer, ohne Ausnahme, 1mal der Init Wert 1021 zu senden.

Wird im Projekt D4 un";

CM_ SG_ 418 ESP_15_BZ "Botschaftszähler
Botschaft asynchron geroutet. Zählerwert kann springen.";
CM_ SG_ 418 ESP_15_CRC "Für MLB:
'Berechnung siehe Lastenheft 'Kommunikationsabsicherung für FlexRay und CAN''

Ab MQB und MLBevo:
'Berechnung siehe Lastenheft 'End-to-End Kommunikationsabsicherung''

Endwerte siehe Begleitdokument 'S-PDU Kennungsfolgen'

Wird im Projekt";
CM_ SG_ 418 ESP_Haltemoment "Zeigt in Abhängigkeit von ESP_Index_Haltemoment das notwendige Summen-Radmoment an (bergab: Bremsmoment; bergauf: Antriebsmoment), das mindestens notwendig ist um das Fahrzeug an der aktuellen Neigung zu halten.";
CM_ SG_ 418 ESP_Index_Haltemoment "Zeigt an, ob das Summen-Radmoment von ESP_Haltemoment ein Bremsmoment (bergab) oder ein Antriebsmoment (bergauf) darstellt.";
CM_ SG_ 418 HMS_aktives_System "Zeigt an, von welchem System die Anforderung gerade umgesetzt wird.";
CM_ SG_ 418 HMS_Anforderung_GE "Fordert vom Getriebe bestimmte Schaltstellungen an.";
CM_ SG_ 418 HMS_Fehlerstatus "Zeigt den Fehlerstatus des Haltemanagementsystems HMS an.
Details zu den Werten 3/4:
3=Systemeinschränkung, Parken EPB oder GSG nicht möglich
4=Systemstörung bzw. Parken EPB und GSG nicht möglich  ";
CM_ SG_ 418 HMS_halten_nicht_verfuegbar "Rueckmeldung HMS-Teilfunktion 'Halten' nicht verfuegbar.";
CM_ SG_ 418 HMS_Konsistenz_ACC "Zeigt an, ob die Kommunikation und die Anforderungen plausibel sind.";
CM_ SG_ 418 HMS_Konsistenz_GE "Zeigt an, ob die Kommunikation und die Anforderungen plausibel sind.";
CM_ SG_ 418 HMS_Konsistenz_HVLM "Zeigt an, ob die Kommunikation und die Anforderungen plausibel sind.";
CM_ SG_ 418 HMS_Konsistenz_IPA "Zeigt an, ob die Kommunikation und die Anforderungen plausibel sind.
";
CM_ SG_ 418 HMS_Konsistenz_MO "Zeigt an, ob die Kommunikation und die Anforderungen plausibel sind.";
CM_ SG_ 418 HMS_Konsistenz_STA "Zeigt an, ob die Kommunikation und die Anforderungen plausibel sind.";
CM_ SG_ 418 HMS_Notstopp_Status "Statusinformation des Notstoppsystems an die beteiligten Systeme.";
CM_ SG_ 418 HMS_P_beibehalten_GE "Fordert das Getriebe auf in Stellung 'P' zu bleiben.";
CM_ SG_ 418 HMS_parken_nicht_verfuegbar "Rueckmeldung HMS-Teilfunktionen 'Parken' nicht verfuegbar.";
CM_ SG_ 418 HMS_Stillstand "Das Signal zeigt, basierend auf den vier ESP-Raddrehzahlinformatioen, gefiltert und/oder entprellt mehrstufig den Fahrzeuggeschwindigkeitszustand an.";
CM_ SG_ 418 HMS_Systemstatus "Zeigt den aktuellen Systemstatus des HMS an.";
CM_ SG_ 418 NL_PRIM_STP_01_Status "Das Primär- Bremsregelsystem übermittelt seinen Systemstatus an zFAS und Sekundär- Bremsregelsystem. 

Der Staupilot ermittelt sich über den Status des Primär-und des Sekundärbremsregelsystems den Gesamtzustand des Notlaufreglers.";
CM_ SG_ 418 VMM_Warnblinken "Über dieses Signal wird ein Warnblinken von Funktionen des VMM (VehicleMotionManagers) angefordert.";
CM_ SG_ 418 VZM_Status "Zeigt die Verfuegbarkeit und den Zustand der VZM Funktionen im ESC an";

CM_ SG_ 1629 BR_QBit_Reifenumfang "Gesetzt bei Ersatzwert, Init oder Fehler.";
CM_ SG_ 1629 BR_Reifenumfang "Mittlerer Radumfang gerechnet in Millimeter.
Von der Bremse plausibilisierter Wert (Kopie von KBI_Reifenumfang wenn dieser plausibel) oder Ersatzwert aus Bremse wenn KBI_Reifenumfang unplausibel. Bitte das QBit beachten!

Im MEB wird das Signal KBI_Rei";
CM_ SG_ 1629 BR_Systemart "Identifikation des verbauten Bremssystems

Dient dem Kombi zur Plausibilisierung";
CM_ SG_ 1629 ESP_20_BZ "Botschaft asynchron geroutet. Zählerwert kann springen.";
CM_ SG_ 1629 ESP_20_CRC "Für MLB:
'Berechnung siehe Lastenheft 'Kommunikationsabsicherung für FlexRay und CAN''

Ab MQB und MLBevo:
'Berechnung siehe Lastenheft 'End-to-End Kommunikationsabsicherung''

Endwerte siehe Begleitdokument 'S-PDU Kennungsfolgen'";
CM_ SG_ 1629 ESP_Charisma_FahrPr "MLBevo: Aktuelles Fahrprogramm des Charisma-Teilnehmers (siehe Systemlastenheft Drive Select)
MQB: Istwert der Kennlinie (siehe Systemlastenheft MQB FPA)";
CM_ SG_ 1629 ESP_Charisma_Status "Systemstatus des Charismateilnehmers

Wert 0x3 ist nur für Fahrzeuge ab MQB relevant";
CM_ SG_ 1629 ESP_Dachrelingsensor "Erkennung auf Verbau des Dachrelingsensors und Dachquerträger.";
CM_ SG_ 1629 ESP_SpannungsAnf_02 "Forderung des ESP-SG's zur Spannungsanhebung.";
CM_ SG_ 1629 ESP_Stoppverbot_Anz_01 "Dieses Signal gibt die detaillierte Begründung für ein Stoppverbot vom Bremsensteuergerät an.";
CM_ SG_ 1629 ESP_Stoppverbot_Anz_02 "Dieses Signal gibt die detaillierte Begründung für ein Stoppverbot vom Bremsensteuergerät an.";
CM_ SG_ 1629 ESP_Stoppverbot_Anz_03 "Dieses Signal gibt die detaillierte Begründung für ein Stoppverbot vom Bremsensteuergerät an.";
CM_ SG_ 1629 ESP_Stoppverbot_Anz_04 "Dieses Signal gibt die detaillierte Begründung für ein Stoppverbot vom Bremsensteuergerät an.";
CM_ SG_ 1629 ESP_Stoppverbot_Anz_05 "Dieses Signal gibt die detaillierte Begründung für ein Stoppverbot vom Bremsensteuergerät an.";
CM_ SG_ 1629 ESP_Stoppverbot_Anz_06 "Dieses Signal gibt die detaillierte Begründung für ein Stoppverbot vom Bremsensteuergerät an.";
CM_ SG_ 1629 ESP_Stoppverbot_Anz_07 "Dieses Signal gibt die detaillierte Begründung für ein Stoppverbot vom Bremsensteuergerät an.";
CM_ SG_ 1629 ESP_Stoppverbot_Anz_08 "Dieses Signal gibt die detaillierte Begründung für ein Stoppverbot vom Bremsensteuergerät an.";
CM_ SG_ 1629 ESP_Stoppverbot_Anz_Std "Dieses Signal gibt die detaillierte Begründung für ein Stoppverbot vom Bremsensteuergerät an.";
CM_ SG_ 1629 ESP_Wiederstart_Anz_01 "Dieses Signal gibt die detaillierte Begründung für einen Wiederstart vom Bremsensteuergerät an. ";
CM_ SG_ 1629 ESP_Wiederstart_Anz_02 "Dieses Signal gibt die detaillierte Begründung für einen Wiederstart vom Bremsensteuergerät an. ";
CM_ SG_ 1629 ESP_Wiederstart_Anz_03 "Dieses Signal gibt die detaillierte Begründung für einen Wiederstart vom Bremsensteuergerät an. ";
CM_ SG_ 1629 ESP_Wiederstart_Anz_04 "Dieses Signal gibt die detaillierte Begründung für einen Wiederstart vom Bremsensteuergerät an.";
CM_ SG_ 1629 ESP_Zaehnezahl "Konstanter Wert der Zähnezahl des verwendeten Impulsrades wird ausgegeben, jeder Empfänger der Wegimpulse muss die Zähnezahl einlesen, um eine volle Umdrehung des Rades zu erkennen. 

Weiterführende Informationen im Lastenheft spezifiziert und in der en";
CM_ SG_ 1629 HDC_Charisma_FahrPr "MLBevo: Aktuelles Fahrprogramm des Charisma-Teilnehmers (siehe Systemlastenheft Drive Select)
MQB: Istwert der Kennlinie (siehe Systemlastenheft MQB FPA)";
CM_ SG_ 1629 HDC_Charisma_Status "Systemstatus des Charismateilnehmers

Wert 0x3 ist nur für Fahrzeuge ab MQB relevant";

CM_ SG_ 253 ABS_Bremsung "Antiblockiersystem, Bit zeigt auch Druckabbau an (z.B. ESP hat zuviel Druck aufgebaut oder ungebremste Regelung auf Bahnübergang)
Weiterführende Informationen im Lastenheft spezifiziert und in der entsprechenden Fachabteilung zu erfragen.";
CM_ SG_ 253 ASR_Anf "MLB: Die Momentenanforderung 'ASR_MSR_Moment_schnell' und 'ASR_Moment_langsam' sind auszuführen
MQB: Die Momentenanforderung 'BR_Eingriffsmoment' ist auszuführen";
CM_ SG_ 253 ASR_Schalteingriff "Wunsch an das Getriebe während einer ASR Regelung

MLB: Es wird nur 0x0 und 0x1 genutzt

";
CM_ SG_ 253 ASR_Tastung_passiv "ASR deaktiviert oder Schwellen geändert (projektabhängig)
Weiterführende Informationen im Lastenheft spezifiziert und in der entsprechenden Fachabteilung zu erfragen.
";
CM_ SG_ 253 BR_Eingriffsmoment "Einheitenloser Wert! Faktor in MO_Faktor_Momente_02 in Motor_Code_01 beachten!
Schnelle reduzierende (ASR) oder erhöhende (MSR) Momentanforderung an den Motor.";
CM_ SG_ 253 EBV_Eingriff "Elektronische Bremskraftverteilung, aktueller Eingriff (Druckhalten, Druckabbau)

Im MLB: kein ABS / ESP-Eingriff ???";
CM_ SG_ 253 EDS_Eingriff "Elektronische Differentialsperre";
CM_ SG_ 253 ESC_Neutralschaltung "Aufforderung seitens ABS an das Getriebe die Momentenübertragung zu unterbrechen";
CM_ SG_ 253 ESC_v_Signal_Qualifier_High_Low "Das Qualifizerungssignal ESC_v_Signal_Qualifier_High_Low gibt eine Information über die Güte der vom Bremsregelsystem ausgegebenen Geschwindigkeitsinformation 'mittlere Geschwindigkeit', wobei Vertrauensbereiche für das ausgegebene Geschwindigkeitssignal ";
CM_ SG_ 253 ESP_21_BZ "Botschaft asynchron geroutet. Zählerwert kann springen.";
CM_ SG_ 253 ESP_21_CRC "Für MLB:
'Berechnung siehe Lastenheft 'Kommunikationsabsicherung für FlexRay und CAN''

Ab MQB und MLBevo:
'Berechnung siehe Lastenheft 'End-to-End Kommunikationsabsicherung''

Endwerte siehe Begleitdokument 'S-PDU Kennungsfolgen'";
CM_ SG_ 253 ESP_ASP "MLB: Anhaenger-Stabilisierungs-Programm
MQB: Gespannstabilisierung";
CM_ SG_ 253 ESP_Diagnose "MLB: Nach Diagnoseende wird ein SW-Reset ausgelöst welcher einen Kommunikatiosausfall für max. 150ms verursacht. Dies ist bei SG mit verschärfter Timeoutüberwachung (nicht nach Konzern-LH) zu beachten.

MQB: Weiterführende Informationen im Lastenheft sp";
CM_ SG_ 253 ESP_Eingriff "Eingriff des Fahrdynamikreglers";
CM_ SG_ 253 ESP_QBit_v_Signal "Geschwindigkeit wird vom ABS/ASR oder ESP aus Ersatzwerten errechnet, wenn Bit gesetzt ist. Güte des Signals ist verändert.";
CM_ SG_ 253 ESP_Systemstatus "Fehler steht für Stillegung ESP mit Fehlereintrag.

MLB: Flag wird bei Unterspannung im Stand bis einmalig 6km/h (AU48x) oder 10 km/h (AU641, AU57x) überschritten nicht gesetzt (Ausblendung Startvorgang)
Im AU64x, AU57x gilt ESP D4 Funktionsanforderung";
CM_ SG_ 253 ESP_Tastung_passiv "ESP deaktiviert oder Schwellen geändert (projektabhängig)
Weiterführende Informationen im Lastenheft spezifiziert und in der entsprechenden Fachabteilung zu erfragen.";
CM_ SG_ 253 ESP_v_Signal "Geschwindigkeitssignal vom ABS/ASR oder ESP. Mittelwert der angetriebenen Räder.
Bei MSR oder ABS Eingriffen wird die ABS-Referenzgeschwindigkeit für >= 200ms eingespiegelt (Zeit wird mit Aktiv-Flanke der Funktionsbits getriggert)

MQB: Bei Frontantrie";
CM_ SG_ 253 ESP_Vorsteuerung "zur Unterscheidung zwischen ESP-Vorsteuermaßnahmen und ESP-Regeleingriffen";
CM_ SG_ 253 MSR_Anf "MLB: Die Momentenanforderung 'ASR_MSR_Moment_schnell' ist auszuführen.
MQB: Die Momentenanforderung 'BR_Eingriffsmoment' ist auszuführen";
CM_ SG_ 253 OBD_Schlechtweg "Für Ausblendung der Zündaussetzererkennung im Motorsteuergerät (Otto). Bit wird gesetzt, wenn Rad-Drehbeschleunigung im ESP > Grenzwert ist. Vorteil gegenüber Radgeschwindigkeiten, dass ESP alle 2 ms dynamisch die Rad-Drehbeschleunigung errechnet und dem ";

CM_ SG_ 239 ESP_22_BZ "Botschaft asynchron geroutet. Zählerwert kann springen.";
CM_ SG_ 239 ESP_22_CRC "Für MLB:
'Berechnung siehe Lastenheft 'Kommunikationsabsicherung für FlexRay und CAN''

Ab MQB und MLBevo:
'Berechnung siehe Lastenheft 'End-to-End Kommunikationsabsicherung''

Endwerte siehe Begleitdokument 'S-PDU Kennungsfolgen'";
CM_ SG_ 239 ESP_FZR_uebersteuern "Fahrzeug erkennt uebersteuern";
CM_ SG_ 239 ESP_FZR_untersteuern "Fahrzeug erkennt untersteuern";
CM_ SG_ 239 ESP_HL_Bremsmoment "Bremsmoment HL
Ausgabe nach LAH: Ausgabe der internen Radbremsmomente / Radbremsdrücke / durch das ESP";
CM_ SG_ 239 ESP_HR_Bremsmoment "Bremsmoment HR
Ausgabe nach LAH: Ausgabe der internen Radbremsmomente / Radbremsdrücke / durch das ESP";
CM_ SG_ 239 ESP_QBit_HL_Bremsmoment "QBit Bremsmoment HL
Ausgabe nach LAH: Ausgabe der internen Radbremsmomente / Radbremsdrücke / durch das ESP.
Ersatzwert = Eingeschränkte Genauigkeit des zugehörigen Bremsmoments (ESP-Regelung: aktiver Druckauf/abbau)";
CM_ SG_ 239 ESP_QBit_HR_Bremsmoment "QBit Bremsmoment HR
Ausgabe nach LAH: Ausgabe der internen Radbremsmomente / Radbremsdrücke / durch das ESP.
Ersatzwert = Eingeschränkte Genauigkeit des zugehörigen Bremsmoments (ESP-Regelung: aktiver Druckauf/abbau)";
CM_ SG_ 239 ESP_QBit_VL_Bremsmoment "QBit Bremsmoment VL
Ausgabe nach LAH: Ausgabe der internen Radbremsmomente / Radbremsdrücke / durch das ESP.
Ersatzwert = Eingeschränkte Genauigkeit des zugehörigen Bremsmoments (ESP-Regelung: aktiver Druckauf/abbau)";
CM_ SG_ 239 ESP_QBit_VR_Bremsmoment "QBit Bremsmoment VR
Ausgabe nach LAH: Ausgabe der internen Radbremsmomente / Radbremsdrücke / durch das ESP.
Ersatzwert = Eingeschränkte Genauigkeit des zugehörigen Bremsmoments (ESP-Regelung: aktiver Druckauf/abbau)";
CM_ SG_ 239 ESP_VL_Bremsmoment "Bremsmoment VL
Ausgabe nach LAH: Ausgabe der internen Radbremsmomente / Radbremsdrücke / durch das ESP";
CM_ SG_ 239 ESP_VR_Bremsmoment "Bremsmoment VR
Ausgabe nach LAH: Ausgabe der internen Radbremsmomente / Radbremsdrücke / durch das ESP";

CM_ SG_ 1470 BR_QBit_Reifenumfang_sekundaer "QBit des Signals BR_Reifenumfang_sekundaer. 
Gesetzt bei Ersatzwert, Init oder Fehler.";
CM_ SG_ 1470 BR_Reifenumfang_sekundaer "Radumfang der Sekundärchse gerechnet in Millimeter.
Von der Bremse plausibilisierter Wert (Kopie von KBI_Reifenumfang_sekundaer wenn dieser plausibel) 
oder Ersatzwert aus Bremse wenn KBI_Reifenumfang_sekundaer unplausibel. Bitte das QBit beachten!
";
CM_ SG_ 1470 ESP_23_CRC "Für MLB:
'Berechnung siehe Lastenheft 'Kommunikationsabsicherung für FlexRay und CAN''

Ab MQB und MLBevo:
'Berechnung siehe Lastenheft 'End-to-End Kommunikationsabsicherung''

Endwerte siehe Begleitdokument 'S-PDU Kennungsfolgen'";
CM_ SG_ 1470 ESP_Gierrate_Offset_2 "Gierratenoffset berechnet durch ESP-Modell. 

nur für MLBevo gilt:
Der Offsetwert entspricht der Abweichung nach Anti-DIN-Vorzeichenlogik.
Gierrate_korrigiert = Gierrate_Rohwert + Gierratenoffset";
CM_ SG_ 1470 ESP_Laengsbeschleunigung_Offset "Offset der Längsbeschleunigung
Längsbeschleunigung = Rohwert - Offset

nur für MLBevo gilt:
Laengsbeschleunigungsoffset berechnet durch ESP-Modell. 
Laengsbeschleunigung_korrigiert = Laengsbeschleunigung_Rohwert - Laengsbeschleunigungsoffset";
CM_ SG_ 1470 ESP_Lenkwinkel_Offset "Lenkwinkelsoffset berechnet durch ESP-Modell!

nur für MLBevo gilt:
Der Offsetwert entspricht der Abweichung nach Anti-DIN-Vorzeichenlogik.
Lenkwinkel_korrigiert = Lenkwinkel_Rohwert + Lenkwinkeloffset";
CM_ SG_ 1470 ESP_Querbeschleunigung_Offset "Offset der Querbeschleunigung
Querbeschleunigung = Rohwert - Offset

nur für MLBevo gilt:
Querbeschleunigungsoffset berechnet durch ESP-Modell. 
Der Offsetwert entspricht der Abweichung nach Anti-DIN-Vorzeichenlogik.
Querbeschleunigung_korrigiert = ";
CM_ SG_ 1470 ESP_Status_Bremsentemp_Anz "Anzeigesignal für Bremsentemperatur";

CM_ SG_ 795 ABS_Lampe "Sicherheitswarnlampe

Weiterführende Informationen im Lastenheft spezifiziert und in der entsprechenden Fachabteilung zu erfragen.";
CM_ SG_ 795 BK_Lampe_02 "Typ1_ein_statisch signalisiert EBV-Ausfall
MQB: wird auch bei HBV-Ausfall verwendet.

Typ1_ein_statisch: wird bei AUDI für Aktivierung der roten BKL ohne Text und Akustik verwendet (z.B. Lampenaufprüfung).
Typ2_ein_statisch: signalisiert elektrischen ";
CM_ SG_ 795 ESP_24_CRC "Für MLB:
'Berechnung siehe Lastenheft 'Kommunikationsabsicherung für FlexRay und CAN''

Ab MQB und MLBevo:
'Berechnung siehe Lastenheft 'End-to-End Kommunikationsabsicherung''

Endwerte siehe Begleitdokument 'S-PDU Kennungsfolgen'";
CM_ SG_ 795 ESP_BKV_Warnung "ESP sendet im Hinweis- /Störungsfall an das Kombi Informationen zum Anzeigen (Text + Akustik)

Im MQB wird dieses Signal nicht unterstützt!
";
CM_ SG_ 795 ESP_Fehlerstatus_Wegimp "Weiterführende Informationen im Lastenheft spezifiziert und in der entsprechenden Fachabteilung zu erfragen.

MLB: Fehler wird gesetzt, wenn beide ESP-Drehzahlfühler an der Vorderachse defekt sind.

MQB: Fehler wird gesetzt, wenn beide Raddrehzahlfühl";
CM_ SG_ 795 ESP_HDC_Geschw_Farbe "Farbdarstellung der angezeigten HDC-Geschwindigkeit";
CM_ SG_ 795 ESP_HDC_Regelgeschw "Verwendung/Bedienung nur im AU57x Allroad:
HDC-Geschwindigkeit
Dient der Anzeige der HDC-Geschwindigkeit und eines Bergabfahrsymbols im Kombi.
HDC-Standby wird gesetzt sobald der Fahrer den HDC-Taster aktiviert hat.
Bei HDC-Off oder während der Initia";
CM_ SG_ 795 ESP_Lampe "Zustand der Fahrdynamikregelungslampe (MLB: ASR und/oder ESP, MQB: nur ESP)

Weiterführende Informationen im Lastenheft spezifiziert und in der entsprechenden Fachabteilung zu erfragen.";
CM_ SG_ 795 ESP_m_Raddrehz "Radumdrehungen pro Sekunde sind Eingangsgröße für die Geschwindigkeitsberechnung im Kombi. Aus dieser Raddrehzahl und dem Radumfang wird die Fahrzeuggeschwindigkeit errechnet.

MLB: Exklusiver Empfänger ist das Kombiinstrument!
MQB: Bei Frontantrieb un";
CM_ SG_ 795 ESP_Meldungen "ESP sendet im Hinweis- /Störungsfall an das Kombi Informationen zum Anzeigen

Weiterführende Informationen im Lastenheft spezifiziert und in der entsprechenden Fachabteilung zu erfragen.
Ergänzender Hinweis:
1 = Autohold_Hinweis_1 (Anfahrassistent: nu";
CM_ SG_ 795 ESP_Off_Lampe "Bit zur Ansteuerung der separaten ESP-off-Lampe im Kombi (Gesetzesforderung USA)

MLB:
Verwendung/Bedienung ab D4";
CM_ SG_ 795 ESP_QBit_Wegimp_VA "Gesetzt bei Ersatzwert, Init oder Fehler.";
CM_ SG_ 795 ESP_Textanzeigen_03 "Textanzeigen der Fahrdynamikregelung im Kombiinstrument

Weiterführende Informationen im Lastenheft spezifiziert und in der entsprechenden Fachabteilung zu erfragen.

Der Signalwert 24 wird nur im BY736 verwendet.";
CM_ SG_ 795 ESP_Wegimp_Ueberlauf "Der Wegimpulszähler ist pro Zündungslauf mindestens einmal übergelaufen

Weiterführende Informationen im Lastenheft spezifiziert und in der entsprechenden Fachabteilung zu erfragen.";
CM_ SG_ 795 ESP_Wegimp_VA "Weiterführende Informationen im Lastenheft spezifiziert und in der entsprechenden Fachabteilung zu erfragen.

MLB: Die Wegimpulse Vorderachse sind die gemittelten Werte (reine mathematische Operation: Addition und Division durch zwei, keine Filterung) d";
CM_ SG_ 795 TC_Lampe "M-ABS Lampe (separate Lampe für M-ABS-Systeme Markt Brasilien)

Weiterführende Informationen im Lastenheft spezifiziert und in der entsprechenden Fachabteilung zu erfragen.";

CM_ SG_ 508 ESC_Anforderung_Airbrake "ESC fordert die Bremsperformancestellung der aktiven Aerodynamik";
CM_ SG_ 508 ESC_FBA_Meldungen "Hinweis an den Fahrer über das Kombi, bei dauerhafter Bergabfahrt einen Gang einzulegen um die Motorbremse zu nutzen.
Unterscheidung zwischen: 
Handschalterfahrzeugen (FBA_Warnung_aktiv_MT)
Automatikfahrzeugen (FBA_Warnung_aktiv_AT)";
CM_ SG_ 508 ESC_MBK_Meldungen "Das Signal steuert die Schaltempfehlung im Kombi, die bei Bergabfahrt den Fahrer darauf hinweist in eine geeignete Fahrstufe zu schalten um eine Rekuperation zu ermöglichen.";
CM_ SG_ 508 ESC_Motorstartverzoegerung "Mit dem Signal 'Motorstartverzögerung' wird den aktiven Teilnehmern ermöglicht, einen Motorstart durch die Start-Stop-Funktion zu verzögern.";
CM_ SG_ 508 ESP_32_BZ "Botschaft asynchron geroutet. Zählerwert kann springen.";
CM_ SG_ 508 ESP_32_CRC "Für MLB:
'Berechnung siehe Lastenheft 'Kommunikationsabsicherung für FlexRay und CAN''

Ab MQB und MLBevo:
'Berechnung siehe Lastenheft 'End-to-End Kommunikationsabsicherung''

Endwerte siehe Begleitdokument 'S-PDU Kennungsfolgen'";
CM_ SG_ 508 ESP_Aggregataktivitaet "Info über die Aktivität des ESP Aggregats bei aktivem Druckaufbau oder Ventilaktivität";
CM_ SG_ 508 ESP_AVH_LED "Ansteuerung der AVH Funktions-LED durch das BCM.
0 = LED aus
1 = LED ein
2 = LED blinken
3 = Funktion gesperrt, LED aus
4 = frei
5 = frei
6 = Init
7 = frei";
CM_ SG_ 508 ESP_EDS_Anzeige "Grafische Anzeige der EDS-Funktion im Kombiinstrument und MMI für Bentley";
CM_ SG_ 508 ESP_HDC_LED "Ansteuerung der HDC LED in der Schalterleiste durch BCM
0 = LED aus
1 = LED ein
2 = LED blinken
3 = Funktion gesperrt, LED aus
4 = frei
5 = frei
6 = Init
7 = frei";
CM_ SG_ 508 ESP_HDC_Textanzeigen "Textanzeigen der HDC im Kombiinstrument
Zustände 16,17,18 nur für Porsche";
CM_ SG_ 508 ESP_HOLD_verf "Das Signal ESP_HOLD_verf = 1 signalisiert dem Empfänger, dass die Aktivierungsbedingungen für die autonome HOLD-Funktion erfüllt sind (Steigung > parametrierbare Grenzsteigung mit Wunschfahrtrichtung bergauf) und die autonome HOLD-Funktion aktivierbar ist";
CM_ SG_ 508 ESP_Notbremsanzeige "ABS/ASR oder ESP hat Notbremssituation erkannt.
Weiterführende Informationen im Lastenheft spezifiziert und in der entsprechenden Fachabteilung zu erfragen.

";
CM_ SG_ 508 ESP_Off_LED "Ansteuerung der ESP-Off LED in der Schalterleiste durch BCM
0 = LED aus
1 = LED ein
2 = LED blinken
3 = Funktion gesperrt, LED aus
4 = frei
5 = frei
6 = Init
7 = frei";
CM_ SG_ 508 ESP_Offroad_Lampe "Anzeige der ESC-Offroad-Lampe im Kombiinstrument für Bentley";
CM_ SG_ 508 ESP_Rollover_Status_dyn "Information vom ESP an die Dämpferregelung über den dynamischen Rolloverstatus";
CM_ SG_ 508 ESP_Rollover_Status_stat "Information vom ESP an die Dämpferregelung über den statischen Rolloverstatus";
CM_ SG_ 508 ESP_Status_Bremsentemp_02 "Bremsscheibentemperaturmodell. Rückmeldung für Sender einer Verzögerungsanforderung";
CM_ SG_ 508 ESP_Stillstandsflag "Bei RB-Projekten wird das Stillstandsflag gesetzt, wenn der absolute Stillstand der Raddrehzahlsensoren erkannt wurde, d.h. kein Zahn bewegt sich mehr. Dieses Bit wird bspw. im MOST für TV-Tuner-Abschaltung Australien verwendet, d.h. leichte Erschütterung";
CM_ SG_ 508 ESP_Wiederstart_Anz_Std "Dieses Signal gibt die detaillierte Begründung für einen Wiederstart vom Bremsensteuergerät ausgelöst durch die HBC Funktion an.";
CM_ SG_ 508 RLE_Anzeigen "Anzeigen für die Radlöseerkennung";

CM_ SG_ 600 ESP_54_BZ "4bit Botschaftszähler, wird mit jeder Sendebotschaft inkrementiert";
CM_ SG_ 600 ESP_54_CRC "Für MLB:
Berechnung siehe Lastenheft 'Kommunikationsabsicherung für FlexRay und CAN'
Ab MQB und MLBevo:
Berechnung siehe Lastenheft 'End-to-End Kommunikationsabsicherung'

Endwerte siehe Begleitdokument 'S-PDU Kennungsfolgen'";
CM_ SG_ 600 ESP_DriftGong "Drift gong for kombi";
CM_ SG_ 600 ESP_DriftLevel "Drift level current position in ESC";
CM_ SG_ 600 ESP_DriftStatus "Status of drift controller in ESC";
CM_ SG_ 600 ESP_DriftText "Drift text for kombi";
CM_ SG_ 600 ESP_Slider_Gong "Slider gong  for kombi";
CM_ SG_ 600 ESP_Slider_ist_01 "Slider 1 current position in ESC";
CM_ SG_ 600 ESP_Slider_ist_02 "Slider 2 current position in ESC";
CM_ SG_ 600 ESP_Slider_ist_03 "Slider 3 current position in ESC";
CM_ SG_ 600 ESP_Slider_Lamp "Slider lamp  for kombi";
CM_ SG_ 600 ESP_Slider_Status "Status of Slider controller in ESC";
CM_ SG_ 600 ESP_Slider_Text "Slider text message for kombi";

CM_ SG_ 264 EFP_Anf_Bremsenkuehlung "Signal steuert das Oeffnen des Bremsenkuehlkanals und ggf. das Aktivieren eines unterstützenden Lüfters.";
CM_ SG_ 264 FA_Fahrbahnunebenheit "Informationsbeschreibung des Fahrbahnzustandes";
CM_ SG_ 264 FA_Hoehenwert_HL_00 "Aktueller Höhenwert (kalibriert) Hinten Links; ungefiltertes Signal
Einheit, Offset und Faktor sind abhänig von 'FA_Hoehenwert_kalibriert'

Achtung:
Wird im AUDI B8 nicht bedient";
CM_ SG_ 264 FA_Hoehenwert_HR_00 "Aktueller Höhenwert (kalibriert) Hinten Rechts; ungefiltertes Signal
Einheit, Offset und Faktor sind abhänig von 'FA_Hoehenwert_kalibriert'

Achtung:
Wird im AUDI B8 nicht bedient";
CM_ SG_ 264 FA_Hoehenwert_VL_00 "Aktueller Höhenwert (kalibriert) Vorne Links; ungefiltertes Signal
Einheit, Offset und Faktor sind abhänig von 'FA_Hoehenwert_kalibriert'

Achtung:
Wird im AUDI B8 nicht bedient";
CM_ SG_ 264 FA_Hoehenwert_VR_00 "Aktueller Höhenwert (kalibriert) Vorne Rechts; ungefiltertes Signal
Einheit, Offset und Faktor sind abhänig von 'FA_Hoehenwert_kalibriert'

Achtung:
Wird im AUDI B8 nicht bedient";
CM_ SG_ 264 FA_Hoehenwerte_kalibriert "Legt fest, wie die Höhensensorwerte interpretiert werden müssen. Umschaltung kalibrierte Höhenwerte / Rohsignale in Byte 3-6

Achtung:
Im AUDI B8 Konstante: 0x1. D.h. es werden nur Rohwerte bedient!
Im AUDI D4 Konstante: 0x0. D.h. es werden nur Millim";
CM_ SG_ 264 Fahrwerk_01_BZ "Botschaft asynchron geroutet. Zählerwert kann springen.";
CM_ SG_ 264 Fahrwerk_01_CRC "Für MLB:
'Berechnung siehe Lastenheft 'Kommunikationsabsicherung für FlexRay und CAN''

Ab MQB und MLBevo:
'Berechnung siehe Lastenheft 'End-to-End Kommunikationsabsicherung''

Endwerte siehe Begleitdokument 'S-PDU Kennungsfolgen'";

CM_ SG_ 2527679659 FA_Niveau_Druck_HL "Druck gemessen im Federbein HL";
CM_ SG_ 2527679659 FA_Niveau_Druck_HR "Druck gemessen im Federbein HR";
CM_ SG_ 2527679659 FA_Niveau_Druck_VL "Druck gemessen im Federbein VL";
CM_ SG_ 2527679659 FA_Niveau_Druck_VR "Druck gemessen im Federbein VL";

CM_ SG_ 429 EFP_Soll_FahrPr_HAL "Anforderung einer Zwangsumschaltung des Fahrprogramms der HAL durch EFP";
CM_ SG_ 429 FA_Absenkung_Fahrzeug "Nächsttieferes Niveau wird angefahren (Absenken). Dieses Bit wird immer gesetzt in Verbindung mit einer Auswahl aus den Bits FA_Verstellung_xx.";
CM_ SG_ 429 FA_Anhaengerstatus_intern "Anzeige des SG-internen Verarbeitungsstatus Anhängers";
CM_ SG_ 429 FA_Anhebung_Fahrzeug "Nächsthöheres Niveau wird angefahren (Anheben). Dieses Bit wird immer gesetzt in Verbindung mit einer Auswahl aus den Bits FA_Verstellung_xx.";
CM_ SG_ 429 FA_Druckspeicher_verfuegbar "Bit ist gesetzt, wenn eine Regelung aus dem Druckspeicher möglich ist.";
CM_ SG_ 429 FA_ESP_Zuschaltung "Zwangsweise Aktivierung der ESP-Funktionalität wird angefordert auch bei Passivtastung";
CM_ SG_ 429 FA_HAL_Abschaltung "Anforderung einer Zwangs-Deaktivierung der HAL wegen zu geringem
Radfreigang durch Luftfeder oder Schneekettenbetrieb.";
CM_ SG_ 429 FA_Kompressor_laeuft "Zustand der Kompressoransteuerung";
CM_ SG_ 429 FA_Kompressor_laeuft_in_Kuerze "Kompressorlauf steht unmittelbar bevor. Das Bit wird immer gesetzt in Verbindung mit den Bits FA_Anhebung_Fahrzeug oder FA_Absenkung_Fahrzeug.";
CM_ SG_ 429 FA_Signal_Drucksensor "Signalwert des Drucksensors im Magnetventilblock";
CM_ SG_ 429 FA_Systemstatus "Bit wird gesetzt, wenn interne Funktionsprüfung i.O. und System generell funktionsfähig ist.";
CM_ SG_ 429 FA_Verstellung_aktiv "Verstellung ist aktiv. Dieses Bit wird immer gesetzt in Verbindung mit den Bits FA_Anhebung_Fahrzeug oder FA_Absenkung_Fahrzeug.";
CM_ SG_ 429 FA_Verstellung_in_Kuerze "Dieses Bit wird gesetzt, wenn eine Verstellung unmittelbar bevorsteht.";
CM_ SG_ 429 FA_Zwischenniveau "Dieses Bit wird gesetzt, wenn die Fahrzeughöhe zwischen 2 definierten Niveaus liegt, z.B.. während des Regelvorgangs.";
CM_ SG_ 429 Fahrwerk_06_BZ "Botschaft asynchron geroutet. Zählerwert kann springen.";
CM_ SG_ 429 Fahrwerk_06_CRC "Ab MQB und MLBevo:
'Berechnung siehe Lastenheft 'End-to-End Kommunikationsabsicherung''

Endwerte siehe Begleitdokument 'S-PDU Kennungsfolgen'";
CM_ SG_ 429 NR_Anforderung_v_Begrenzung "Anforderung einer v-Begrenzung an das Motor-SG.";
CM_ SG_ 429 NR_Kompressor_Strom_02 "Gemessener Strom am Kompressors.";
CM_ SG_ 429 NR_Kompressor_Temp_Zylinderkopf "Gemessene Temperatur im Zylinderkopf des Luftfeder-Kompressors";
CM_ SG_ 429 NR_LED_BN "Statusrückmeldung der eingestellten Fahrzeughöhe Beladungsniveau bzw. Tasterbetätigung Anheben/Absenken.";
CM_ SG_ 429 NR_LED_HN "Statusrückmeldung der eingestellten Fahrzeughöhe Hochniveau
";
CM_ SG_ 429 NR_LED_SGN "Statusrückmeldung der eingestellten Fahrzeughöhe Sondergeländeniveau bzw. Tasterbetätigung Anheben/Absenken.";
CM_ SG_ 429 NR_LED_TN "Statusrückmeldung der eingestellten Fahrzeughöhe Tiefniveau";
CM_ SG_ 429 NR_Reglerstatus "Anzeige des auszuregelnden Sollniveaus (wird bei Beginn der Regelung auf entsprechenden Wert gesetzt).";

CM_ SG_ 2527679658 EFP_ReifenTemp_HL "Reifentemperatur hinten links";
CM_ SG_ 2527679658 EFP_ReifenTemp_HR "Reifentemperatur hinten rechts";
CM_ SG_ 2527679658 EFP_ReifenTemp_VL "Reifentemperatur vorne links";
CM_ SG_ 2527679658 EFP_ReifenTemp_VR "Reifentemperatur vorne rechts";
CM_ SG_ 2527679658 FA_Beladung_HA "Signal für Beladung (Achslast) aus dem Fahrzustandsbeobachter (FZB) als Vorsteuerinformation für die ABS-Regelung. 
Ausgabe als Delta zum DIN-Leer-Gewicht in 50 kg Schritten.
";
CM_ SG_ 2527679658 FA_Beladung_VA "Signal für Beladung (Achslast) aus dem Fahrzustandsbeobachter (FZB) als Vorsteuer­infor­ma­tion für die ABS-Regelung. 
Ausgabe als Delta zum DIN-Leer-Gewicht in 50 kg Schritten.
";
CM_ SG_ 2527679658 FA_FahrerAnf_Fahrwerk "Fahrwerk Fahrer Anforderung";
CM_ SG_ 2527679658 FA_FahrerAnf_Lift "Fahrer Lift Anforderung";
CM_ SG_ 2527679658 FA_FahrerAnf_Niveau "Niveau Fahrer Anforderung";
BA_DEF_REL_ BU_SG_REL_  "GenSigTimeoutTime" INT 0 65535;
BA_DEF_ BO_  "DiagRequest" ENUM "No", "Yes";
BA_DEF_ BO_  "DiagResponse" ENUM "No", "Yes";
BA_DEF_ BO_  "DiagState" ENUM "No", "Yes";
BA_DEF_ BO_  "GenMsgChkConstant" HEX 0 4095;
BA_DEF_ BO_  "GenMsgCycleTime" INT 0 65535;
BA_DEF_ BO_  "GenMsgCycleTimeFast" INT 0 65535;
BA_DEF_ BO_  "GenMsgDelayTime" INT 0 100000;
BA_DEF_ BO_  "GenMsgILSupport" ENUM "No", "Yes";
BA_DEF_ BO_  "GenMsgNrOfRepetition" INT 0 100;
BA_DEF_ BO_  "GenMsgPDUConstants" STRING;
BA_DEF_ BO_  "GenMsgSendType" ENUM "Cyclic", "not_used", "not_used", "not_used", "not_used", "not_used", "not_used", "IfActive", "NoMsgSendType";
BA_DEF_ BO_  "GenMsgStartDelayTime" INT 0 100000;
BA_DEF_ BO_  "NmMessage" ENUM "No", "Yes";
BA_DEF_ BO_  "NmhMessage" ENUM "No", "Yes";
BA_DEF_ BO_  "MsgType" ENUM "Application", "NM ", "NMH", "TP2.0", "ISO-TP ", "BAP", "EID", "KS", "XCP_PRE_CONFIGURED", "XCP_RUNTIME_CONFIGURED";
BA_DEF_ BO_  "VAGTP20_API" HEX 0 255;
BA_DEF_ BO_  "VAGTP20_DynConnection" ENUM "No", "Yes";
BA_DEF_ BO_  "VAGTP20_DynSetup" ENUM "No", "Yes";
BA_DEF_ BO_  "VAGTP20_StatConnection" ENUM "No", "Yes";
BA_DEF_ SG_  "GenSigActiveRepetitions" INT -2147483648 2147483647;
BA_DEF_ SG_  "GenSigInactiveValue" INT -2147483648 2147483647;
BA_DEF_ SG_  "GenSigSendType" ENUM "Cyclic", "OnWrite", "OnWriteWithRepetition", "OnChange", "OnChangeWithRepetition", "IfActive", "IfActiveWithRepetition", "NoSigSendType", "OnChangeAndIfActive", "OnChangeAndIfActiveWithRepetition";
BA_DEF_ SG_  "GenSigStartValue" INT -2147483648 2147483647;
BA_DEF_ SG_  "NWM-WakeupAllowed" ENUM "No", "Yes";
BA_DEF_ SG_  "GenSigFuncType" ENUM "NoFunction", "MsgCounter", "CRC-8", "XOR", "XOR-2", "DatedBit", "SW-Kl15", "CHK", "Constant", "Protocol", "CRC-8-SAE_J1850", "CRC-32", "DataLength", "DataID", "MsgCounter16", "SOK-Signatur", "Cluster";
BA_DEF_ SG_  "GenSigSwitchedByIgnition" ENUM "No", "Yes";
BA_DEF_ SG_  "Fehlerwert" HEX 0 2147483647;
BA_DEF_ SG_  "GenSigMissingSourceValue" HEX 0 2147483647;
BA_DEF_DEF_REL_  "GenSigTimeoutTime" 0;
BA_DEF_DEF_  "DiagRequest" "No";
BA_DEF_DEF_  "DiagResponse" "No";
BA_DEF_DEF_  "DiagState" "No";
BA_DEF_DEF_  "GenMsgChkConstant" 0;
BA_DEF_DEF_  "GenMsgCycleTime" 0;
BA_DEF_DEF_  "GenMsgCycleTimeFast" 0;
BA_DEF_DEF_  "GenMsgDelayTime" 0;
BA_DEF_DEF_  "GenMsgILSupport" "No";
BA_DEF_DEF_  "GenMsgNrOfRepetition" 0;
BA_DEF_DEF_  "GenMsgPDUConstants" "";
BA_DEF_DEF_  "GenMsgSendType" "NoMsgSendType";
BA_DEF_DEF_  "GenMsgStartDelayTime" 0;
BA_DEF_DEF_  "NmMessage" "No";
BA_DEF_DEF_  "NmhMessage" "No";
BA_DEF_DEF_  "MsgType" "Application";
BA_DEF_DEF_  "VAGTP20_API" 0;
BA_DEF_DEF_  "VAGTP20_DynConnection" "No";
BA_DEF_DEF_  "VAGTP20_DynSetup" "No";
BA_DEF_DEF_  "VAGTP20_StatConnection" "No";
BA_DEF_DEF_  "GenSigActiveRepetitions" 0;
BA_DEF_DEF_  "GenSigInactiveValue" 0;
BA_DEF_DEF_  "GenSigSendType" "NoSigSendType";
BA_DEF_DEF_  "GenSigStartValue" 0;
BA_DEF_DEF_  "NWM-WakeupAllowed" "No";
BA_DEF_DEF_  "GenSigFuncType" "NoFunction";
BA_DEF_DEF_  "GenSigSwitchedByIgnition" "Yes";
BA_DEF_DEF_  "Fehlerwert" 0;
BA_DEF_DEF_  "GenSigMissingSourceValue" 0;
BA_ "GenMsgCycleTime" BO_ 496 50;
BA_ "GenMsgDelayTime" BO_ 496 20;
BA_ "GenMsgILSupport" BO_ 496 1;
BA_ "GenMsgPDUConstants" BO_ 496 "0x2f,0x3c,0x22,0x60,0x18,0xeb,0x63,0x76,0xc5,0x91,0x0f,0x27,0x34,0x04,0x7f,0x02";
BA_ "GenMsgSendType" BO_ 496 0;
BA_ "GenMsgCycleTime" BO_ 2527679980 500;
BA_ "GenMsgDelayTime" BO_ 2527679980 50;
BA_ "GenMsgILSupport" BO_ 2527679980 1;
BA_ "GenMsgSendType" BO_ 2527679980 0;
BA_ "GenMsgStartDelayTime" BO_ 2527679980 50;
BA_ "GenMsgCycleTime" BO_ 996 1000;
BA_ "GenMsgDelayTime" BO_ 996 50;
BA_ "GenMsgILSupport" BO_ 996 1;
BA_ "GenMsgSendType" BO_ 996 0;
BA_ "GenMsgStartDelayTime" BO_ 996 60;
BA_ "GenMsgCycleTime" BO_ 1603 1000;
BA_ "GenMsgDelayTime" BO_ 1603 100;
BA_ "GenMsgILSupport" BO_ 1603 1;
BA_ "GenMsgSendType" BO_ 1603 0;
BA_ "GenMsgCycleTime" BO_ 1622 1000;
BA_ "GenMsgCycleTimeFast" BO_ 1622 50;
BA_ "GenMsgDelayTime" BO_ 1622 50;
BA_ "GenMsgILSupport" BO_ 1622 1;
BA_ "GenMsgPDUConstants" BO_ 1622 "0xab,0x2f,0xd3,0x39,0x6f,0x37,0xfa,0x59,0xa4,0x70,0xce,0x11,0x54,0x82,0x62,0x56";
BA_ "GenMsgSendType" BO_ 1622 0;
BA_ "GenMsgChkConstant" BO_ 260 5;
BA_ "GenMsgCycleTime" BO_ 260 500;
BA_ "GenMsgDelayTime" BO_ 260 40;
BA_ "GenMsgILSupport" BO_ 260 1;
BA_ "GenMsgPDUConstants" BO_ 260 "0x05,0x05,0x05,0x05,0x05,0x05,0x05,0x05,0x05,0x05,0x05,0x05,0x05,0x05,0x05,0x05";
BA_ "GenMsgSendType" BO_ 260 0;
BA_ "GenMsgStartDelayTime" BO_ 260 65;
BA_ "GenMsgCycleTime" BO_ 781 200;
BA_ "GenMsgDelayTime" BO_ 781 20;
BA_ "GenMsgILSupport" BO_ 781 1;
BA_ "GenMsgSendType" BO_ 781 0;
BA_ "GenMsgStartDelayTime" BO_ 781 30;
BA_ "GenMsgChkConstant" BO_ 259 2;
BA_ "GenMsgCycleTime" BO_ 259 100;
BA_ "GenMsgILSupport" BO_ 259 1;
BA_ "GenMsgPDUConstants" BO_ 259 "0x02,0x02,0x02,0x02,0x02,0x02,0x02,0x02,0x02,0x02,0x02,0x02,0x02,0x02,0x02,0x02";
BA_ "GenMsgSendType" BO_ 259 0;
BA_ "GenMsgChkConstant" BO_ 262 7;
BA_ "GenMsgCycleTime" BO_ 262 200;
BA_ "GenMsgDelayTime" BO_ 262 20;
BA_ "GenMsgILSupport" BO_ 262 1;
BA_ "GenMsgPDUConstants" BO_ 262 "0x07,0x07,0x07,0x07,0x07,0x07,0x07,0x07,0x07,0x07,0x07,0x07,0x07,0x07,0x07,0x07";
BA_ "GenMsgSendType" BO_ 262 0;
BA_ "GenMsgStartDelayTime" BO_ 262 40;
BA_ "GenMsgChkConstant" BO_ 914 145;
BA_ "GenMsgCycleTime" BO_ 914 1000;
BA_ "GenMsgDelayTime" BO_ 914 80;
BA_ "GenMsgILSupport" BO_ 914 1;
BA_ "GenMsgPDUConstants" BO_ 914 "0x91,0x91,0x91,0x91,0x91,0x91,0x91,0x91,0x91,0x91,0x91,0x91,0x91,0x91,0x91,0x91";
BA_ "GenMsgSendType" BO_ 914 0;
BA_ "GenMsgChkConstant" BO_ 278 172;
BA_ "GenMsgCycleTime" BO_ 278 50;
BA_ "GenMsgILSupport" BO_ 278 1;
BA_ "GenMsgPDUConstants" BO_ 278 "0xac,0xac,0xac,0xac,0xac,0xac,0xac,0xac,0xac,0xac,0xac,0xac,0xac,0xac,0xac,0xac";
BA_ "GenMsgSendType" BO_ 278 0;
BA_ "GenMsgCycleTime" BO_ 418 1000;
BA_ "GenMsgDelayTime" BO_ 418 20;
BA_ "GenMsgILSupport" BO_ 418 1;
BA_ "GenMsgPDUConstants" BO_ 418 "0xcb,0x47,0xd7,0xd2,0x56,0x3e,0x20,0xea,0x6e,0x6d,0x8c,0x1b,0xdf,0x49,0xaa,0xab";
BA_ "GenMsgSendType" BO_ 418 0;
BA_ "GenMsgCycleTime" BO_ 1629 160;
BA_ "GenMsgILSupport" BO_ 1629 1;
BA_ "GenMsgPDUConstants" BO_ 1629 "0xac,0xb3,0xab,0xeb,0x7a,0xe1,0x3b,0xf7,0x73,0xba,0x7c,0x9e,0x06,0x5f,0x02,0xd9";
BA_ "GenMsgSendType" BO_ 1629 0;
BA_ "GenMsgCycleTime" BO_ 253 100;
BA_ "GenMsgILSupport" BO_ 253 1;
BA_ "GenMsgPDUConstants" BO_ 253 "0xb4,0xef,0xf8,0x49,0x1e,0xe5,0xc2,0xc0,0x97,0x19,0x3c,0xc9,0xf1,0x98,0xd6,0x61";
BA_ "GenMsgSendType" BO_ 253 0;
BA_ "GenMsgChkConstant" BO_ 239 6;
BA_ "GenMsgCycleTime" BO_ 239 100;
BA_ "GenMsgILSupport" BO_ 239 1;
BA_ "GenMsgPDUConstants" BO_ 239 "0x06,0x06,0x06,0x06,0x06,0x06,0x06,0x06,0x06,0x06,0x06,0x06,0x06,0x06,0x06,0x06";
BA_ "GenMsgSendType" BO_ 239 0;
BA_ "GenMsgCycleTime" BO_ 1470 320;
BA_ "GenMsgILSupport" BO_ 1470 1;
BA_ "GenMsgPDUConstants" BO_ 1470 "0xc9,0x21,0x6f,0x63,0xd2,0x42,0x6a,0x77,0x4a,0x3d,0xb0,0x62,0x9f,0x38,0xcd,0x5c";
BA_ "GenMsgSendType" BO_ 1470 0;
BA_ "GenMsgCycleTime" BO_ 795 40;
BA_ "GenMsgILSupport" BO_ 795 1;
BA_ "GenMsgPDUConstants" BO_ 795 "0x67,0x8a,0xae,0x22,0x4d,0xd0,0x51,0x80,0x5c,0xb9,0xce,0x1e,0xdf,0x02,0x2d,0xd4";
BA_ "GenMsgSendType" BO_ 795 0;
BA_ "GenMsgCycleTime" BO_ 508 200;
BA_ "GenMsgDelayTime" BO_ 508 20;
BA_ "GenMsgILSupport" BO_ 508 1;
BA_ "GenMsgPDUConstants" BO_ 508 "0x01,0x10,0x05,0xde,0xe0,0xdc,0x34,0xc4,0x8a,0xb1,0x6d,0x7b,0x62,0xef,0x1f,0x95";
BA_ "GenMsgSendType" BO_ 508 0;
BA_ "GenMsgStartDelayTime" BO_ 508 40;
BA_ "GenMsgCycleTime" BO_ 600 400;
BA_ "GenMsgDelayTime" BO_ 600 40;
BA_ "GenMsgILSupport" BO_ 600 1;
BA_ "GenMsgPDUConstants" BO_ 600 "0xe0,0x57,0x49,0xc3,0x18,0xac,0xa6,0x0b,0x5c,0xc1,0x84,0x7b,0x04,0x98,0x73,0x20";
BA_ "GenMsgSendType" BO_ 600 0;
BA_ "GenMsgChkConstant" BO_ 264 9;
BA_ "GenMsgCycleTime" BO_ 264 200;
BA_ "GenMsgILSupport" BO_ 264 1;
BA_ "GenMsgPDUConstants" BO_ 264 "0x09,0x09,0x09,0x09,0x09,0x09,0x09,0x09,0x09,0x09,0x09,0x09,0x09,0x09,0x09,0x09";
BA_ "GenMsgSendType" BO_ 264 0;
BA_ "GenMsgCycleTime" BO_ 2527679659 320;
BA_ "GenMsgILSupport" BO_ 2527679659 1;
BA_ "GenMsgPDUConstants" BO_ 2527679659 "0x17,0xbe,0xf4,0xdd,0xd2,0x70,0x3d,0x04,0xcd,0x8a,0x28,0x06,0x4c,0x09,0x14,0x5b";
BA_ "GenMsgSendType" BO_ 2527679659 0;
BA_ "GenMsgCycleTime" BO_ 429 1000;
BA_ "GenMsgDelayTime" BO_ 429 40;
BA_ "GenMsgILSupport" BO_ 429 1;
BA_ "GenMsgPDUConstants" BO_ 429 "0x40,0x7a,0x23,0x13,0x03,0xf4,0xf8,0xe5,0x97,0xc9,0xd6,0x07,0x47,0x21,0x66,0xdd";
BA_ "GenMsgSendType" BO_ 429 0;
BA_ "GenMsgStartDelayTime" BO_ 429 65;
BA_ "GenMsgCycleTime" BO_ 2527679658 320;
BA_ "GenMsgILSupport" BO_ 2527679658 1;
BA_ "GenMsgSendType" BO_ 2527679658 0;
BA_ "GenSigSendType" SG_ 496 ACF_Lampe_Hands_Off 3;
BA_ "GenSigSwitchedByIgnition" SG_ 496 ACF_Lampe_Hands_Off 0;
BA_ "GenSigSendType" SG_ 496 EA_02_BZ 0;
BA_ "GenSigFuncType" SG_ 496 EA_02_BZ 1;
BA_ "GenSigSendType" SG_ 496 EA_02_CRC 0;
BA_ "GenSigFuncType" SG_ 496 EA_02_CRC 2;
BA_ "GenSigSendType" SG_ 496 EA_Blinken 3;
BA_ "GenSigSendType" SG_ 496 EA_Bremslichtblinken 3;
BA_ "GenSigSendType" SG_ 496 EA_Infotainment_Anf 3;
BA_ "GenSigSendType" SG_ 496 EA_Innenraumlicht_Anf 3;
BA_ "GenSigSendType" SG_ 496 EA_Texte 3;
BA_ "GenSigSendType" SG_ 496 EA_Tueren_Anf 3;
BA_ "GenSigSendType" SG_ 496 STP_Primaeranz 3;
BA_ "GenSigSendType" SG_ 496 zFAS_Warnblinken 3;
BA_ "GenSigSendType" SG_ 2527679980 bCall_active 3;
BA_ "GenSigSwitchedByIgnition" SG_ 2527679980 bCall_active 0;
BA_ "GenSigSendType" SG_ 2527679980 eCall_Funktionsstatus 3;
BA_ "GenSigSwitchedByIgnition" SG_ 2527679980 eCall_Funktionsstatus 0;
BA_ "GenSigSendType" SG_ 2527679980 eCall_Funktionsstatus_02 3;
BA_ "GenSigStartValue" SG_ 2527679980 eCall_Funktionsstatus_02 7;
BA_ "GenSigSwitchedByIgnition" SG_ 2527679980 eCall_Funktionsstatus_02 0;
BA_ "GenSigSendType" SG_ 2527679980 eCall_Mute_Anf 3;
BA_ "GenSigSwitchedByIgnition" SG_ 2527679980 eCall_Mute_Anf 0;
BA_ "GenSigSendType" SG_ 2527679980 eCall_Statuslicht_Farbe1 3;
BA_ "GenSigSwitchedByIgnition" SG_ 2527679980 eCall_Statuslicht_Farbe1 0;
BA_ "GenSigSendType" SG_ 2527679980 eCall_Statuslicht_Farbe2 3;
BA_ "GenSigSwitchedByIgnition" SG_ 2527679980 eCall_Statuslicht_Farbe2 0;
BA_ "GenSigSendType" SG_ 2527679980 eCall_Subscription 3;
BA_ "GenSigSwitchedByIgnition" SG_ 2527679980 eCall_Subscription 0;
BA_ "GenSigSendType" SG_ 996 EFF_Einsparhinweis 3;
BA_ "GenSigSwitchedByIgnition" SG_ 996 EFF_Einsparhinweis 0;
BA_ "GenSigSendType" SG_ 996 EFF_Verbrauch_STH 3;
BA_ "GenSigSwitchedByIgnition" SG_ 996 EFF_Verbrauch_STH 0;
BA_ "Fehlerwert" SG_ 996 EFF_Verbrauch_STH 127;
BA_ "GenSigSendType" SG_ 996 EFF_Verbraucher_Balken 3;
BA_ "GenSigStartValue" SG_ 996 EFF_Verbraucher_Balken 510;
BA_ "GenSigSwitchedByIgnition" SG_ 996 EFF_Verbraucher_Balken 0;
BA_ "Fehlerwert" SG_ 996 EFF_Verbraucher_Balken 511;
BA_ "GenSigSendType" SG_ 996 EFF_Verbraucher_Pos_1 3;
BA_ "GenSigSwitchedByIgnition" SG_ 996 EFF_Verbraucher_Pos_1 0;
BA_ "GenSigSendType" SG_ 996 EFF_Verbraucher_Pos_2 3;
BA_ "GenSigSwitchedByIgnition" SG_ 996 EFF_Verbraucher_Pos_2 0;
BA_ "GenSigSendType" SG_ 996 EFF_Verbraucher_Pos_3 3;
BA_ "GenSigSwitchedByIgnition" SG_ 996 EFF_Verbraucher_Pos_3 0;
BA_ "GenSigSendType" SG_ 996 MKE_FAS 3;
BA_ "GenSigSwitchedByIgnition" SG_ 996 MKE_FAS 0;
BA_ "GenSigSendType" SG_ 996 MKE_FAS_Fkt_Status 0;
BA_ "GenSigSwitchedByIgnition" SG_ 996 MKE_FAS_Fkt_Status 0;
BA_ "Fehlerwert" SG_ 996 MKE_FAS_Fkt_Status 3;
BA_ "GenSigSendType" SG_ 996 MKE_Fehlercode 3;
BA_ "GenSigSwitchedByIgnition" SG_ 996 MKE_Fehlercode 0;
BA_ "GenSigSendType" SG_ 996 MKE_Stufe 0;
BA_ "GenSigSwitchedByIgnition" SG_ 996 MKE_Stufe 0;
BA_ "GenSigSendType" SG_ 996 MKE_Texte 0;
BA_ "GenSigSwitchedByIgnition" SG_ 996 MKE_Texte 0;
BA_ "GenSigSendType" SG_ 1603 KBI_Einheit_Datum 3;
BA_ "GenSigSwitchedByIgnition" SG_ 1603 KBI_Einheit_Datum 0;
BA_ "GenSigSendType" SG_ 1603 KBI_Einheit_Druck 3;
BA_ "GenSigSwitchedByIgnition" SG_ 1603 KBI_Einheit_Druck 0;
BA_ "GenSigSendType" SG_ 1603 KBI_Einheit_Masse 3;
BA_ "GenSigSwitchedByIgnition" SG_ 1603 KBI_Einheit_Masse 0;
BA_ "GenSigSendType" SG_ 1603 KBI_Einheit_Sprache 3;
BA_ "GenSigSwitchedByIgnition" SG_ 1603 KBI_Einheit_Sprache 0;
BA_ "GenSigSendType" SG_ 1603 KBI_Einheit_Streckenanz 3;
BA_ "GenSigSwitchedByIgnition" SG_ 1603 KBI_Einheit_Streckenanz 0;
BA_ "GenSigSendType" SG_ 1603 KBI_Einheit_Temp 3;
BA_ "GenSigSwitchedByIgnition" SG_ 1603 KBI_Einheit_Temp 0;
BA_ "GenSigSendType" SG_ 1603 KBI_Einheit_Uhrzeit 3;
BA_ "GenSigSwitchedByIgnition" SG_ 1603 KBI_Einheit_Uhrzeit 0;
BA_ "GenSigSendType" SG_ 1603 KBI_Einheit_Verbrauch 3;
BA_ "GenSigSwitchedByIgnition" SG_ 1603 KBI_Einheit_Verbrauch 0;
BA_ "GenSigSendType" SG_ 1603 KBI_Einheit_Verbrauch_elektr 3;
BA_ "GenSigSwitchedByIgnition" SG_ 1603 KBI_Einheit_Verbrauch_elektr 0;
BA_ "GenSigSendType" SG_ 1603 KBI_Einheit_Verbrauch_Gas 3;
BA_ "GenSigSwitchedByIgnition" SG_ 1603 KBI_Einheit_Verbrauch_Gas 0;
BA_ "GenSigSendType" SG_ 1603 KBI_Einheit_Volumen 3;
BA_ "GenSigSwitchedByIgnition" SG_ 1603 KBI_Einheit_Volumen 0;
BA_ "GenSigSendType" SG_ 1603 KBI_MFA_v_Einheit_02 3;
BA_ "GenSigSwitchedByIgnition" SG_ 1603 KBI_MFA_v_Einheit_02 0;
BA_ "GenSigSendType" SG_ 1622 ELV_01_BZ 0;
BA_ "GenSigFuncType" SG_ 1622 ELV_01_BZ 1;
BA_ "GenSigSwitchedByIgnition" SG_ 1622 ELV_01_BZ 0;
BA_ "GenSigSendType" SG_ 1622 ELV_01_CRC 0;
BA_ "GenSigFuncType" SG_ 1622 ELV_01_CRC 2;
BA_ "GenSigSwitchedByIgnition" SG_ 1622 ELV_01_CRC 0;
BA_ "GenSigSendType" SG_ 1622 ELV_01_Sendestatus 5;
BA_ "GenSigSwitchedByIgnition" SG_ 1622 ELV_01_Sendestatus 0;
BA_ "GenSigSendType" SG_ 1622 ELV_Abbruch_Anf_Klemmenfreigabe 3;
BA_ "GenSigSwitchedByIgnition" SG_ 1622 ELV_Abbruch_Anf_Klemmenfreigabe 0;
BA_ "GenSigSendType" SG_ 1622 ELV_Anf_Klemme_15 3;
BA_ "GenSigSwitchedByIgnition" SG_ 1622 ELV_Anf_Klemme_15 0;
BA_ "GenSigSendType" SG_ 1622 ELV_Anf_Klemme_50 3;
BA_ "GenSigSwitchedByIgnition" SG_ 1622 ELV_Anf_Klemme_50 0;
BA_ "GenSigSendType" SG_ 1622 ELV_Anf_Klemme_S 3;
BA_ "GenSigSwitchedByIgnition" SG_ 1622 ELV_Anf_Klemme_S 0;
BA_ "GenSigSendType" SG_ 1622 ELV_Anlernmodus 3;
BA_ "GenSigSwitchedByIgnition" SG_ 1622 ELV_Anlernmodus 0;
BA_ "GenSigSendType" SG_ 1622 ELV_Entriegelt 3;
BA_ "GenSigSwitchedByIgnition" SG_ 1622 ELV_Entriegelt 0;
BA_ "GenSigSendType" SG_ 1622 ELV_Klemmenfreigabe 3;
BA_ "GenSigSwitchedByIgnition" SG_ 1622 ELV_Klemmenfreigabe 0;
BA_ "GenSigSendType" SG_ 1622 ELV_Lebenszustand 3;
BA_ "GenSigSwitchedByIgnition" SG_ 1622 ELV_Lebenszustand 0;
BA_ "GenSigSendType" SG_ 1622 ELV_LED_Gelb 3;
BA_ "GenSigSwitchedByIgnition" SG_ 1622 ELV_LED_Gelb 0;
BA_ "GenSigSendType" SG_ 1622 ELV_LED_Rot 3;
BA_ "GenSigSwitchedByIgnition" SG_ 1622 ELV_LED_Rot 0;
BA_ "GenSigSendType" SG_ 1622 ELV_P_verriegelt 3;
BA_ "GenSigSwitchedByIgnition" SG_ 1622 ELV_P_verriegelt 0;
BA_ "GenSigSendType" SG_ 1622 ELV_Txt_Bremse 3;
BA_ "GenSigSwitchedByIgnition" SG_ 1622 ELV_Txt_Bremse 0;
BA_ "GenSigSendType" SG_ 1622 ELV_Txt_Defekt 3;
BA_ "GenSigSwitchedByIgnition" SG_ 1622 ELV_Txt_Defekt 0;
BA_ "GenSigSendType" SG_ 1622 ELV_Txt_Kupplung 3;
BA_ "GenSigSwitchedByIgnition" SG_ 1622 ELV_Txt_Kupplung 0;
BA_ "GenSigSendType" SG_ 1622 ELV_Txt_Lkg_Bewegen 3;
BA_ "GenSigSwitchedByIgnition" SG_ 1622 ELV_Txt_Lkg_Bewegen 0;
BA_ "GenSigSendType" SG_ 1622 ELV_Txt_P_Gang 3;
BA_ "GenSigSwitchedByIgnition" SG_ 1622 ELV_Txt_P_Gang 0;
BA_ "GenSigSendType" SG_ 1622 ELV_Txt_Panikabschaltung 3;
BA_ "GenSigSwitchedByIgnition" SG_ 1622 ELV_Txt_Panikabschaltung 0;
BA_ "GenSigSendType" SG_ 1622 ELV_Txt_PN_Gang 3;
BA_ "GenSigSwitchedByIgnition" SG_ 1622 ELV_Txt_PN_Gang 0;
BA_ "GenSigSendType" SG_ 1622 ELV_Txt_Werkstatt 3;
BA_ "GenSigSwitchedByIgnition" SG_ 1622 ELV_Txt_Werkstatt 0;
BA_ "GenSigSendType" SG_ 1622 ELV_Verriegelt 3;
BA_ "GenSigSwitchedByIgnition" SG_ 1622 ELV_Verriegelt 0;
BA_ "GenSigSendType" SG_ 1622 ELV_ZAT_betaetigt 3;
BA_ "GenSigSwitchedByIgnition" SG_ 1622 ELV_ZAT_betaetigt 0;
BA_ "GenSigSendType" SG_ 260 EPB_01_BZ 0;
BA_ "GenSigFuncType" SG_ 260 EPB_01_BZ 1;
BA_ "GenSigSwitchedByIgnition" SG_ 260 EPB_01_BZ 0;
BA_ "GenSigSendType" SG_ 260 EPB_01_CRC 0;
BA_ "GenSigFuncType" SG_ 260 EPB_01_CRC 2;
BA_ "GenSigSwitchedByIgnition" SG_ 260 EPB_01_CRC 0;
BA_ "GenSigSendType" SG_ 260 EPB_DAA_Randbed_erf 0;
BA_ "GenSigSwitchedByIgnition" SG_ 260 EPB_DAA_Randbed_erf 0;
BA_ "GenSigSendType" SG_ 260 EPB_Fehlerstatus_02 3;
BA_ "GenSigSwitchedByIgnition" SG_ 260 EPB_Fehlerstatus_02 0;
BA_ "GenSigSendType" SG_ 260 EPB_Freig_Verzoeg_Anf 0;
BA_ "GenSigSwitchedByIgnition" SG_ 260 EPB_Freig_Verzoeg_Anf 0;
BA_ "GenSigSendType" SG_ 260 EPB_Pedalweg_Kuppl 3;
BA_ "GenSigSwitchedByIgnition" SG_ 260 EPB_Pedalweg_Kuppl 0;
BA_ "Fehlerwert" SG_ 260 EPB_Pedalweg_Kuppl 255;
BA_ "GenSigSendType" SG_ 260 EPB_QBit_Pedalweg_Kuppl 3;
BA_ "GenSigStartValue" SG_ 260 EPB_QBit_Pedalweg_Kuppl 1;
BA_ "GenSigSwitchedByIgnition" SG_ 260 EPB_QBit_Pedalweg_Kuppl 0;
BA_ "GenSigSendType" SG_ 260 EPB_QBit_Schalterpos 0;
BA_ "GenSigStartValue" SG_ 260 EPB_QBit_Schalterpos 1;
BA_ "GenSigSwitchedByIgnition" SG_ 260 EPB_QBit_Schalterpos 0;
BA_ "GenSigSendType" SG_ 260 EPB_Schalterposition 0;
BA_ "GenSigSwitchedByIgnition" SG_ 260 EPB_Schalterposition 0;
BA_ "Fehlerwert" SG_ 260 EPB_Schalterposition 3;
BA_ "GenSigSendType" SG_ 260 EPB_Spannkraft 0;
BA_ "GenSigStartValue" SG_ 260 EPB_Spannkraft 30;
BA_ "GenSigSwitchedByIgnition" SG_ 260 EPB_Spannkraft 0;
BA_ "Fehlerwert" SG_ 260 EPB_Spannkraft 31;
BA_ "GenSigSendType" SG_ 260 EPB_Status_02 3;
BA_ "GenSigStartValue" SG_ 260 EPB_Status_02 6;
BA_ "GenSigSwitchedByIgnition" SG_ 260 EPB_Status_02 0;
BA_ "GenSigSendType" SG_ 260 EPB_Verzoeg_Anf 0;
BA_ "GenSigStartValue" SG_ 260 EPB_Verzoeg_Anf 166;
BA_ "GenSigSwitchedByIgnition" SG_ 260 EPB_Verzoeg_Anf 0;
BA_ "GenSigSendType" SG_ 781 EPB_Akustik 0;
BA_ "GenSigSwitchedByIgnition" SG_ 781 EPB_Akustik 0;
BA_ "GenSigSendType" SG_ 781 EPB_Autoholdlampe 3;
BA_ "GenSigSwitchedByIgnition" SG_ 781 EPB_Autoholdlampe 0;
BA_ "GenSigSendType" SG_ 781 EPB_Bremsbelag_Warn 0;
BA_ "GenSigSwitchedByIgnition" SG_ 781 EPB_Bremsbelag_Warn 0;
BA_ "GenSigSendType" SG_ 781 EPB_Fehlerlampe_BKL 0;
BA_ "GenSigSwitchedByIgnition" SG_ 781 EPB_Fehlerlampe_BKL 0;
BA_ "GenSigSendType" SG_ 781 EPB_Fehlerlampe_Gelb 0;
BA_ "GenSigSwitchedByIgnition" SG_ 781 EPB_Fehlerlampe_Gelb 0;
BA_ "GenSigSendType" SG_ 781 EPB_Fehlermeldungen 3;
BA_ "GenSigSwitchedByIgnition" SG_ 781 EPB_Fehlermeldungen 0;
BA_ "GenSigSendType" SG_ 781 EPB_Funktionslampe 3;
BA_ "GenSigSwitchedByIgnition" SG_ 781 EPB_Funktionslampe 0;
BA_ "GenSigSendType" SG_ 781 EPB_Texte 3;
BA_ "GenSigSwitchedByIgnition" SG_ 781 EPB_Texte 0;
BA_ "GenSigSendType" SG_ 259 ESP_03_BZ 0;
BA_ "GenSigFuncType" SG_ 259 ESP_03_BZ 1;
BA_ "GenSigSwitchedByIgnition" SG_ 259 ESP_03_BZ 0;
BA_ "GenSigSendType" SG_ 259 ESP_03_CRC 0;
BA_ "GenSigFuncType" SG_ 259 ESP_03_CRC 2;
BA_ "GenSigSwitchedByIgnition" SG_ 259 ESP_03_CRC 0;
BA_ "GenSigSendType" SG_ 259 ESP_HL_FR 0;
BA_ "GenSigSwitchedByIgnition" SG_ 259 ESP_HL_FR 0;
BA_ "GenSigSendType" SG_ 259 ESP_HL_Radgeschw 0;
BA_ "GenSigStartValue" SG_ 259 ESP_HL_Radgeschw 4094;
BA_ "GenSigSwitchedByIgnition" SG_ 259 ESP_HL_Radgeschw 0;
BA_ "Fehlerwert" SG_ 259 ESP_HL_Radgeschw 4095;
BA_ "GenSigSendType" SG_ 259 ESP_HR_FR 0;
BA_ "GenSigSwitchedByIgnition" SG_ 259 ESP_HR_FR 0;
BA_ "GenSigSendType" SG_ 259 ESP_HR_Radgeschw 0;
BA_ "GenSigStartValue" SG_ 259 ESP_HR_Radgeschw 4094;
BA_ "GenSigSwitchedByIgnition" SG_ 259 ESP_HR_Radgeschw 0;
BA_ "Fehlerwert" SG_ 259 ESP_HR_Radgeschw 4095;
BA_ "GenSigSendType" SG_ 259 ESP_VL_FR 0;
BA_ "GenSigSwitchedByIgnition" SG_ 259 ESP_VL_FR 0;
BA_ "GenSigSendType" SG_ 259 ESP_VL_Radgeschw 0;
BA_ "GenSigStartValue" SG_ 259 ESP_VL_Radgeschw 4094;
BA_ "GenSigSwitchedByIgnition" SG_ 259 ESP_VL_Radgeschw 0;
BA_ "Fehlerwert" SG_ 259 ESP_VL_Radgeschw 4095;
BA_ "GenSigSendType" SG_ 259 ESP_VR_FR 0;
BA_ "GenSigSwitchedByIgnition" SG_ 259 ESP_VR_FR 0;
BA_ "GenSigSendType" SG_ 259 ESP_VR_Radgeschw 0;
BA_ "GenSigStartValue" SG_ 259 ESP_VR_Radgeschw 4094;
BA_ "GenSigSwitchedByIgnition" SG_ 259 ESP_VR_Radgeschw 0;
BA_ "Fehlerwert" SG_ 259 ESP_VR_Radgeschw 4095;
BA_ "GenSigSendType" SG_ 262 ECD_Fehler 0;
BA_ "GenSigSwitchedByIgnition" SG_ 262 ECD_Fehler 0;
BA_ "GenSigSendType" SG_ 262 ECD_nicht_verfuegbar 0;
BA_ "GenSigStartValue" SG_ 262 ECD_nicht_verfuegbar 1;
BA_ "GenSigSwitchedByIgnition" SG_ 262 ECD_nicht_verfuegbar 0;
BA_ "GenSigSendType" SG_ 262 ESC_Bremslicht 0;
BA_ "GenSigSwitchedByIgnition" SG_ 262 ESC_Bremslicht 0;
BA_ "GenSigSendType" SG_ 262 ESP_05_BZ 0;
BA_ "GenSigFuncType" SG_ 262 ESP_05_BZ 1;
BA_ "GenSigSwitchedByIgnition" SG_ 262 ESP_05_BZ 0;
BA_ "GenSigSendType" SG_ 262 ESP_05_CRC 0;
BA_ "GenSigFuncType" SG_ 262 ESP_05_CRC 2;
BA_ "GenSigSwitchedByIgnition" SG_ 262 ESP_05_CRC 0;
BA_ "GenSigSendType" SG_ 262 ESP_Anforderung_EPB 0;
BA_ "GenSigSwitchedByIgnition" SG_ 262 ESP_Anforderung_EPB 0;
BA_ "GenSigSendType" SG_ 262 ESP_Autohold_aktiv 0;
BA_ "GenSigSwitchedByIgnition" SG_ 262 ESP_Autohold_aktiv 0;
BA_ "GenSigSendType" SG_ 262 ESP_Autohold_Standby 0;
BA_ "GenSigSwitchedByIgnition" SG_ 262 ESP_Autohold_Standby 0;
BA_ "GenSigSendType" SG_ 262 ESP_BKV_Unterdruck 0;
BA_ "GenSigStartValue" SG_ 262 ESP_BKV_Unterdruck 254;
BA_ "GenSigSwitchedByIgnition" SG_ 262 ESP_BKV_Unterdruck 0;
BA_ "Fehlerwert" SG_ 262 ESP_BKV_Unterdruck 255;
BA_ "GenSigSendType" SG_ 262 ESP_Bremsdruck 0;
BA_ "GenSigStartValue" SG_ 262 ESP_Bremsdruck 100;
BA_ "GenSigSwitchedByIgnition" SG_ 262 ESP_Bremsdruck 0;
BA_ "Fehlerwert" SG_ 262 ESP_Bremsdruck 1023;
BA_ "GenSigSendType" SG_ 262 ESP_Eingr_HL 0;
BA_ "GenSigSwitchedByIgnition" SG_ 262 ESP_Eingr_HL 0;
BA_ "GenSigSendType" SG_ 262 ESP_Eingr_HR 0;
BA_ "GenSigSwitchedByIgnition" SG_ 262 ESP_Eingr_HR 0;
BA_ "GenSigSendType" SG_ 262 ESP_Eingr_VL 0;
BA_ "GenSigSwitchedByIgnition" SG_ 262 ESP_Eingr_VL 0;
BA_ "GenSigSendType" SG_ 262 ESP_Eingr_VR 0;
BA_ "GenSigSwitchedByIgnition" SG_ 262 ESP_Eingr_VR 0;
BA_ "GenSigSendType" SG_ 262 ESP_Fahrer_bremst 0;
BA_ "GenSigSwitchedByIgnition" SG_ 262 ESP_Fahrer_bremst 0;
BA_ "GenSigSendType" SG_ 262 ESP_FStatus_Anfahrhilfe 0;
BA_ "GenSigSwitchedByIgnition" SG_ 262 ESP_FStatus_Anfahrhilfe 0;
BA_ "Fehlerwert" SG_ 262 ESP_FStatus_Anfahrhilfe 1;
BA_ "GenSigSendType" SG_ 262 ESP_HBA_aktiv 0;
BA_ "GenSigSwitchedByIgnition" SG_ 262 ESP_HBA_aktiv 0;
BA_ "GenSigSendType" SG_ 262 ESP_HDC_aktiv 0;
BA_ "GenSigSwitchedByIgnition" SG_ 262 ESP_HDC_aktiv 0;
BA_ "GenSigSendType" SG_ 262 ESP_HDC_Standby 3;
BA_ "GenSigSwitchedByIgnition" SG_ 262 ESP_HDC_Standby 0;
BA_ "GenSigSendType" SG_ 262 ESP_Lenkeingriff_ADS 0;
BA_ "GenSigSwitchedByIgnition" SG_ 262 ESP_Lenkeingriff_ADS 0;
BA_ "GenSigSendType" SG_ 262 ESP_Prefill_ausgeloest 0;
BA_ "GenSigSwitchedByIgnition" SG_ 262 ESP_Prefill_ausgeloest 0;
BA_ "GenSigSendType" SG_ 262 ESP_QBit_Bremsdruck 0;
BA_ "GenSigStartValue" SG_ 262 ESP_QBit_Bremsdruck 1;
BA_ "GenSigSwitchedByIgnition" SG_ 262 ESP_QBit_Bremsdruck 0;
BA_ "GenSigSendType" SG_ 262 ESP_QBit_Fahrer_bremst 0;
BA_ "GenSigStartValue" SG_ 262 ESP_QBit_Fahrer_bremst 1;
BA_ "GenSigSwitchedByIgnition" SG_ 262 ESP_QBit_Fahrer_bremst 0;
BA_ "GenSigSendType" SG_ 262 ESP_Rueckwaertsfahrt_erkannt 0;
BA_ "GenSigSwitchedByIgnition" SG_ 262 ESP_Rueckwaertsfahrt_erkannt 0;
BA_ "GenSigSendType" SG_ 262 ESP_Schwelle_Unterdruck 0;
BA_ "GenSigSwitchedByIgnition" SG_ 262 ESP_Schwelle_Unterdruck 0;
BA_ "GenSigSendType" SG_ 262 ESP_StartStopp_Info 0;
BA_ "GenSigSwitchedByIgnition" SG_ 262 ESP_StartStopp_Info 0;
BA_ "GenSigSendType" SG_ 262 ESP_Status_Anfahrhilfe 0;
BA_ "GenSigSwitchedByIgnition" SG_ 262 ESP_Status_Anfahrhilfe 0;
BA_ "GenSigSendType" SG_ 262 ESP_Status_Bremsdruck 0;
BA_ "GenSigSwitchedByIgnition" SG_ 262 ESP_Status_Bremsdruck 0;
BA_ "GenSigSendType" SG_ 262 ESP_Status_Bremsentemp 0;
BA_ "GenSigSwitchedByIgnition" SG_ 262 ESP_Status_Bremsentemp 0;
BA_ "GenSigSendType" SG_ 262 ESP_Verz_EPB_aktiv 0;
BA_ "GenSigSwitchedByIgnition" SG_ 262 ESP_Verz_EPB_aktiv 0;
BA_ "GenSigSendType" SG_ 262 ESP_Verzoeg_EPB_verf 0;
BA_ "GenSigSwitchedByIgnition" SG_ 262 ESP_Verzoeg_EPB_verf 0;
BA_ "GenSigSendType" SG_ 914 ESC_cAQP_Trigger 0;
BA_ "GenSigSendType" SG_ 914 ESP_07_BZ 0;
BA_ "GenSigFuncType" SG_ 914 ESP_07_BZ 1;
BA_ "GenSigSwitchedByIgnition" SG_ 914 ESP_07_BZ 0;
BA_ "GenSigSendType" SG_ 914 ESP_07_CRC 0;
BA_ "GenSigFuncType" SG_ 914 ESP_07_CRC 2;
BA_ "GenSigSwitchedByIgnition" SG_ 914 ESP_07_CRC 0;
BA_ "GenSigSendType" SG_ 914 ESP_Allrad_Antrieb 0;
BA_ "GenSigFuncType" SG_ 914 ESP_Allrad_Antrieb 8;
BA_ "GenSigSwitchedByIgnition" SG_ 914 ESP_Allrad_Antrieb 0;
BA_ "GenSigSendType" SG_ 914 ESP_Codierung_ADS 0;
BA_ "GenSigFuncType" SG_ 914 ESP_Codierung_ADS 8;
BA_ "GenSigSwitchedByIgnition" SG_ 914 ESP_Codierung_ADS 0;
BA_ "GenSigSendType" SG_ 914 ESP_MKB_ausloesbar 0;
BA_ "GenSigSwitchedByIgnition" SG_ 914 ESP_MKB_ausloesbar 0;
BA_ "GenSigSendType" SG_ 914 ESP_nachtr_Stopp_Anf 0;
BA_ "GenSigSwitchedByIgnition" SG_ 914 ESP_nachtr_Stopp_Anf 0;
BA_ "GenSigSendType" SG_ 914 ESP_OBD_Status 0;
BA_ "GenSigSwitchedByIgnition" SG_ 914 ESP_OBD_Status 0;
BA_ "GenSigSendType" SG_ 914 ESP_Offroad_Modus 0;
BA_ "GenSigSwitchedByIgnition" SG_ 914 ESP_Offroad_Modus 0;
BA_ "GenSigSendType" SG_ 914 ESP_Qualifizierung_Antriebsart 0;
BA_ "GenSigFuncType" SG_ 914 ESP_Qualifizierung_Antriebsart 8;
BA_ "GenSigSwitchedByIgnition" SG_ 914 ESP_Qualifizierung_Antriebsart 0;
BA_ "GenSigSendType" SG_ 914 ESP_Rollenmodus_Deaktivieren 3;
BA_ "GenSigSwitchedByIgnition" SG_ 914 ESP_Rollenmodus_Deaktivieren 0;
BA_ "GenSigSendType" SG_ 914 ESP_RTA_HL 0;
BA_ "GenSigStartValue" SG_ 914 ESP_RTA_HL 254;
BA_ "GenSigSwitchedByIgnition" SG_ 914 ESP_RTA_HL 0;
BA_ "Fehlerwert" SG_ 914 ESP_RTA_HL 255;
BA_ "GenSigSendType" SG_ 914 ESP_RTA_HR 0;
BA_ "GenSigStartValue" SG_ 914 ESP_RTA_HR 254;
BA_ "GenSigSwitchedByIgnition" SG_ 914 ESP_RTA_HR 0;
BA_ "Fehlerwert" SG_ 914 ESP_RTA_HR 255;
BA_ "GenSigSendType" SG_ 914 ESP_RTA_VR 0;
BA_ "GenSigStartValue" SG_ 914 ESP_RTA_VR 254;
BA_ "GenSigSwitchedByIgnition" SG_ 914 ESP_RTA_VR 0;
BA_ "Fehlerwert" SG_ 914 ESP_RTA_VR 255;
BA_ "GenSigSendType" SG_ 914 ESP_Stat_FallBack_eBKV 0;
BA_ "GenSigSwitchedByIgnition" SG_ 914 ESP_Stat_FallBack_eBKV 0;
BA_ "GenSigSendType" SG_ 914 OBD_Fehler_Radsensor_HL 0;
BA_ "GenSigSwitchedByIgnition" SG_ 914 OBD_Fehler_Radsensor_HL 0;
BA_ "GenSigSendType" SG_ 914 OBD_Fehler_Radsensor_HR 0;
BA_ "GenSigSwitchedByIgnition" SG_ 914 OBD_Fehler_Radsensor_HR 0;
BA_ "GenSigSendType" SG_ 914 OBD_Fehler_Radsensor_VL 0;
BA_ "GenSigSwitchedByIgnition" SG_ 914 OBD_Fehler_Radsensor_VL 0;
BA_ "GenSigSendType" SG_ 914 OBD_Fehler_Radsensor_VR 0;
BA_ "GenSigSwitchedByIgnition" SG_ 914 OBD_Fehler_Radsensor_VR 0;
BA_ "GenSigSendType" SG_ 278 ESP_10_BZ 0;
BA_ "GenSigFuncType" SG_ 278 ESP_10_BZ 1;
BA_ "GenSigSwitchedByIgnition" SG_ 278 ESP_10_BZ 0;
BA_ "GenSigSendType" SG_ 278 ESP_10_CRC 0;
BA_ "GenSigFuncType" SG_ 278 ESP_10_CRC 2;
BA_ "GenSigSwitchedByIgnition" SG_ 278 ESP_10_CRC 0;
BA_ "GenSigSendType" SG_ 278 ESP_HL_Fahrtrichtung 0;
BA_ "GenSigStartValue" SG_ 278 ESP_HL_Fahrtrichtung 2;
BA_ "GenSigSwitchedByIgnition" SG_ 278 ESP_HL_Fahrtrichtung 0;
BA_ "GenSigSendType" SG_ 278 ESP_HR_Fahrtrichtung 0;
BA_ "GenSigStartValue" SG_ 278 ESP_HR_Fahrtrichtung 2;
BA_ "GenSigSwitchedByIgnition" SG_ 278 ESP_HR_Fahrtrichtung 0;
BA_ "GenSigSendType" SG_ 278 ESP_QBit_Wegimpuls_HL 0;
BA_ "GenSigStartValue" SG_ 278 ESP_QBit_Wegimpuls_HL 1;
BA_ "GenSigSwitchedByIgnition" SG_ 278 ESP_QBit_Wegimpuls_HL 0;
BA_ "GenSigSendType" SG_ 278 ESP_QBit_Wegimpuls_HR 0;
BA_ "GenSigStartValue" SG_ 278 ESP_QBit_Wegimpuls_HR 1;
BA_ "GenSigSwitchedByIgnition" SG_ 278 ESP_QBit_Wegimpuls_HR 0;
BA_ "GenSigSendType" SG_ 278 ESP_QBit_Wegimpuls_VL 0;
BA_ "GenSigStartValue" SG_ 278 ESP_QBit_Wegimpuls_VL 1;
BA_ "GenSigSwitchedByIgnition" SG_ 278 ESP_QBit_Wegimpuls_VL 0;
BA_ "GenSigSendType" SG_ 278 ESP_QBit_Wegimpuls_VR 0;
BA_ "GenSigStartValue" SG_ 278 ESP_QBit_Wegimpuls_VR 1;
BA_ "GenSigSwitchedByIgnition" SG_ 278 ESP_QBit_Wegimpuls_VR 0;
BA_ "GenSigSendType" SG_ 278 ESP_VL_Fahrtrichtung 0;
BA_ "GenSigStartValue" SG_ 278 ESP_VL_Fahrtrichtung 2;
BA_ "GenSigSwitchedByIgnition" SG_ 278 ESP_VL_Fahrtrichtung 0;
BA_ "GenSigSendType" SG_ 278 ESP_VR_Fahrtrichtung 0;
BA_ "GenSigStartValue" SG_ 278 ESP_VR_Fahrtrichtung 2;
BA_ "GenSigSwitchedByIgnition" SG_ 278 ESP_VR_Fahrtrichtung 0;
BA_ "GenSigSendType" SG_ 278 ESP_Wegimpuls_HL 0;
BA_ "GenSigStartValue" SG_ 278 ESP_Wegimpuls_HL 1021;
BA_ "GenSigSwitchedByIgnition" SG_ 278 ESP_Wegimpuls_HL 0;
BA_ "Fehlerwert" SG_ 278 ESP_Wegimpuls_HL 1023;
BA_ "GenSigSendType" SG_ 278 ESP_Wegimpuls_HR 0;
BA_ "GenSigStartValue" SG_ 278 ESP_Wegimpuls_HR 1021;
BA_ "GenSigSwitchedByIgnition" SG_ 278 ESP_Wegimpuls_HR 0;
BA_ "Fehlerwert" SG_ 278 ESP_Wegimpuls_HR 1023;
BA_ "GenSigSendType" SG_ 278 ESP_Wegimpuls_VL 0;
BA_ "GenSigStartValue" SG_ 278 ESP_Wegimpuls_VL 1021;
BA_ "GenSigSwitchedByIgnition" SG_ 278 ESP_Wegimpuls_VL 0;
BA_ "Fehlerwert" SG_ 278 ESP_Wegimpuls_VL 1023;
BA_ "GenSigSendType" SG_ 278 ESP_Wegimpuls_VR 0;
BA_ "GenSigStartValue" SG_ 278 ESP_Wegimpuls_VR 1021;
BA_ "GenSigSwitchedByIgnition" SG_ 278 ESP_Wegimpuls_VR 0;
BA_ "Fehlerwert" SG_ 278 ESP_Wegimpuls_VR 1023;
BA_ "GenSigSendType" SG_ 418 ESP_15_BZ 0;
BA_ "GenSigFuncType" SG_ 418 ESP_15_BZ 1;
BA_ "GenSigSwitchedByIgnition" SG_ 418 ESP_15_BZ 0;
BA_ "GenSigSendType" SG_ 418 ESP_15_CRC 0;
BA_ "GenSigFuncType" SG_ 418 ESP_15_CRC 2;
BA_ "GenSigSwitchedByIgnition" SG_ 418 ESP_15_CRC 0;
BA_ "GenSigSendType" SG_ 418 ESP_Haltemoment 0;
BA_ "GenSigStartValue" SG_ 418 ESP_Haltemoment 1022;
BA_ "GenSigSwitchedByIgnition" SG_ 418 ESP_Haltemoment 0;
BA_ "Fehlerwert" SG_ 418 ESP_Haltemoment 1023;
BA_ "GenSigSendType" SG_ 418 ESP_Index_Haltemoment 0;
BA_ "GenSigSwitchedByIgnition" SG_ 418 ESP_Index_Haltemoment 0;
BA_ "GenSigSendType" SG_ 418 HMS_aktives_System 3;
BA_ "GenSigSwitchedByIgnition" SG_ 418 HMS_aktives_System 0;
BA_ "GenSigSendType" SG_ 418 HMS_Anforderung_GE 0;
BA_ "GenSigSwitchedByIgnition" SG_ 418 HMS_Anforderung_GE 0;
BA_ "GenSigSendType" SG_ 418 HMS_Fehlerstatus 3;
BA_ "GenSigSwitchedByIgnition" SG_ 418 HMS_Fehlerstatus 0;
BA_ "GenSigSendType" SG_ 418 HMS_halten_nicht_verfuegbar 0;
BA_ "GenSigSwitchedByIgnition" SG_ 418 HMS_halten_nicht_verfuegbar 0;
BA_ "GenSigSendType" SG_ 418 HMS_Konsistenz_ACC 0;
BA_ "GenSigSwitchedByIgnition" SG_ 418 HMS_Konsistenz_ACC 0;
BA_ "GenSigSendType" SG_ 418 HMS_Konsistenz_GE 0;
BA_ "GenSigSwitchedByIgnition" SG_ 418 HMS_Konsistenz_GE 0;
BA_ "GenSigSendType" SG_ 418 HMS_Konsistenz_HVLM 3;
BA_ "GenSigSwitchedByIgnition" SG_ 418 HMS_Konsistenz_HVLM 0;
BA_ "GenSigSendType" SG_ 418 HMS_Konsistenz_IPA 3;
BA_ "GenSigSwitchedByIgnition" SG_ 418 HMS_Konsistenz_IPA 0;
BA_ "GenSigSendType" SG_ 418 HMS_Konsistenz_MO 0;
BA_ "GenSigSwitchedByIgnition" SG_ 418 HMS_Konsistenz_MO 0;
BA_ "GenSigSendType" SG_ 418 HMS_Konsistenz_STA 0;
BA_ "GenSigSwitchedByIgnition" SG_ 418 HMS_Konsistenz_STA 0;
BA_ "GenSigSendType" SG_ 418 HMS_Notstopp_Status 0;
BA_ "GenSigSwitchedByIgnition" SG_ 418 HMS_Notstopp_Status 0;
BA_ "GenSigSendType" SG_ 418 HMS_P_beibehalten_GE 0;
BA_ "GenSigStartValue" SG_ 418 HMS_P_beibehalten_GE 2;
BA_ "GenSigSwitchedByIgnition" SG_ 418 HMS_P_beibehalten_GE 0;
BA_ "Fehlerwert" SG_ 418 HMS_P_beibehalten_GE 3;
BA_ "GenSigSendType" SG_ 418 HMS_parken_nicht_verfuegbar 0;
BA_ "GenSigSwitchedByIgnition" SG_ 418 HMS_parken_nicht_verfuegbar 0;
BA_ "GenSigSendType" SG_ 418 HMS_Stillstand 3;
BA_ "GenSigStartValue" SG_ 418 HMS_Stillstand 6;
BA_ "GenSigSwitchedByIgnition" SG_ 418 HMS_Stillstand 0;
BA_ "Fehlerwert" SG_ 418 HMS_Stillstand 7;
BA_ "GenSigSendType" SG_ 418 HMS_Systemstatus 3;
BA_ "GenSigStartValue" SG_ 418 HMS_Systemstatus 14;
BA_ "GenSigSwitchedByIgnition" SG_ 418 HMS_Systemstatus 0;
BA_ "Fehlerwert" SG_ 418 HMS_Systemstatus 15;
BA_ "GenSigSendType" SG_ 418 NL_PRIM_STP_01_Status 0;
BA_ "GenSigSwitchedByIgnition" SG_ 418 NL_PRIM_STP_01_Status 0;
BA_ "GenSigSendType" SG_ 418 VMM_Warnblinken 3;
BA_ "GenSigSwitchedByIgnition" SG_ 418 VMM_Warnblinken 0;
BA_ "GenSigSendType" SG_ 418 VZM_Status 0;
BA_ "GenSigSwitchedByIgnition" SG_ 418 VZM_Status 0;
BA_ "Fehlerwert" SG_ 418 VZM_Status 4;
BA_ "GenSigSendType" SG_ 1629 BR_QBit_Reifenumfang 0;
BA_ "GenSigStartValue" SG_ 1629 BR_QBit_Reifenumfang 1;
BA_ "GenSigSwitchedByIgnition" SG_ 1629 BR_QBit_Reifenumfang 0;
BA_ "GenSigSendType" SG_ 1629 BR_Reifenumfang 0;
BA_ "GenSigSwitchedByIgnition" SG_ 1629 BR_Reifenumfang 0;
BA_ "GenSigSendType" SG_ 1629 BR_Systemart 0;
BA_ "GenSigFuncType" SG_ 1629 BR_Systemart 8;
BA_ "GenSigSwitchedByIgnition" SG_ 1629 BR_Systemart 0;
BA_ "GenSigSendType" SG_ 1629 ESP_20_BZ 0;
BA_ "GenSigFuncType" SG_ 1629 ESP_20_BZ 1;
BA_ "GenSigSwitchedByIgnition" SG_ 1629 ESP_20_BZ 0;
BA_ "GenSigSendType" SG_ 1629 ESP_20_CRC 0;
BA_ "GenSigFuncType" SG_ 1629 ESP_20_CRC 2;
BA_ "GenSigSwitchedByIgnition" SG_ 1629 ESP_20_CRC 0;
BA_ "GenSigSendType" SG_ 1629 ESP_Charisma_FahrPr 0;
BA_ "GenSigSwitchedByIgnition" SG_ 1629 ESP_Charisma_FahrPr 0;
BA_ "GenSigSendType" SG_ 1629 ESP_Charisma_Status 0;
BA_ "GenSigSwitchedByIgnition" SG_ 1629 ESP_Charisma_Status 0;
BA_ "GenSigSendType" SG_ 1629 ESP_Dachrelingsensor 0;
BA_ "GenSigSwitchedByIgnition" SG_ 1629 ESP_Dachrelingsensor 0;
BA_ "Fehlerwert" SG_ 1629 ESP_Dachrelingsensor 3;
BA_ "GenSigSendType" SG_ 1629 ESP_SpannungsAnf_02 0;
BA_ "GenSigSwitchedByIgnition" SG_ 1629 ESP_SpannungsAnf_02 0;
BA_ "GenSigSendType" SG_ 1629 ESP_Stoppverbot_Anz_01 0;
BA_ "GenSigSwitchedByIgnition" SG_ 1629 ESP_Stoppverbot_Anz_01 0;
BA_ "GenSigSendType" SG_ 1629 ESP_Stoppverbot_Anz_02 0;
BA_ "GenSigSwitchedByIgnition" SG_ 1629 ESP_Stoppverbot_Anz_02 0;
BA_ "GenSigSendType" SG_ 1629 ESP_Stoppverbot_Anz_03 0;
BA_ "GenSigSwitchedByIgnition" SG_ 1629 ESP_Stoppverbot_Anz_03 0;
BA_ "GenSigSendType" SG_ 1629 ESP_Stoppverbot_Anz_04 0;
BA_ "GenSigSwitchedByIgnition" SG_ 1629 ESP_Stoppverbot_Anz_04 0;
BA_ "GenSigSendType" SG_ 1629 ESP_Stoppverbot_Anz_05 0;
BA_ "GenSigSwitchedByIgnition" SG_ 1629 ESP_Stoppverbot_Anz_05 0;
BA_ "GenSigSendType" SG_ 1629 ESP_Stoppverbot_Anz_06 0;
BA_ "GenSigSwitchedByIgnition" SG_ 1629 ESP_Stoppverbot_Anz_06 0;
BA_ "GenSigSendType" SG_ 1629 ESP_Stoppverbot_Anz_07 0;
BA_ "GenSigSwitchedByIgnition" SG_ 1629 ESP_Stoppverbot_Anz_07 0;
BA_ "GenSigSendType" SG_ 1629 ESP_Stoppverbot_Anz_08 0;
BA_ "GenSigSwitchedByIgnition" SG_ 1629 ESP_Stoppverbot_Anz_08 0;
BA_ "GenSigSendType" SG_ 1629 ESP_Stoppverbot_Anz_Std 0;
BA_ "GenSigSwitchedByIgnition" SG_ 1629 ESP_Stoppverbot_Anz_Std 0;
BA_ "GenSigSendType" SG_ 1629 ESP_Wiederstart_Anz_01 0;
BA_ "GenSigSwitchedByIgnition" SG_ 1629 ESP_Wiederstart_Anz_01 0;
BA_ "GenSigSendType" SG_ 1629 ESP_Wiederstart_Anz_02 0;
BA_ "GenSigSwitchedByIgnition" SG_ 1629 ESP_Wiederstart_Anz_02 0;
BA_ "GenSigSendType" SG_ 1629 ESP_Wiederstart_Anz_03 0;
BA_ "GenSigSwitchedByIgnition" SG_ 1629 ESP_Wiederstart_Anz_03 0;
BA_ "GenSigSendType" SG_ 1629 ESP_Wiederstart_Anz_04 0;
BA_ "GenSigSwitchedByIgnition" SG_ 1629 ESP_Wiederstart_Anz_04 0;
BA_ "GenSigSendType" SG_ 1629 ESP_Zaehnezahl 0;
BA_ "GenSigFuncType" SG_ 1629 ESP_Zaehnezahl 8;
BA_ "GenSigSwitchedByIgnition" SG_ 1629 ESP_Zaehnezahl 0;
BA_ "GenSigSendType" SG_ 1629 HDC_Charisma_FahrPr 0;
BA_ "GenSigSwitchedByIgnition" SG_ 1629 HDC_Charisma_FahrPr 0;
BA_ "GenSigSendType" SG_ 1629 HDC_Charisma_Status 0;
BA_ "GenSigSwitchedByIgnition" SG_ 1629 HDC_Charisma_Status 0;
BA_ "GenSigSendType" SG_ 253 ABS_Bremsung 0;
BA_ "GenSigSwitchedByIgnition" SG_ 253 ABS_Bremsung 0;
BA_ "GenSigSendType" SG_ 253 ASR_Anf 0;
BA_ "GenSigSwitchedByIgnition" SG_ 253 ASR_Anf 0;
BA_ "GenSigSendType" SG_ 253 ASR_Schalteingriff 0;
BA_ "GenSigSwitchedByIgnition" SG_ 253 ASR_Schalteingriff 0;
BA_ "GenSigSendType" SG_ 253 ASR_Tastung_passiv 0;
BA_ "GenSigSwitchedByIgnition" SG_ 253 ASR_Tastung_passiv 0;
BA_ "GenSigSendType" SG_ 253 BR_Eingriffsmoment 0;
BA_ "GenSigStartValue" SG_ 253 BR_Eingriffsmoment 1022;
BA_ "GenSigSwitchedByIgnition" SG_ 253 BR_Eingriffsmoment 0;
BA_ "Fehlerwert" SG_ 253 BR_Eingriffsmoment 1023;
BA_ "GenSigSendType" SG_ 253 EBV_Eingriff 0;
BA_ "GenSigSwitchedByIgnition" SG_ 253 EBV_Eingriff 0;
BA_ "GenSigSendType" SG_ 253 EDS_Eingriff 0;
BA_ "GenSigSwitchedByIgnition" SG_ 253 EDS_Eingriff 0;
BA_ "GenSigSendType" SG_ 253 ESC_Neutralschaltung 0;
BA_ "GenSigSwitchedByIgnition" SG_ 253 ESC_Neutralschaltung 0;
BA_ "GenSigSendType" SG_ 253 ESC_v_Signal_Qualifier_High_Low 0;
BA_ "GenSigStartValue" SG_ 253 ESC_v_Signal_Qualifier_High_Low 6;
BA_ "GenSigSwitchedByIgnition" SG_ 253 ESC_v_Signal_Qualifier_High_Low 0;
BA_ "Fehlerwert" SG_ 253 ESC_v_Signal_Qualifier_High_Low 7;
BA_ "GenSigSendType" SG_ 253 ESP_21_BZ 0;
BA_ "GenSigFuncType" SG_ 253 ESP_21_BZ 1;
BA_ "GenSigSwitchedByIgnition" SG_ 253 ESP_21_BZ 0;
BA_ "GenSigSendType" SG_ 253 ESP_21_CRC 0;
BA_ "GenSigFuncType" SG_ 253 ESP_21_CRC 2;
BA_ "GenSigSwitchedByIgnition" SG_ 253 ESP_21_CRC 0;
BA_ "GenSigSendType" SG_ 253 ESP_ASP 0;
BA_ "GenSigSwitchedByIgnition" SG_ 253 ESP_ASP 0;
BA_ "GenSigSendType" SG_ 253 ESP_Diagnose 0;
BA_ "GenSigSwitchedByIgnition" SG_ 253 ESP_Diagnose 0;
BA_ "GenSigSendType" SG_ 253 ESP_Eingriff 0;
BA_ "GenSigSwitchedByIgnition" SG_ 253 ESP_Eingriff 0;
BA_ "GenSigSendType" SG_ 253 ESP_QBit_v_Signal 0;
BA_ "GenSigStartValue" SG_ 253 ESP_QBit_v_Signal 1;
BA_ "GenSigSwitchedByIgnition" SG_ 253 ESP_QBit_v_Signal 0;
BA_ "GenSigSendType" SG_ 253 ESP_Systemstatus 0;
BA_ "GenSigSwitchedByIgnition" SG_ 253 ESP_Systemstatus 0;
BA_ "GenSigSendType" SG_ 253 ESP_Tastung_passiv 0;
BA_ "GenSigSwitchedByIgnition" SG_ 253 ESP_Tastung_passiv 0;
BA_ "GenSigSendType" SG_ 253 ESP_v_Signal 0;
BA_ "GenSigStartValue" SG_ 253 ESP_v_Signal 65534;
BA_ "GenSigSwitchedByIgnition" SG_ 253 ESP_v_Signal 0;
BA_ "Fehlerwert" SG_ 253 ESP_v_Signal 65535;
BA_ "GenSigMissingSourceValue" SG_ 253 ESP_v_Signal 65534;
BA_ "GenSigSendType" SG_ 253 ESP_Vorsteuerung 0;
BA_ "GenSigSwitchedByIgnition" SG_ 253 ESP_Vorsteuerung 0;
BA_ "GenSigSendType" SG_ 253 MSR_Anf 0;
BA_ "GenSigSwitchedByIgnition" SG_ 253 MSR_Anf 0;
BA_ "GenSigSendType" SG_ 253 OBD_QBit_Schlechtweg 0;
BA_ "GenSigStartValue" SG_ 253 OBD_QBit_Schlechtweg 1;
BA_ "GenSigSwitchedByIgnition" SG_ 253 OBD_QBit_Schlechtweg 0;
BA_ "GenSigSendType" SG_ 253 OBD_Schlechtweg 0;
BA_ "GenSigSwitchedByIgnition" SG_ 253 OBD_Schlechtweg 0;
BA_ "GenSigSendType" SG_ 239 ESP_22_BZ 0;
BA_ "GenSigFuncType" SG_ 239 ESP_22_BZ 1;
BA_ "GenSigSwitchedByIgnition" SG_ 239 ESP_22_BZ 0;
BA_ "GenSigSendType" SG_ 239 ESP_22_CRC 0;
BA_ "GenSigFuncType" SG_ 239 ESP_22_CRC 2;
BA_ "GenSigSwitchedByIgnition" SG_ 239 ESP_22_CRC 0;
BA_ "GenSigSendType" SG_ 239 ESP_FZR_uebersteuern 0;
BA_ "GenSigStartValue" SG_ 239 ESP_FZR_uebersteuern 254;
BA_ "NWM-WakeupAllowed" SG_ 239 ESP_FZR_uebersteuern 1;
BA_ "GenSigSwitchedByIgnition" SG_ 239 ESP_FZR_uebersteuern 0;
BA_ "Fehlerwert" SG_ 239 ESP_FZR_uebersteuern 255;
BA_ "GenSigMissingSourceValue" SG_ 239 ESP_FZR_uebersteuern 254;
BA_ "GenSigSendType" SG_ 239 ESP_FZR_untersteuern 0;
BA_ "GenSigStartValue" SG_ 239 ESP_FZR_untersteuern 254;
BA_ "NWM-WakeupAllowed" SG_ 239 ESP_FZR_untersteuern 1;
BA_ "GenSigSwitchedByIgnition" SG_ 239 ESP_FZR_untersteuern 0;
BA_ "Fehlerwert" SG_ 239 ESP_FZR_untersteuern 255;
BA_ "GenSigMissingSourceValue" SG_ 239 ESP_FZR_untersteuern 254;
BA_ "GenSigSendType" SG_ 239 ESP_HL_Bremsmoment 0;
BA_ "GenSigStartValue" SG_ 239 ESP_HL_Bremsmoment 254;
BA_ "Fehlerwert" SG_ 239 ESP_HL_Bremsmoment 255;
BA_ "GenSigSendType" SG_ 239 ESP_HR_Bremsmoment 0;
BA_ "GenSigStartValue" SG_ 239 ESP_HR_Bremsmoment 254;
BA_ "Fehlerwert" SG_ 239 ESP_HR_Bremsmoment 255;
BA_ "GenSigSendType" SG_ 239 ESP_QBit_HL_Bremsmoment 0;
BA_ "GenSigStartValue" SG_ 239 ESP_QBit_HL_Bremsmoment 1;
BA_ "GenSigSendType" SG_ 239 ESP_QBit_HR_Bremsmoment 0;
BA_ "GenSigStartValue" SG_ 239 ESP_QBit_HR_Bremsmoment 1;
BA_ "GenSigSendType" SG_ 239 ESP_QBit_VL_Bremsmoment 0;
BA_ "GenSigStartValue" SG_ 239 ESP_QBit_VL_Bremsmoment 1;
BA_ "GenSigSendType" SG_ 239 ESP_QBit_VR_Bremsmoment 0;
BA_ "GenSigStartValue" SG_ 239 ESP_QBit_VR_Bremsmoment 1;
BA_ "GenSigSendType" SG_ 239 ESP_VL_Bremsmoment 0;
BA_ "GenSigStartValue" SG_ 239 ESP_VL_Bremsmoment 254;
BA_ "Fehlerwert" SG_ 239 ESP_VL_Bremsmoment 255;
BA_ "GenSigSendType" SG_ 239 ESP_VR_Bremsmoment 0;
BA_ "GenSigStartValue" SG_ 239 ESP_VR_Bremsmoment 254;
BA_ "Fehlerwert" SG_ 239 ESP_VR_Bremsmoment 255;
BA_ "GenSigSendType" SG_ 1470 BR_QBit_Reifenumfang_sekundaer 0;
BA_ "GenSigStartValue" SG_ 1470 BR_QBit_Reifenumfang_sekundaer 1;
BA_ "GenSigSwitchedByIgnition" SG_ 1470 BR_QBit_Reifenumfang_sekundaer 0;
BA_ "GenSigSendType" SG_ 1470 BR_Reifenumfang_sekundaer 0;
BA_ "GenSigSwitchedByIgnition" SG_ 1470 BR_Reifenumfang_sekundaer 0;
BA_ "GenSigSendType" SG_ 1470 ESP_23_BZ 0;
BA_ "GenSigFuncType" SG_ 1470 ESP_23_BZ 1;
BA_ "GenSigSwitchedByIgnition" SG_ 1470 ESP_23_BZ 0;
BA_ "GenSigSendType" SG_ 1470 ESP_23_CRC 0;
BA_ "GenSigFuncType" SG_ 1470 ESP_23_CRC 2;
BA_ "GenSigSwitchedByIgnition" SG_ 1470 ESP_23_CRC 0;
BA_ "GenSigSendType" SG_ 1470 ESP_Gierrate_Offset_2 0;
BA_ "GenSigStartValue" SG_ 1470 ESP_Gierrate_Offset_2 2046;
BA_ "GenSigSwitchedByIgnition" SG_ 1470 ESP_Gierrate_Offset_2 0;
BA_ "Fehlerwert" SG_ 1470 ESP_Gierrate_Offset_2 2047;
BA_ "GenSigSendType" SG_ 1470 ESP_Laengsbeschleunigung_Offset 0;
BA_ "GenSigStartValue" SG_ 1470 ESP_Laengsbeschleunigung_Offset 254;
BA_ "GenSigSwitchedByIgnition" SG_ 1470 ESP_Laengsbeschleunigung_Offset 0;
BA_ "Fehlerwert" SG_ 1470 ESP_Laengsbeschleunigung_Offset 255;
BA_ "GenSigSendType" SG_ 1470 ESP_Lenkwinkel_Offset 0;
BA_ "GenSigStartValue" SG_ 1470 ESP_Lenkwinkel_Offset 510;
BA_ "GenSigSwitchedByIgnition" SG_ 1470 ESP_Lenkwinkel_Offset 0;
BA_ "Fehlerwert" SG_ 1470 ESP_Lenkwinkel_Offset 511;
BA_ "GenSigSendType" SG_ 1470 ESP_Querbeschleunigung_Offset 0;
BA_ "GenSigStartValue" SG_ 1470 ESP_Querbeschleunigung_Offset 62;
BA_ "GenSigSwitchedByIgnition" SG_ 1470 ESP_Querbeschleunigung_Offset 0;
BA_ "Fehlerwert" SG_ 1470 ESP_Querbeschleunigung_Offset 63;
BA_ "GenSigSendType" SG_ 1470 ESP_Status_Bremsentemp_Anz 0;
BA_ "GenSigSwitchedByIgnition" SG_ 1470 ESP_Status_Bremsentemp_Anz 0;
BA_ "Fehlerwert" SG_ 1470 ESP_Status_Bremsentemp_Anz 7;
BA_ "GenSigSendType" SG_ 795 ABS_Lampe 0;
BA_ "GenSigStartValue" SG_ 795 ABS_Lampe 1;
BA_ "GenSigSwitchedByIgnition" SG_ 795 ABS_Lampe 0;
BA_ "GenSigSendType" SG_ 795 BK_Lampe_02 0;
BA_ "GenSigStartValue" SG_ 795 BK_Lampe_02 1;
BA_ "GenSigSwitchedByIgnition" SG_ 795 BK_Lampe_02 0;
BA_ "GenSigSendType" SG_ 795 ESP_24_BZ 0;
BA_ "GenSigFuncType" SG_ 795 ESP_24_BZ 1;
BA_ "GenSigSwitchedByIgnition" SG_ 795 ESP_24_BZ 0;
BA_ "GenSigSendType" SG_ 795 ESP_24_CRC 0;
BA_ "GenSigFuncType" SG_ 795 ESP_24_CRC 2;
BA_ "GenSigSwitchedByIgnition" SG_ 795 ESP_24_CRC 0;
BA_ "GenSigSendType" SG_ 795 ESP_BKV_Warnung 0;
BA_ "GenSigSwitchedByIgnition" SG_ 795 ESP_BKV_Warnung 0;
BA_ "GenSigSendType" SG_ 795 ESP_Fehlerstatus_Wegimp 0;
BA_ "GenSigSwitchedByIgnition" SG_ 795 ESP_Fehlerstatus_Wegimp 0;
BA_ "GenSigSendType" SG_ 795 ESP_HDC_Geschw_Farbe 0;
BA_ "GenSigSwitchedByIgnition" SG_ 795 ESP_HDC_Geschw_Farbe 0;
BA_ "GenSigSendType" SG_ 795 ESP_HDC_Regelgeschw 0;
BA_ "GenSigStartValue" SG_ 795 ESP_HDC_Regelgeschw 126;
BA_ "GenSigSwitchedByIgnition" SG_ 795 ESP_HDC_Regelgeschw 0;
BA_ "Fehlerwert" SG_ 795 ESP_HDC_Regelgeschw 127;
BA_ "GenSigSendType" SG_ 795 ESP_Lampe 0;
BA_ "GenSigStartValue" SG_ 795 ESP_Lampe 1;
BA_ "GenSigSwitchedByIgnition" SG_ 795 ESP_Lampe 0;
BA_ "GenSigSendType" SG_ 795 ESP_m_Raddrehz 0;
BA_ "GenSigStartValue" SG_ 795 ESP_m_Raddrehz 32766;
BA_ "GenSigSwitchedByIgnition" SG_ 795 ESP_m_Raddrehz 0;
BA_ "Fehlerwert" SG_ 795 ESP_m_Raddrehz 32767;
BA_ "GenSigSendType" SG_ 795 ESP_Meldungen 0;
BA_ "GenSigSwitchedByIgnition" SG_ 795 ESP_Meldungen 0;
BA_ "GenSigSendType" SG_ 795 ESP_Off_Lampe 0;
BA_ "GenSigSwitchedByIgnition" SG_ 795 ESP_Off_Lampe 0;
BA_ "GenSigSendType" SG_ 795 ESP_QBit_Wegimp_VA 0;
BA_ "GenSigStartValue" SG_ 795 ESP_QBit_Wegimp_VA 1;
BA_ "GenSigSwitchedByIgnition" SG_ 795 ESP_QBit_Wegimp_VA 0;
BA_ "GenSigSendType" SG_ 795 ESP_Textanzeigen_03 0;
BA_ "GenSigSwitchedByIgnition" SG_ 795 ESP_Textanzeigen_03 0;
BA_ "GenSigSendType" SG_ 795 ESP_Wegimp_Ueberlauf 0;
BA_ "GenSigSwitchedByIgnition" SG_ 795 ESP_Wegimp_Ueberlauf 0;
BA_ "GenSigSendType" SG_ 795 ESP_Wegimp_VA 0;
BA_ "GenSigSwitchedByIgnition" SG_ 795 ESP_Wegimp_VA 0;
BA_ "GenSigSendType" SG_ 795 TC_Lampe 0;
BA_ "GenSigSwitchedByIgnition" SG_ 795 TC_Lampe 0;
BA_ "GenSigSendType" SG_ 508 ESC_Anforderung_Airbrake 0;
BA_ "GenSigSwitchedByIgnition" SG_ 508 ESC_Anforderung_Airbrake 0;
BA_ "GenSigSendType" SG_ 508 ESC_FBA_Meldungen 3;
BA_ "GenSigSwitchedByIgnition" SG_ 508 ESC_FBA_Meldungen 0;
BA_ "GenSigSendType" SG_ 508 ESC_MBK_Meldungen 3;
BA_ "GenSigSwitchedByIgnition" SG_ 508 ESC_MBK_Meldungen 0;
BA_ "GenSigSendType" SG_ 508 ESC_Motorstartverzoegerung 0;
BA_ "GenSigSwitchedByIgnition" SG_ 508 ESC_Motorstartverzoegerung 0;
BA_ "GenSigSendType" SG_ 508 ESP_32_BZ 0;
BA_ "GenSigFuncType" SG_ 508 ESP_32_BZ 1;
BA_ "GenSigSwitchedByIgnition" SG_ 508 ESP_32_BZ 0;
BA_ "GenSigSendType" SG_ 508 ESP_32_CRC 0;
BA_ "GenSigFuncType" SG_ 508 ESP_32_CRC 2;
BA_ "GenSigSwitchedByIgnition" SG_ 508 ESP_32_CRC 0;
BA_ "GenSigSendType" SG_ 508 ESP_Aggregataktivitaet 0;
BA_ "GenSigSwitchedByIgnition" SG_ 508 ESP_Aggregataktivitaet 0;
BA_ "GenSigSendType" SG_ 508 ESP_AVH_LED 0;
BA_ "GenSigStartValue" SG_ 508 ESP_AVH_LED 6;
BA_ "GenSigSwitchedByIgnition" SG_ 508 ESP_AVH_LED 0;
BA_ "GenSigSendType" SG_ 508 ESP_EDS_Anzeige 3;
BA_ "GenSigSwitchedByIgnition" SG_ 508 ESP_EDS_Anzeige 0;
BA_ "GenSigSendType" SG_ 508 ESP_HDC_LED 0;
BA_ "GenSigStartValue" SG_ 508 ESP_HDC_LED 6;
BA_ "GenSigSwitchedByIgnition" SG_ 508 ESP_HDC_LED 0;
BA_ "GenSigSendType" SG_ 508 ESP_HDC_Textanzeigen 3;
BA_ "GenSigSwitchedByIgnition" SG_ 508 ESP_HDC_Textanzeigen 0;
BA_ "GenSigSendType" SG_ 508 ESP_HOLD_verf 0;
BA_ "GenSigSwitchedByIgnition" SG_ 508 ESP_HOLD_verf 0;
BA_ "GenSigSendType" SG_ 508 ESP_Notbremsanzeige 0;
BA_ "GenSigSwitchedByIgnition" SG_ 508 ESP_Notbremsanzeige 0;
BA_ "GenSigSendType" SG_ 508 ESP_Off_LED 0;
BA_ "GenSigStartValue" SG_ 508 ESP_Off_LED 6;
BA_ "GenSigSwitchedByIgnition" SG_ 508 ESP_Off_LED 0;
BA_ "GenSigSendType" SG_ 508 ESP_Offroad_Lampe 0;
BA_ "GenSigSwitchedByIgnition" SG_ 508 ESP_Offroad_Lampe 0;
BA_ "GenSigSendType" SG_ 508 ESP_Rollover_Status_dyn 0;
BA_ "GenSigSwitchedByIgnition" SG_ 508 ESP_Rollover_Status_dyn 0;
BA_ "GenSigSendType" SG_ 508 ESP_Rollover_Status_stat 0;
BA_ "GenSigSwitchedByIgnition" SG_ 508 ESP_Rollover_Status_stat 0;
BA_ "GenSigSendType" SG_ 508 ESP_Status_Bremsentemp_02 0;
BA_ "GenSigSwitchedByIgnition" SG_ 508 ESP_Status_Bremsentemp_02 0;
BA_ "GenSigSendType" SG_ 508 ESP_Stillstandsflag 0;
BA_ "GenSigSwitchedByIgnition" SG_ 508 ESP_Stillstandsflag 0;
BA_ "GenSigSendType" SG_ 508 ESP_Wiederstart_Anz_Std 3;
BA_ "GenSigSwitchedByIgnition" SG_ 508 ESP_Wiederstart_Anz_Std 0;
BA_ "GenSigSendType" SG_ 508 RLE_Anzeigen 3;
BA_ "GenSigSwitchedByIgnition" SG_ 508 RLE_Anzeigen 0;
BA_ "GenSigSendType" SG_ 600 ESP_54_BZ 0;
BA_ "GenSigFuncType" SG_ 600 ESP_54_BZ 1;
BA_ "GenSigSwitchedByIgnition" SG_ 600 ESP_54_BZ 0;
BA_ "GenSigSendType" SG_ 600 ESP_54_CRC 0;
BA_ "GenSigFuncType" SG_ 600 ESP_54_CRC 2;
BA_ "GenSigSwitchedByIgnition" SG_ 600 ESP_54_CRC 0;
BA_ "GenSigSendType" SG_ 600 ESP_DriftGong 3;
BA_ "GenSigSwitchedByIgnition" SG_ 600 ESP_DriftGong 0;
BA_ "GenSigSendType" SG_ 600 ESP_DriftLevel 3;
BA_ "GenSigSendType" SG_ 600 ESP_DriftStatus 3;
BA_ "GenSigSendType" SG_ 600 ESP_DriftText 3;
BA_ "GenSigSendType" SG_ 600 ESP_Slider_Gong 3;
BA_ "GenSigSwitchedByIgnition" SG_ 600 ESP_Slider_Gong 0;
BA_ "GenSigSendType" SG_ 600 ESP_Slider_ist_01 3;
BA_ "GenSigStartValue" SG_ 600 ESP_Slider_ist_01 127;
BA_ "GenSigSendType" SG_ 600 ESP_Slider_ist_02 3;
BA_ "GenSigStartValue" SG_ 600 ESP_Slider_ist_02 127;
BA_ "GenSigSendType" SG_ 600 ESP_Slider_ist_03 3;
BA_ "GenSigStartValue" SG_ 600 ESP_Slider_ist_03 127;
BA_ "GenSigSendType" SG_ 600 ESP_Slider_Lamp 3;
BA_ "GenSigSendType" SG_ 600 ESP_Slider_Status 3;
BA_ "GenSigSendType" SG_ 600 ESP_Slider_Text 3;
BA_ "GenSigSendType" SG_ 264 EFP_Anf_Bremsenkuehlung 0;
BA_ "GenSigSwitchedByIgnition" SG_ 264 EFP_Anf_Bremsenkuehlung 0;
BA_ "GenSigSendType" SG_ 264 FA_Fahrbahnunebenheit 0;
BA_ "GenSigStartValue" SG_ 264 FA_Fahrbahnunebenheit 254;
BA_ "GenSigSwitchedByIgnition" SG_ 264 FA_Fahrbahnunebenheit 0;
BA_ "Fehlerwert" SG_ 264 FA_Fahrbahnunebenheit 255;
BA_ "GenSigSendType" SG_ 264 FA_Hoehenwert_HL_00 0;
BA_ "GenSigStartValue" SG_ 264 FA_Hoehenwert_HL_00 254;
BA_ "Fehlerwert" SG_ 264 FA_Hoehenwert_HL_00 255;
BA_ "GenSigSendType" SG_ 264 FA_Hoehenwert_HR_00 0;
BA_ "GenSigStartValue" SG_ 264 FA_Hoehenwert_HR_00 254;
BA_ "Fehlerwert" SG_ 264 FA_Hoehenwert_HR_00 255;
BA_ "GenSigSendType" SG_ 264 FA_Hoehenwert_VL_00 0;
BA_ "GenSigStartValue" SG_ 264 FA_Hoehenwert_VL_00 254;
BA_ "Fehlerwert" SG_ 264 FA_Hoehenwert_VL_00 255;
BA_ "GenSigSendType" SG_ 264 FA_Hoehenwert_VR_00 0;
BA_ "GenSigStartValue" SG_ 264 FA_Hoehenwert_VR_00 254;
BA_ "Fehlerwert" SG_ 264 FA_Hoehenwert_VR_00 255;
BA_ "GenSigSendType" SG_ 264 FA_Hoehenwerte_kalibriert 0;
BA_ "GenSigSendType" SG_ 264 Fahrwerk_01_BZ 0;
BA_ "GenSigFuncType" SG_ 264 Fahrwerk_01_BZ 1;
BA_ "GenSigSendType" SG_ 264 Fahrwerk_01_CRC 0;
BA_ "GenSigFuncType" SG_ 264 Fahrwerk_01_CRC 2;
BA_ "GenSigSendType" SG_ 2527679659 FA_Niveau_Druck_HL 0;
BA_ "GenSigStartValue" SG_ 2527679659 FA_Niveau_Druck_HL 254;
BA_ "GenSigSwitchedByIgnition" SG_ 2527679659 FA_Niveau_Druck_HL 0;
BA_ "Fehlerwert" SG_ 2527679659 FA_Niveau_Druck_HL 255;
BA_ "GenSigSendType" SG_ 2527679659 FA_Niveau_Druck_HR 0;
BA_ "GenSigStartValue" SG_ 2527679659 FA_Niveau_Druck_HR 254;
BA_ "GenSigSwitchedByIgnition" SG_ 2527679659 FA_Niveau_Druck_HR 0;
BA_ "Fehlerwert" SG_ 2527679659 FA_Niveau_Druck_HR 255;
BA_ "GenSigSendType" SG_ 2527679659 FA_Niveau_Druck_VL 0;
BA_ "GenSigStartValue" SG_ 2527679659 FA_Niveau_Druck_VL 254;
BA_ "GenSigSwitchedByIgnition" SG_ 2527679659 FA_Niveau_Druck_VL 0;
BA_ "Fehlerwert" SG_ 2527679659 FA_Niveau_Druck_VL 255;
BA_ "GenSigSendType" SG_ 2527679659 FA_Niveau_Druck_VR 0;
BA_ "GenSigStartValue" SG_ 2527679659 FA_Niveau_Druck_VR 254;
BA_ "GenSigSwitchedByIgnition" SG_ 2527679659 FA_Niveau_Druck_VR 0;
BA_ "Fehlerwert" SG_ 2527679659 FA_Niveau_Druck_VR 255;
BA_ "GenSigSendType" SG_ 429 EFP_Soll_FahrPr_HAL 0;
BA_ "GenSigSwitchedByIgnition" SG_ 429 EFP_Soll_FahrPr_HAL 0;
BA_ "GenSigSendType" SG_ 429 FA_Absenkung_Fahrzeug 0;
BA_ "GenSigSwitchedByIgnition" SG_ 429 FA_Absenkung_Fahrzeug 0;
BA_ "GenSigSendType" SG_ 429 FA_Anhaengerstatus_intern 0;
BA_ "GenSigSwitchedByIgnition" SG_ 429 FA_Anhaengerstatus_intern 0;
BA_ "GenSigSendType" SG_ 429 FA_Anhebung_Fahrzeug 0;
BA_ "GenSigSwitchedByIgnition" SG_ 429 FA_Anhebung_Fahrzeug 0;
BA_ "GenSigSendType" SG_ 429 FA_Druckspeicher_verfuegbar 0;
BA_ "GenSigSwitchedByIgnition" SG_ 429 FA_Druckspeicher_verfuegbar 0;
BA_ "GenSigSendType" SG_ 429 FA_ESP_Zuschaltung 0;
BA_ "GenSigSendType" SG_ 429 FA_HAL_Abschaltung 0;
BA_ "GenSigSwitchedByIgnition" SG_ 429 FA_HAL_Abschaltung 0;
BA_ "GenSigSendType" SG_ 429 FA_Kompressor_laeuft 0;
BA_ "GenSigSwitchedByIgnition" SG_ 429 FA_Kompressor_laeuft 0;
BA_ "GenSigSendType" SG_ 429 FA_Kompressor_laeuft_in_Kuerze 0;
BA_ "GenSigSwitchedByIgnition" SG_ 429 FA_Kompressor_laeuft_in_Kuerze 0;
BA_ "GenSigSendType" SG_ 429 FA_Signal_Drucksensor 0;
BA_ "GenSigStartValue" SG_ 429 FA_Signal_Drucksensor 254;
BA_ "GenSigSwitchedByIgnition" SG_ 429 FA_Signal_Drucksensor 0;
BA_ "Fehlerwert" SG_ 429 FA_Signal_Drucksensor 255;
BA_ "GenSigSendType" SG_ 429 FA_Systemstatus 0;
BA_ "GenSigSwitchedByIgnition" SG_ 429 FA_Systemstatus 0;
BA_ "GenSigSendType" SG_ 429 FA_Verstellung_aktiv 0;
BA_ "GenSigSwitchedByIgnition" SG_ 429 FA_Verstellung_aktiv 0;
BA_ "GenSigSendType" SG_ 429 FA_Verstellung_in_Kuerze 0;
BA_ "GenSigSwitchedByIgnition" SG_ 429 FA_Verstellung_in_Kuerze 0;
BA_ "GenSigSendType" SG_ 429 FA_Zwischenniveau 0;
BA_ "GenSigSwitchedByIgnition" SG_ 429 FA_Zwischenniveau 0;
BA_ "GenSigSendType" SG_ 429 Fahrwerk_06_BZ 0;
BA_ "GenSigFuncType" SG_ 429 Fahrwerk_06_BZ 1;
BA_ "GenSigSwitchedByIgnition" SG_ 429 Fahrwerk_06_BZ 0;
BA_ "GenSigSendType" SG_ 429 Fahrwerk_06_CRC 0;
BA_ "GenSigFuncType" SG_ 429 Fahrwerk_06_CRC 2;
BA_ "GenSigSwitchedByIgnition" SG_ 429 Fahrwerk_06_CRC 0;
BA_ "GenSigSendType" SG_ 429 NR_Anforderung_v_Begrenzung 0;
BA_ "GenSigSwitchedByIgnition" SG_ 429 NR_Anforderung_v_Begrenzung 0;
BA_ "GenSigSendType" SG_ 429 NR_Kompressor_Strom_02 0;
BA_ "Fehlerwert" SG_ 429 NR_Kompressor_Strom_02 255;
BA_ "GenSigSendType" SG_ 429 NR_Kompressor_Temp_Zylinderkopf 0;
BA_ "GenSigStartValue" SG_ 429 NR_Kompressor_Temp_Zylinderkopf 254;
BA_ "Fehlerwert" SG_ 429 NR_Kompressor_Temp_Zylinderkopf 255;
BA_ "GenSigSendType" SG_ 429 NR_LED_BN 3;
BA_ "GenSigSwitchedByIgnition" SG_ 429 NR_LED_BN 0;
BA_ "GenSigSendType" SG_ 429 NR_LED_HN 3;
BA_ "GenSigSwitchedByIgnition" SG_ 429 NR_LED_HN 0;
BA_ "GenSigSendType" SG_ 429 NR_LED_SGN 3;
BA_ "GenSigSwitchedByIgnition" SG_ 429 NR_LED_SGN 0;
BA_ "GenSigSendType" SG_ 429 NR_LED_TN 3;
BA_ "GenSigSwitchedByIgnition" SG_ 429 NR_LED_TN 0;
BA_ "GenSigSendType" SG_ 429 NR_Reglerstatus 3;
BA_ "GenSigSwitchedByIgnition" SG_ 429 NR_Reglerstatus 0;
BA_ "GenSigSendType" SG_ 2527679658 EFP_ReifenTemp_HL 0;
BA_ "GenSigStartValue" SG_ 2527679658 EFP_ReifenTemp_HL 63;
BA_ "GenSigSwitchedByIgnition" SG_ 2527679658 EFP_ReifenTemp_HL 0;
BA_ "GenSigSendType" SG_ 2527679658 EFP_ReifenTemp_HR 0;
BA_ "GenSigStartValue" SG_ 2527679658 EFP_ReifenTemp_HR 63;
BA_ "GenSigSwitchedByIgnition" SG_ 2527679658 EFP_ReifenTemp_HR 0;
BA_ "GenSigSendType" SG_ 2527679658 EFP_ReifenTemp_VL 0;
BA_ "GenSigStartValue" SG_ 2527679658 EFP_ReifenTemp_VL 63;
BA_ "GenSigSwitchedByIgnition" SG_ 2527679658 EFP_ReifenTemp_VL 0;
BA_ "GenSigSendType" SG_ 2527679658 EFP_ReifenTemp_VR 0;
BA_ "GenSigStartValue" SG_ 2527679658 EFP_ReifenTemp_VR 63;
BA_ "GenSigSwitchedByIgnition" SG_ 2527679658 EFP_ReifenTemp_VR 0;
BA_ "GenSigSendType" SG_ 2527679658 FA_Beladung_HA 0;
BA_ "GenSigStartValue" SG_ 2527679658 FA_Beladung_HA 14;
BA_ "GenSigSwitchedByIgnition" SG_ 2527679658 FA_Beladung_HA 0;
BA_ "Fehlerwert" SG_ 2527679658 FA_Beladung_HA 15;
BA_ "GenSigSendType" SG_ 2527679658 FA_Beladung_VA 0;
BA_ "GenSigStartValue" SG_ 2527679658 FA_Beladung_VA 14;
BA_ "GenSigSwitchedByIgnition" SG_ 2527679658 FA_Beladung_VA 0;
BA_ "Fehlerwert" SG_ 2527679658 FA_Beladung_VA 15;
BA_ "GenSigSendType" SG_ 2527679658 FA_FahrerAnf_Fahrwerk 0;
BA_ "GenSigSwitchedByIgnition" SG_ 2527679658 FA_FahrerAnf_Fahrwerk 0;
BA_ "GenSigSendType" SG_ 2527679658 FA_FahrerAnf_Lift 0;
BA_ "GenSigSwitchedByIgnition" SG_ 2527679658 FA_FahrerAnf_Lift 0;
BA_ "GenSigSendType" SG_ 2527679658 FA_FahrerAnf_Niveau 0;
BA_ "GenSigSwitchedByIgnition" SG_ 2527679658 FA_FahrerAnf_Niveau 0;
BA_REL_ "GenSigTimeoutTime" BU_SG_REL_ BedienDisp_vo SG_ 1603 KBI_Einheit_Temp 5000;
BA_REL_ "GenSigTimeoutTime" BU_SG_REL_ BedienSG_hi SG_ 1603 KBI_Einheit_Datum 5000;
BA_REL_ "GenSigTimeoutTime" BU_SG_REL_ BedienSG_hi SG_ 1603 KBI_Einheit_Druck 5000;
BA_REL_ "GenSigTimeoutTime" BU_SG_REL_ BedienSG_hi SG_ 1603 KBI_Einheit_Streckenanz 5000;
BA_REL_ "GenSigTimeoutTime" BU_SG_REL_ BedienSG_hi SG_ 1603 KBI_Einheit_Temp 5000;
BA_REL_ "GenSigTimeoutTime" BU_SG_REL_ BedienSG_hi SG_ 1603 KBI_Einheit_Uhrzeit 5000;
BA_REL_ "GenSigTimeoutTime" BU_SG_REL_ BedienSG_hi SG_ 1603 KBI_Einheit_Verbrauch 5000;
BA_REL_ "GenSigTimeoutTime" BU_SG_REL_ BedienSG_hi SG_ 1603 KBI_Einheit_Volumen 5000;
BA_REL_ "GenSigTimeoutTime" BU_SG_REL_ BedienSG_hi SG_ 1603 KBI_Einheit_Sprache 5000;
BA_REL_ "GenSigTimeoutTime" BU_SG_REL_ BedienSG_hi SG_ 253 ESP_v_Signal 1000;
BA_REL_ "GenSigTimeoutTime" BU_SG_REL_ DDA SG_ 418 HMS_Systemstatus 5000;
BA_REL_ "GenSigTimeoutTime" BU_SG_REL_ DDA SG_ 253 ESP_v_Signal 1000;
BA_REL_ "GenSigTimeoutTime" BU_SG_REL_ DDA SG_ 264 FA_Hoehenwert_VL_00 2000;
BA_REL_ "GenSigTimeoutTime" BU_SG_REL_ DDA SG_ 264 FA_Hoehenwert_VR_00 2000;
BA_REL_ "GenSigTimeoutTime" BU_SG_REL_ DDA SG_ 264 FA_Hoehenwert_HL_00 2000;
BA_REL_ "GenSigTimeoutTime" BU_SG_REL_ DDA SG_ 264 FA_Hoehenwert_HR_00 2000;
BA_REL_ "GenSigTimeoutTime" BU_SG_REL_ OTA_FC SG_ 2527679980 bCall_active 5000;
BA_REL_ "GenSigTimeoutTime" BU_SG_REL_ OTA_FC SG_ 1603 KBI_Einheit_Datum 5000;
BA_REL_ "GenSigTimeoutTime" BU_SG_REL_ OTA_FC SG_ 1603 KBI_Einheit_Druck 5000;
BA_REL_ "GenSigTimeoutTime" BU_SG_REL_ OTA_FC SG_ 1603 KBI_Einheit_Streckenanz 5000;
BA_REL_ "GenSigTimeoutTime" BU_SG_REL_ OTA_FC SG_ 1603 KBI_MFA_v_Einheit_02 5000;
BA_REL_ "GenSigTimeoutTime" BU_SG_REL_ OTA_FC SG_ 1603 KBI_Einheit_Temp 5000;
BA_REL_ "GenSigTimeoutTime" BU_SG_REL_ OTA_FC SG_ 1603 KBI_Einheit_Uhrzeit 5000;
BA_REL_ "GenSigTimeoutTime" BU_SG_REL_ OTA_FC SG_ 1603 KBI_Einheit_Verbrauch 5000;
BA_REL_ "GenSigTimeoutTime" BU_SG_REL_ OTA_FC SG_ 1603 KBI_Einheit_Volumen 5000;
BA_REL_ "GenSigTimeoutTime" BU_SG_REL_ OTA_FC SG_ 1603 KBI_Einheit_Verbrauch_elektr 5000;
BA_REL_ "GenSigTimeoutTime" BU_SG_REL_ OTA_FC SG_ 1603 KBI_Einheit_Sprache 5000;
BA_REL_ "GenSigTimeoutTime" BU_SG_REL_ OTA_FC SG_ 1603 KBI_Einheit_Masse 5000;
BA_REL_ "GenSigTimeoutTime" BU_SG_REL_ OTA_FC SG_ 260 EPB_Schalterposition 5000;
BA_REL_ "GenSigTimeoutTime" BU_SG_REL_ OTA_FC SG_ 260 EPB_Status_02 5000;
BA_REL_ "GenSigTimeoutTime" BU_SG_REL_ OTA_FC SG_ 781 EPB_Autoholdlampe 2000;
BA_REL_ "GenSigTimeoutTime" BU_SG_REL_ OTA_FC SG_ 259 ESP_VL_FR 1000;
BA_REL_ "GenSigTimeoutTime" BU_SG_REL_ OTA_FC SG_ 259 ESP_VR_FR 1000;
BA_REL_ "GenSigTimeoutTime" BU_SG_REL_ OTA_FC SG_ 259 ESP_HL_FR 1000;
BA_REL_ "GenSigTimeoutTime" BU_SG_REL_ OTA_FC SG_ 259 ESP_HR_FR 1000;
BA_REL_ "GenSigTimeoutTime" BU_SG_REL_ OTA_FC SG_ 259 ESP_VL_Radgeschw 1000;
BA_REL_ "GenSigTimeoutTime" BU_SG_REL_ OTA_FC SG_ 259 ESP_VR_Radgeschw 1000;
BA_REL_ "GenSigTimeoutTime" BU_SG_REL_ OTA_FC SG_ 259 ESP_HL_Radgeschw 1000;
BA_REL_ "GenSigTimeoutTime" BU_SG_REL_ OTA_FC SG_ 259 ESP_HR_Radgeschw 1000;
BA_REL_ "GenSigTimeoutTime" BU_SG_REL_ OTA_FC SG_ 262 ESP_Bremsdruck 2000;
BA_REL_ "GenSigTimeoutTime" BU_SG_REL_ OTA_FC SG_ 262 ESC_Bremslicht 2000;
BA_REL_ "GenSigTimeoutTime" BU_SG_REL_ OTA_FC SG_ 278 ESP_VL_Fahrtrichtung 500;
BA_REL_ "GenSigTimeoutTime" BU_SG_REL_ OTA_FC SG_ 278 ESP_VR_Fahrtrichtung 500;
BA_REL_ "GenSigTimeoutTime" BU_SG_REL_ OTA_FC SG_ 278 ESP_HL_Fahrtrichtung 500;
BA_REL_ "GenSigTimeoutTime" BU_SG_REL_ OTA_FC SG_ 278 ESP_HR_Fahrtrichtung 500;
BA_REL_ "GenSigTimeoutTime" BU_SG_REL_ OTA_FC SG_ 253 ESP_v_Signal 1000;
BA_REL_ "GenSigTimeoutTime" BU_SG_REL_ OTA_FC SG_ 253 ASR_Tastung_passiv 1000;
BA_REL_ "GenSigTimeoutTime" BU_SG_REL_ OTA_FC SG_ 253 ESP_Tastung_passiv 1000;
BA_REL_ "GenSigTimeoutTime" BU_SG_REL_ OTA_FC SG_ 253 ESP_Systemstatus 1000;
BA_REL_ "GenSigTimeoutTime" BU_SG_REL_ OTA_FC SG_ 253 ABS_Bremsung 1000;
BA_REL_ "GenSigTimeoutTime" BU_SG_REL_ OTA_FC SG_ 253 MSR_Anf 1000;
BA_REL_ "GenSigTimeoutTime" BU_SG_REL_ OTA_FC SG_ 253 ESP_Eingriff 1000;
BA_REL_ "GenSigTimeoutTime" BU_SG_REL_ OTA_FC SG_ 239 ESP_VL_Bremsmoment 1000;
BA_REL_ "GenSigTimeoutTime" BU_SG_REL_ OTA_FC SG_ 239 ESP_VR_Bremsmoment 1000;
BA_REL_ "GenSigTimeoutTime" BU_SG_REL_ OTA_FC SG_ 239 ESP_HL_Bremsmoment 1000;
BA_REL_ "GenSigTimeoutTime" BU_SG_REL_ OTA_FC SG_ 239 ESP_HR_Bremsmoment 1000;
BA_REL_ "GenSigTimeoutTime" BU_SG_REL_ OTA_FC SG_ 239 ESP_FZR_uebersteuern 1000;
BA_REL_ "GenSigTimeoutTime" BU_SG_REL_ OTA_FC SG_ 239 ESP_FZR_untersteuern 1000;
BA_REL_ "GenSigTimeoutTime" BU_SG_REL_ OTA_FC SG_ 795 ESP_Lampe 500;
BA_REL_ "GenSigTimeoutTime" BU_SG_REL_ OTA_FC SG_ 795 ABS_Lampe 500;
BA_REL_ "GenSigTimeoutTime" BU_SG_REL_ OTA_FC SG_ 795 BK_Lampe_02 500;
BA_REL_ "GenSigTimeoutTime" BU_SG_REL_ OTA_FC SG_ 795 ESP_Textanzeigen_03 500;
BA_REL_ "GenSigTimeoutTime" BU_SG_REL_ OTA_FC SG_ 795 ESP_Off_Lampe 500;
BA_REL_ "GenSigTimeoutTime" BU_SG_REL_ OTA_FC SG_ 795 ESP_BKV_Warnung 500;
BA_REL_ "GenSigTimeoutTime" BU_SG_REL_ OTA_FC SG_ 508 ESP_HOLD_verf 2000;
BA_REL_ "GenSigTimeoutTime" BU_SG_REL_ OTA_FC SG_ 264 FA_Hoehenwert_VL_00 2000;
BA_REL_ "GenSigTimeoutTime" BU_SG_REL_ OTA_FC SG_ 264 FA_Hoehenwert_VR_00 2000;
BA_REL_ "GenSigTimeoutTime" BU_SG_REL_ OTA_FC SG_ 264 FA_Hoehenwert_HL_00 2000;
BA_REL_ "GenSigTimeoutTime" BU_SG_REL_ OTA_FC SG_ 264 FA_Hoehenwert_HR_00 2000;
BA_REL_ "GenSigTimeoutTime" BU_SG_REL_ OTA_FC SG_ 264 FA_Fahrbahnunebenheit 2000;
BA_REL_ "GenSigTimeoutTime" BU_SG_REL_ OTA_FC SG_ 2527679659 FA_Niveau_Druck_HL 3200;
BA_REL_ "GenSigTimeoutTime" BU_SG_REL_ OTA_FC SG_ 2527679659 FA_Niveau_Druck_HR 3200;
BA_REL_ "GenSigTimeoutTime" BU_SG_REL_ OTA_FC SG_ 2527679659 FA_Niveau_Druck_VL 3200;
BA_REL_ "GenSigTimeoutTime" BU_SG_REL_ OTA_FC SG_ 2527679659 FA_Niveau_Druck_VR 3200;
BA_REL_ "GenSigTimeoutTime" BU_SG_REL_ OTA_FC SG_ 429 NR_Reglerstatus 5000;
BA_REL_ "GenSigTimeoutTime" BU_SG_REL_ OTA_FC SG_ 429 FA_Kompressor_laeuft 5000;
BA_REL_ "GenSigTimeoutTime" BU_SG_REL_ OTA_FC SG_ 429 FA_Absenkung_Fahrzeug 5000;
BA_REL_ "GenSigTimeoutTime" BU_SG_REL_ OTA_FC SG_ 429 FA_Anhaengerstatus_intern 5000;
BA_REL_ "GenSigTimeoutTime" BU_SG_REL_ OTA_FC SG_ 429 FA_Anhebung_Fahrzeug 5000;
BA_REL_ "GenSigTimeoutTime" BU_SG_REL_ OTA_FC SG_ 429 FA_Druckspeicher_verfuegbar 5000;
BA_REL_ "GenSigTimeoutTime" BU_SG_REL_ OTA_FC SG_ 429 FA_HAL_Abschaltung 5000;
BA_REL_ "GenSigTimeoutTime" BU_SG_REL_ OTA_FC SG_ 429 FA_ESP_Zuschaltung 5000;
BA_REL_ "GenSigTimeoutTime" BU_SG_REL_ OTA_FC SG_ 429 NR_LED_HN 5000;
BA_REL_ "GenSigTimeoutTime" BU_SG_REL_ OTA_FC SG_ 429 FA_Zwischenniveau 5000;
BA_REL_ "GenSigTimeoutTime" BU_SG_REL_ OTA_FC SG_ 429 NR_Kompressor_Strom_02 5000;
BA_REL_ "GenSigTimeoutTime" BU_SG_REL_ OTA_FC SG_ 429 NR_Kompressor_Temp_Zylinderkopf 5000;
BA_REL_ "GenSigTimeoutTime" BU_SG_REL_ OTA_FC SG_ 429 FA_Signal_Drucksensor 5000;
BA_REL_ "GenSigTimeoutTime" BU_SG_REL_ OTA_FC SG_ 2527679658 FA_FahrerAnf_Fahrwerk 3200;
BA_REL_ "GenSigTimeoutTime" BU_SG_REL_ OTA_FC SG_ 2527679658 FA_FahrerAnf_Lift 3200;
BA_REL_ "GenSigTimeoutTime" BU_SG_REL_ OTA_FC SG_ 2527679658 FA_FahrerAnf_Niveau 3200;
BA_REL_ "GenSigTimeoutTime" BU_SG_REL_ OTA_FC SG_ 2527679658 EFP_ReifenTemp_HL 3200;
BA_REL_ "GenSigTimeoutTime" BU_SG_REL_ OTA_FC SG_ 2527679658 EFP_ReifenTemp_HR 3200;
BA_REL_ "GenSigTimeoutTime" BU_SG_REL_ OTA_FC SG_ 2527679658 EFP_ReifenTemp_VL 3200;
BA_REL_ "GenSigTimeoutTime" BU_SG_REL_ OTA_FC SG_ 2527679658 EFP_ReifenTemp_VR 3200;
BA_REL_ "GenSigTimeoutTime" BU_SG_REL_ ZR_High SG_ 496 EA_Texte 500;
BA_REL_ "GenSigTimeoutTime" BU_SG_REL_ ZR_High SG_ 496 EA_Infotainment_Anf 500;
BA_REL_ "GenSigTimeoutTime" BU_SG_REL_ ZR_High SG_ 496 EA_Tueren_Anf 500;
BA_REL_ "GenSigTimeoutTime" BU_SG_REL_ ZR_High SG_ 496 EA_Innenraumlicht_Anf 500;
BA_REL_ "GenSigTimeoutTime" BU_SG_REL_ ZR_High SG_ 496 zFAS_Warnblinken 500;
BA_REL_ "GenSigTimeoutTime" BU_SG_REL_ ZR_High SG_ 2527679980 eCall_Statuslicht_Farbe2 5000;
BA_REL_ "GenSigTimeoutTime" BU_SG_REL_ ZR_High SG_ 2527679980 eCall_Statuslicht_Farbe1 5000;
BA_REL_ "GenSigTimeoutTime" BU_SG_REL_ ZR_High SG_ 2527679980 bCall_active 5000;
BA_REL_ "GenSigTimeoutTime" BU_SG_REL_ ZR_High SG_ 2527679980 eCall_Funktionsstatus 5000;
BA_REL_ "GenSigTimeoutTime" BU_SG_REL_ ZR_High SG_ 2527679980 eCall_Funktionsstatus_02 5000;
BA_REL_ "GenSigTimeoutTime" BU_SG_REL_ ZR_High SG_ 996 EFF_Verbrauch_STH 5000;
BA_REL_ "GenSigTimeoutTime" BU_SG_REL_ ZR_High SG_ 996 MKE_Texte 5000;
BA_REL_ "GenSigTimeoutTime" BU_SG_REL_ ZR_High SG_ 996 MKE_FAS 5000;
BA_REL_ "GenSigTimeoutTime" BU_SG_REL_ ZR_High SG_ 996 MKE_Stufe 5000;
BA_REL_ "GenSigTimeoutTime" BU_SG_REL_ ZR_High SG_ 996 MKE_FAS_Fkt_Status 5000;
BA_REL_ "GenSigTimeoutTime" BU_SG_REL_ ZR_High SG_ 1603 KBI_Einheit_Datum 5000;
BA_REL_ "GenSigTimeoutTime" BU_SG_REL_ ZR_High SG_ 1603 KBI_Einheit_Druck 5000;
BA_REL_ "GenSigTimeoutTime" BU_SG_REL_ ZR_High SG_ 1603 KBI_Einheit_Streckenanz 5000;
BA_REL_ "GenSigTimeoutTime" BU_SG_REL_ ZR_High SG_ 1603 KBI_MFA_v_Einheit_02 5000;
BA_REL_ "GenSigTimeoutTime" BU_SG_REL_ ZR_High SG_ 1603 KBI_Einheit_Temp 5000;
BA_REL_ "GenSigTimeoutTime" BU_SG_REL_ ZR_High SG_ 1603 KBI_Einheit_Uhrzeit 5000;
BA_REL_ "GenSigTimeoutTime" BU_SG_REL_ ZR_High SG_ 1603 KBI_Einheit_Verbrauch 5000;
BA_REL_ "GenSigTimeoutTime" BU_SG_REL_ ZR_High SG_ 1603 KBI_Einheit_Volumen 5000;
BA_REL_ "GenSigTimeoutTime" BU_SG_REL_ ZR_High SG_ 1603 KBI_Einheit_Sprache 5000;
BA_REL_ "GenSigTimeoutTime" BU_SG_REL_ ZR_High SG_ 1622 ELV_Verriegelt 5000;
BA_REL_ "GenSigTimeoutTime" BU_SG_REL_ ZR_High SG_ 1622 ELV_Entriegelt 5000;
BA_REL_ "GenSigTimeoutTime" BU_SG_REL_ ZR_High SG_ 1622 ELV_LED_Rot 5000;
BA_REL_ "GenSigTimeoutTime" BU_SG_REL_ ZR_High SG_ 1622 ELV_Txt_Lkg_Bewegen 5000;
BA_REL_ "GenSigTimeoutTime" BU_SG_REL_ ZR_High SG_ 1622 ELV_Txt_Werkstatt 5000;
BA_REL_ "GenSigTimeoutTime" BU_SG_REL_ ZR_High SG_ 1622 ELV_Txt_Defekt 5000;
BA_REL_ "GenSigTimeoutTime" BU_SG_REL_ ZR_High SG_ 260 EPB_Status_02 5000;
BA_REL_ "GenSigTimeoutTime" BU_SG_REL_ ZR_High SG_ 781 EPB_Funktionslampe 2000;
BA_REL_ "GenSigTimeoutTime" BU_SG_REL_ ZR_High SG_ 781 EPB_Texte 2000;
BA_REL_ "GenSigTimeoutTime" BU_SG_REL_ ZR_High SG_ 781 EPB_Autoholdlampe 2000;
BA_REL_ "GenSigTimeoutTime" BU_SG_REL_ ZR_High SG_ 781 EPB_Fehlermeldungen 2000;
BA_REL_ "GenSigTimeoutTime" BU_SG_REL_ ZR_High SG_ 259 ESP_VL_Radgeschw 1000;
BA_REL_ "GenSigTimeoutTime" BU_SG_REL_ ZR_High SG_ 259 ESP_VR_Radgeschw 1000;
BA_REL_ "GenSigTimeoutTime" BU_SG_REL_ ZR_High SG_ 259 ESP_HL_Radgeschw 1000;
BA_REL_ "GenSigTimeoutTime" BU_SG_REL_ ZR_High SG_ 259 ESP_HR_Radgeschw 1000;
BA_REL_ "GenSigTimeoutTime" BU_SG_REL_ ZR_High SG_ 262 ESP_QBit_Bremsdruck 2000;
BA_REL_ "GenSigTimeoutTime" BU_SG_REL_ ZR_High SG_ 262 ESP_Bremsdruck 2000;
BA_REL_ "GenSigTimeoutTime" BU_SG_REL_ ZR_High SG_ 262 ESP_Lenkeingriff_ADS 2000;
BA_REL_ "GenSigTimeoutTime" BU_SG_REL_ ZR_High SG_ 262 ESP_Status_Anfahrhilfe 2000;
BA_REL_ "GenSigTimeoutTime" BU_SG_REL_ ZR_High SG_ 262 ESP_HDC_aktiv 2000;
BA_REL_ "GenSigTimeoutTime" BU_SG_REL_ ZR_High SG_ 262 ESP_Eingr_HL 2000;
BA_REL_ "GenSigTimeoutTime" BU_SG_REL_ ZR_High SG_ 262 ESP_Eingr_HR 2000;
BA_REL_ "GenSigTimeoutTime" BU_SG_REL_ ZR_High SG_ 262 ESP_Eingr_VL 2000;
BA_REL_ "GenSigTimeoutTime" BU_SG_REL_ ZR_High SG_ 262 ESP_Eingr_VR 2000;
BA_REL_ "GenSigTimeoutTime" BU_SG_REL_ ZR_High SG_ 262 ESP_Autohold_aktiv 2000;
BA_REL_ "GenSigTimeoutTime" BU_SG_REL_ ZR_High SG_ 914 ESP_Rollenmodus_Deaktivieren 5000;
BA_REL_ "GenSigTimeoutTime" BU_SG_REL_ ZR_High SG_ 278 ESP_QBit_Wegimpuls_VL 500;
BA_REL_ "GenSigTimeoutTime" BU_SG_REL_ ZR_High SG_ 278 ESP_QBit_Wegimpuls_VR 500;
BA_REL_ "GenSigTimeoutTime" BU_SG_REL_ ZR_High SG_ 278 ESP_QBit_Wegimpuls_HL 500;
BA_REL_ "GenSigTimeoutTime" BU_SG_REL_ ZR_High SG_ 278 ESP_QBit_Wegimpuls_HR 500;
BA_REL_ "GenSigTimeoutTime" BU_SG_REL_ ZR_High SG_ 278 ESP_Wegimpuls_VL 500;
BA_REL_ "GenSigTimeoutTime" BU_SG_REL_ ZR_High SG_ 278 ESP_Wegimpuls_VR 500;
BA_REL_ "GenSigTimeoutTime" BU_SG_REL_ ZR_High SG_ 278 ESP_Wegimpuls_HL 500;
BA_REL_ "GenSigTimeoutTime" BU_SG_REL_ ZR_High SG_ 278 ESP_Wegimpuls_HR 500;
BA_REL_ "GenSigTimeoutTime" BU_SG_REL_ ZR_High SG_ 278 ESP_VL_Fahrtrichtung 500;
BA_REL_ "GenSigTimeoutTime" BU_SG_REL_ ZR_High SG_ 278 ESP_VR_Fahrtrichtung 500;
BA_REL_ "GenSigTimeoutTime" BU_SG_REL_ ZR_High SG_ 278 ESP_HL_Fahrtrichtung 500;
BA_REL_ "GenSigTimeoutTime" BU_SG_REL_ ZR_High SG_ 278 ESP_HR_Fahrtrichtung 500;
BA_REL_ "GenSigTimeoutTime" BU_SG_REL_ ZR_High SG_ 418 HMS_Systemstatus 5000;
BA_REL_ "GenSigTimeoutTime" BU_SG_REL_ ZR_High SG_ 1629 ESP_Zaehnezahl 1600;
BA_REL_ "GenSigTimeoutTime" BU_SG_REL_ ZR_High SG_ 1629 ESP_Wiederstart_Anz_01 1600;
BA_REL_ "GenSigTimeoutTime" BU_SG_REL_ ZR_High SG_ 1629 ESP_Wiederstart_Anz_04 1600;
BA_REL_ "GenSigTimeoutTime" BU_SG_REL_ ZR_High SG_ 1629 ESP_Stoppverbot_Anz_01 1600;
BA_REL_ "GenSigTimeoutTime" BU_SG_REL_ ZR_High SG_ 1629 ESP_Stoppverbot_Anz_05 1600;
BA_REL_ "GenSigTimeoutTime" BU_SG_REL_ ZR_High SG_ 1629 ESP_Stoppverbot_Anz_06 1600;
BA_REL_ "GenSigTimeoutTime" BU_SG_REL_ ZR_High SG_ 1629 ESP_Dachrelingsensor 1600;
BA_REL_ "GenSigTimeoutTime" BU_SG_REL_ ZR_High SG_ 1629 BR_QBit_Reifenumfang 1600;
BA_REL_ "GenSigTimeoutTime" BU_SG_REL_ ZR_High SG_ 1629 BR_Reifenumfang 1600;
BA_REL_ "GenSigTimeoutTime" BU_SG_REL_ ZR_High SG_ 253 ESP_Diagnose 1000;
BA_REL_ "GenSigTimeoutTime" BU_SG_REL_ ZR_High SG_ 253 OBD_Schlechtweg 1000;
BA_REL_ "GenSigTimeoutTime" BU_SG_REL_ ZR_High SG_ 253 OBD_QBit_Schlechtweg 1000;
BA_REL_ "GenSigTimeoutTime" BU_SG_REL_ ZR_High SG_ 253 ESP_v_Signal 1000;
BA_REL_ "GenSigTimeoutTime" BU_SG_REL_ ZR_High SG_ 253 ESP_Tastung_passiv 1000;
BA_REL_ "GenSigTimeoutTime" BU_SG_REL_ ZR_High SG_ 253 ESP_QBit_v_Signal 1000;
BA_REL_ "GenSigTimeoutTime" BU_SG_REL_ ZR_High SG_ 253 ABS_Bremsung 1000;
BA_REL_ "GenSigTimeoutTime" BU_SG_REL_ ZR_High SG_ 253 ASR_Anf 1000;
BA_REL_ "GenSigTimeoutTime" BU_SG_REL_ ZR_High SG_ 253 MSR_Anf 1000;
BA_REL_ "GenSigTimeoutTime" BU_SG_REL_ ZR_High SG_ 253 ESP_Eingriff 1000;
BA_REL_ "GenSigTimeoutTime" BU_SG_REL_ ZR_High SG_ 253 ESP_ASP 1000;
BA_REL_ "GenSigTimeoutTime" BU_SG_REL_ ZR_High SG_ 239 ESP_FZR_uebersteuern 1000;
BA_REL_ "GenSigTimeoutTime" BU_SG_REL_ ZR_High SG_ 239 ESP_FZR_untersteuern 1000;
BA_REL_ "GenSigTimeoutTime" BU_SG_REL_ ZR_High SG_ 1470 ESP_Status_Bremsentemp_Anz 3200;
BA_REL_ "GenSigTimeoutTime" BU_SG_REL_ ZR_High SG_ 1470 ESP_Querbeschleunigung_Offset 3200;
BA_REL_ "GenSigTimeoutTime" BU_SG_REL_ ZR_High SG_ 1470 ESP_Laengsbeschleunigung_Offset 3200;
BA_REL_ "GenSigTimeoutTime" BU_SG_REL_ ZR_High SG_ 795 ESP_Lampe 500;
BA_REL_ "GenSigTimeoutTime" BU_SG_REL_ ZR_High SG_ 795 ABS_Lampe 500;
BA_REL_ "GenSigTimeoutTime" BU_SG_REL_ ZR_High SG_ 795 ESP_Wegimp_VA 500;
BA_REL_ "GenSigTimeoutTime" BU_SG_REL_ ZR_High SG_ 795 ESP_Fehlerstatus_Wegimp 500;
BA_REL_ "GenSigTimeoutTime" BU_SG_REL_ ZR_High SG_ 795 ESP_Wegimp_Ueberlauf 500;
BA_REL_ "GenSigTimeoutTime" BU_SG_REL_ ZR_High SG_ 795 ESP_QBit_Wegimp_VA 500;
BA_REL_ "GenSigTimeoutTime" BU_SG_REL_ ZR_High SG_ 795 ESP_HDC_Geschw_Farbe 500;
BA_REL_ "GenSigTimeoutTime" BU_SG_REL_ ZR_High SG_ 795 ESP_Off_Lampe 500;
BA_REL_ "GenSigTimeoutTime" BU_SG_REL_ ZR_High SG_ 795 ESP_HDC_Regelgeschw 500;
BA_REL_ "GenSigTimeoutTime" BU_SG_REL_ ZR_High SG_ 508 ESP_EDS_Anzeige 2000;
BA_REL_ "GenSigTimeoutTime" BU_SG_REL_ ZR_High SG_ 264 FA_Hoehenwerte_kalibriert 2000;
BA_REL_ "GenSigTimeoutTime" BU_SG_REL_ ZR_High SG_ 264 FA_Hoehenwert_VL_00 2000;
BA_REL_ "GenSigTimeoutTime" BU_SG_REL_ ZR_High SG_ 264 FA_Hoehenwert_VR_00 2000;
BA_REL_ "GenSigTimeoutTime" BU_SG_REL_ ZR_High SG_ 264 FA_Hoehenwert_HL_00 2000;
BA_REL_ "GenSigTimeoutTime" BU_SG_REL_ ZR_High SG_ 264 FA_Hoehenwert_HR_00 2000;
BA_REL_ "GenSigTimeoutTime" BU_SG_REL_ ZR_High SG_ 264 FA_Fahrbahnunebenheit 2000;
BA_REL_ "GenSigTimeoutTime" BU_SG_REL_ ZR_High SG_ 2527679659 FA_Niveau_Druck_HL 3200;
BA_REL_ "GenSigTimeoutTime" BU_SG_REL_ ZR_High SG_ 2527679659 FA_Niveau_Druck_HR 3200;
BA_REL_ "GenSigTimeoutTime" BU_SG_REL_ ZR_High SG_ 2527679659 FA_Niveau_Druck_VL 3200;
BA_REL_ "GenSigTimeoutTime" BU_SG_REL_ ZR_High SG_ 2527679659 FA_Niveau_Druck_VR 3200;
BA_REL_ "GenSigTimeoutTime" BU_SG_REL_ ZR_High SG_ 429 NR_Reglerstatus 5000;
BA_REL_ "GenSigTimeoutTime" BU_SG_REL_ ZR_High SG_ 429 FA_Verstellung_in_Kuerze 5000;
BA_REL_ "GenSigTimeoutTime" BU_SG_REL_ ZR_High SG_ 429 FA_Verstellung_aktiv 5000;
BA_REL_ "GenSigTimeoutTime" BU_SG_REL_ ZR_High SG_ 429 NR_LED_SGN 5000;
BA_REL_ "GenSigTimeoutTime" BU_SG_REL_ ZR_High SG_ 429 NR_LED_TN 5000;
BA_REL_ "GenSigTimeoutTime" BU_SG_REL_ ZR_High SG_ 429 NR_LED_BN 5000;
BA_REL_ "GenSigTimeoutTime" BU_SG_REL_ ZR_High SG_ 429 FA_Absenkung_Fahrzeug 5000;
BA_REL_ "GenSigTimeoutTime" BU_SG_REL_ ZR_High SG_ 429 FA_Anhaengerstatus_intern 5000;
BA_REL_ "GenSigTimeoutTime" BU_SG_REL_ ZR_High SG_ 429 FA_Anhebung_Fahrzeug 5000;
BA_REL_ "GenSigTimeoutTime" BU_SG_REL_ ZR_High SG_ 429 NR_LED_HN 5000;
BA_REL_ "GenSigTimeoutTime" BU_SG_REL_ ZR_High SG_ 429 FA_Systemstatus 5000;
BA_REL_ "GenSigTimeoutTime" BU_SG_REL_ ZR_High SG_ 2527679658 FA_Beladung_HA 3200;
BA_REL_ "GenSigTimeoutTime" BU_SG_REL_ ZR_High SG_ 2527679658 FA_Beladung_VA 3200;
BA_REL_ "GenSigTimeoutTime" BU_SG_REL_ ZR_LIMU SG_ 496 EA_Infotainment_Anf 500;
BA_REL_ "GenSigTimeoutTime" BU_SG_REL_ ZR_LIMU SG_ 260 EPB_Status_02 5000;
BA_REL_ "GenSigTimeoutTime" BU_SG_REL_ ZR_LIMU SG_ 259 ESP_VL_Radgeschw 1000;
BA_REL_ "GenSigTimeoutTime" BU_SG_REL_ ZR_LIMU SG_ 259 ESP_VR_Radgeschw 1000;
BA_REL_ "GenSigTimeoutTime" BU_SG_REL_ ZR_LIMU SG_ 259 ESP_HL_Radgeschw 1000;
BA_REL_ "GenSigTimeoutTime" BU_SG_REL_ ZR_LIMU SG_ 259 ESP_HR_Radgeschw 1000;
BA_REL_ "GenSigTimeoutTime" BU_SG_REL_ ZR_LIMU SG_ 262 ESP_QBit_Bremsdruck 2000;
BA_REL_ "GenSigTimeoutTime" BU_SG_REL_ ZR_LIMU SG_ 262 ESP_Bremsdruck 2000;
BA_REL_ "GenSigTimeoutTime" BU_SG_REL_ ZR_LIMU SG_ 262 ESP_Eingr_HL 2000;
BA_REL_ "GenSigTimeoutTime" BU_SG_REL_ ZR_LIMU SG_ 262 ESP_Eingr_HR 2000;
BA_REL_ "GenSigTimeoutTime" BU_SG_REL_ ZR_LIMU SG_ 262 ESP_Eingr_VL 2000;
BA_REL_ "GenSigTimeoutTime" BU_SG_REL_ ZR_LIMU SG_ 262 ESP_Eingr_VR 2000;
BA_REL_ "GenSigTimeoutTime" BU_SG_REL_ ZR_LIMU SG_ 914 ESP_Rollenmodus_Deaktivieren 5000;
BA_REL_ "GenSigTimeoutTime" BU_SG_REL_ ZR_LIMU SG_ 278 ESP_QBit_Wegimpuls_VL 500;
BA_REL_ "GenSigTimeoutTime" BU_SG_REL_ ZR_LIMU SG_ 278 ESP_QBit_Wegimpuls_VR 500;
BA_REL_ "GenSigTimeoutTime" BU_SG_REL_ ZR_LIMU SG_ 278 ESP_QBit_Wegimpuls_HL 500;
BA_REL_ "GenSigTimeoutTime" BU_SG_REL_ ZR_LIMU SG_ 278 ESP_QBit_Wegimpuls_HR 500;
BA_REL_ "GenSigTimeoutTime" BU_SG_REL_ ZR_LIMU SG_ 278 ESP_Wegimpuls_VL 500;
BA_REL_ "GenSigTimeoutTime" BU_SG_REL_ ZR_LIMU SG_ 278 ESP_Wegimpuls_VR 500;
BA_REL_ "GenSigTimeoutTime" BU_SG_REL_ ZR_LIMU SG_ 278 ESP_Wegimpuls_HL 500;
BA_REL_ "GenSigTimeoutTime" BU_SG_REL_ ZR_LIMU SG_ 278 ESP_Wegimpuls_HR 500;
BA_REL_ "GenSigTimeoutTime" BU_SG_REL_ ZR_LIMU SG_ 278 ESP_VL_Fahrtrichtung 500;
BA_REL_ "GenSigTimeoutTime" BU_SG_REL_ ZR_LIMU SG_ 278 ESP_VR_Fahrtrichtung 500;
BA_REL_ "GenSigTimeoutTime" BU_SG_REL_ ZR_LIMU SG_ 278 ESP_HL_Fahrtrichtung 500;
BA_REL_ "GenSigTimeoutTime" BU_SG_REL_ ZR_LIMU SG_ 278 ESP_HR_Fahrtrichtung 500;
BA_REL_ "GenSigTimeoutTime" BU_SG_REL_ ZR_LIMU SG_ 1629 ESP_Zaehnezahl 1600;
BA_REL_ "GenSigTimeoutTime" BU_SG_REL_ ZR_LIMU SG_ 253 ESP_v_Signal 1000;
BA_REL_ "GenSigTimeoutTime" BU_SG_REL_ ZR_LIMU SG_ 253 ESP_Tastung_passiv 1000;
BA_REL_ "GenSigTimeoutTime" BU_SG_REL_ ZR_LIMU SG_ 253 ESP_QBit_v_Signal 1000;
BA_REL_ "GenSigTimeoutTime" BU_SG_REL_ ZR_LIMU SG_ 253 ABS_Bremsung 1000;
BA_REL_ "GenSigTimeoutTime" BU_SG_REL_ ZR_LIMU SG_ 239 ESP_FZR_uebersteuern 1000;
BA_REL_ "GenSigTimeoutTime" BU_SG_REL_ ZR_LIMU SG_ 239 ESP_FZR_untersteuern 1000;
BA_REL_ "GenSigTimeoutTime" BU_SG_REL_ ZR_LIMU SG_ 1470 ESP_Status_Bremsentemp_Anz 3200;
BA_REL_ "GenSigTimeoutTime" BU_SG_REL_ ZR_LIMU SG_ 795 ESP_Lampe 500;
BA_REL_ "GenSigTimeoutTime" BU_SG_REL_ ZR_LIMU SG_ 795 ESP_Wegimp_VA 500;
BA_REL_ "GenSigTimeoutTime" BU_SG_REL_ ZR_LIMU SG_ 795 ESP_Fehlerstatus_Wegimp 500;
BA_REL_ "GenSigTimeoutTime" BU_SG_REL_ ZR_LIMU SG_ 795 ESP_Wegimp_Ueberlauf 500;
BA_REL_ "GenSigTimeoutTime" BU_SG_REL_ ZR_LIMU SG_ 795 ESP_QBit_Wegimp_VA 500;
BA_REL_ "GenSigTimeoutTime" BU_SG_REL_ ZR_LIMU SG_ 795 ESP_HDC_Geschw_Farbe 500;
BA_REL_ "GenSigTimeoutTime" BU_SG_REL_ ZR_LIMU SG_ 795 ESP_HDC_Regelgeschw 500;
BA_REL_ "GenSigTimeoutTime" BU_SG_REL_ ZR_LIMU SG_ 508 ESP_Status_Bremsentemp_02 2000;
BA_REL_ "GenSigTimeoutTime" BU_SG_REL_ ZR_LIMU SG_ 508 ESP_EDS_Anzeige 2000;
BA_REL_ "GenSigTimeoutTime" BU_SG_REL_ ZR_LIMU SG_ 600 ESP_54_CRC 4000;
BA_REL_ "GenSigTimeoutTime" BU_SG_REL_ ZR_LIMU SG_ 600 ESP_54_BZ 4000;
BA_REL_ "GenSigTimeoutTime" BU_SG_REL_ ZR_LIMU SG_ 600 ESP_Slider_Text 4000;
BA_REL_ "GenSigTimeoutTime" BU_SG_REL_ ZR_LIMU SG_ 600 ESP_Slider_Status 4000;
BA_REL_ "GenSigTimeoutTime" BU_SG_REL_ ZR_LIMU SG_ 600 ESP_Slider_ist_01 4000;
BA_REL_ "GenSigTimeoutTime" BU_SG_REL_ ZR_LIMU SG_ 600 ESP_Slider_ist_02 4000;
BA_REL_ "GenSigTimeoutTime" BU_SG_REL_ ZR_LIMU SG_ 600 ESP_Slider_ist_03 4000;
BA_REL_ "GenSigTimeoutTime" BU_SG_REL_ ZR_MIB_TOP_ab_Gen3 SG_ 496 EA_Infotainment_Anf 500;
BA_REL_ "GenSigTimeoutTime" BU_SG_REL_ ZR_MIB_TOP_ab_Gen3 SG_ 260 EPB_Status_02 5000;
BA_REL_ "GenSigTimeoutTime" BU_SG_REL_ ZR_MIB_TOP_ab_Gen3 SG_ 259 ESP_VL_Radgeschw 1000;
BA_REL_ "GenSigTimeoutTime" BU_SG_REL_ ZR_MIB_TOP_ab_Gen3 SG_ 259 ESP_VR_Radgeschw 1000;
BA_REL_ "GenSigTimeoutTime" BU_SG_REL_ ZR_MIB_TOP_ab_Gen3 SG_ 259 ESP_HL_Radgeschw 1000;
BA_REL_ "GenSigTimeoutTime" BU_SG_REL_ ZR_MIB_TOP_ab_Gen3 SG_ 259 ESP_HR_Radgeschw 1000;
BA_REL_ "GenSigTimeoutTime" BU_SG_REL_ ZR_MIB_TOP_ab_Gen3 SG_ 262 ESP_QBit_Bremsdruck 2000;
BA_REL_ "GenSigTimeoutTime" BU_SG_REL_ ZR_MIB_TOP_ab_Gen3 SG_ 262 ESP_Bremsdruck 2000;
BA_REL_ "GenSigTimeoutTime" BU_SG_REL_ ZR_MIB_TOP_ab_Gen3 SG_ 262 ESP_Eingr_HL 2000;
BA_REL_ "GenSigTimeoutTime" BU_SG_REL_ ZR_MIB_TOP_ab_Gen3 SG_ 262 ESP_Eingr_HR 2000;
BA_REL_ "GenSigTimeoutTime" BU_SG_REL_ ZR_MIB_TOP_ab_Gen3 SG_ 262 ESP_Eingr_VL 2000;
BA_REL_ "GenSigTimeoutTime" BU_SG_REL_ ZR_MIB_TOP_ab_Gen3 SG_ 262 ESP_Eingr_VR 2000;
BA_REL_ "GenSigTimeoutTime" BU_SG_REL_ ZR_MIB_TOP_ab_Gen3 SG_ 914 ESP_Rollenmodus_Deaktivieren 5000;
BA_REL_ "GenSigTimeoutTime" BU_SG_REL_ ZR_MIB_TOP_ab_Gen3 SG_ 278 ESP_QBit_Wegimpuls_VL 500;
BA_REL_ "GenSigTimeoutTime" BU_SG_REL_ ZR_MIB_TOP_ab_Gen3 SG_ 278 ESP_QBit_Wegimpuls_VR 500;
BA_REL_ "GenSigTimeoutTime" BU_SG_REL_ ZR_MIB_TOP_ab_Gen3 SG_ 278 ESP_QBit_Wegimpuls_HL 500;
BA_REL_ "GenSigTimeoutTime" BU_SG_REL_ ZR_MIB_TOP_ab_Gen3 SG_ 278 ESP_QBit_Wegimpuls_HR 500;
BA_REL_ "GenSigTimeoutTime" BU_SG_REL_ ZR_MIB_TOP_ab_Gen3 SG_ 278 ESP_Wegimpuls_VL 500;
BA_REL_ "GenSigTimeoutTime" BU_SG_REL_ ZR_MIB_TOP_ab_Gen3 SG_ 278 ESP_Wegimpuls_VR 500;
BA_REL_ "GenSigTimeoutTime" BU_SG_REL_ ZR_MIB_TOP_ab_Gen3 SG_ 278 ESP_Wegimpuls_HL 500;
BA_REL_ "GenSigTimeoutTime" BU_SG_REL_ ZR_MIB_TOP_ab_Gen3 SG_ 278 ESP_Wegimpuls_HR 500;
BA_REL_ "GenSigTimeoutTime" BU_SG_REL_ ZR_MIB_TOP_ab_Gen3 SG_ 278 ESP_VL_Fahrtrichtung 500;
BA_REL_ "GenSigTimeoutTime" BU_SG_REL_ ZR_MIB_TOP_ab_Gen3 SG_ 278 ESP_VR_Fahrtrichtung 500;
BA_REL_ "GenSigTimeoutTime" BU_SG_REL_ ZR_MIB_TOP_ab_Gen3 SG_ 278 ESP_HL_Fahrtrichtung 500;
BA_REL_ "GenSigTimeoutTime" BU_SG_REL_ ZR_MIB_TOP_ab_Gen3 SG_ 278 ESP_HR_Fahrtrichtung 500;
BA_REL_ "GenSigTimeoutTime" BU_SG_REL_ ZR_MIB_TOP_ab_Gen3 SG_ 1629 ESP_Zaehnezahl 1600;
BA_REL_ "GenSigTimeoutTime" BU_SG_REL_ ZR_MIB_TOP_ab_Gen3 SG_ 253 ESP_v_Signal 1000;
BA_REL_ "GenSigTimeoutTime" BU_SG_REL_ ZR_MIB_TOP_ab_Gen3 SG_ 253 ESP_Tastung_passiv 1000;
BA_REL_ "GenSigTimeoutTime" BU_SG_REL_ ZR_MIB_TOP_ab_Gen3 SG_ 253 ESP_QBit_v_Signal 1000;
BA_REL_ "GenSigTimeoutTime" BU_SG_REL_ ZR_MIB_TOP_ab_Gen3 SG_ 253 ABS_Bremsung 1000;
BA_REL_ "GenSigTimeoutTime" BU_SG_REL_ ZR_MIB_TOP_ab_Gen3 SG_ 239 ESP_FZR_uebersteuern 1000;
BA_REL_ "GenSigTimeoutTime" BU_SG_REL_ ZR_MIB_TOP_ab_Gen3 SG_ 239 ESP_FZR_untersteuern 1000;
BA_REL_ "GenSigTimeoutTime" BU_SG_REL_ ZR_MIB_TOP_ab_Gen3 SG_ 1470 ESP_Status_Bremsentemp_Anz 3200;
BA_REL_ "GenSigTimeoutTime" BU_SG_REL_ ZR_MIB_TOP_ab_Gen3 SG_ 795 ESP_Lampe 500;
BA_REL_ "GenSigTimeoutTime" BU_SG_REL_ ZR_MIB_TOP_ab_Gen3 SG_ 795 ESP_Wegimp_VA 500;
BA_REL_ "GenSigTimeoutTime" BU_SG_REL_ ZR_MIB_TOP_ab_Gen3 SG_ 795 ESP_Fehlerstatus_Wegimp 500;
BA_REL_ "GenSigTimeoutTime" BU_SG_REL_ ZR_MIB_TOP_ab_Gen3 SG_ 795 ESP_Wegimp_Ueberlauf 500;
BA_REL_ "GenSigTimeoutTime" BU_SG_REL_ ZR_MIB_TOP_ab_Gen3 SG_ 795 ESP_QBit_Wegimp_VA 500;
BA_REL_ "GenSigTimeoutTime" BU_SG_REL_ ZR_MIB_TOP_ab_Gen3 SG_ 795 ESP_HDC_Geschw_Farbe 500;
BA_REL_ "GenSigTimeoutTime" BU_SG_REL_ ZR_MIB_TOP_ab_Gen3 SG_ 795 ESP_HDC_Regelgeschw 500;
BA_REL_ "GenSigTimeoutTime" BU_SG_REL_ ZR_MIB_TOP_ab_Gen3 SG_ 508 ESP_Status_Bremsentemp_02 2000;
BA_REL_ "GenSigTimeoutTime" BU_SG_REL_ ZR_MIB_TOP_ab_Gen3 SG_ 508 ESP_EDS_Anzeige 2000;
BA_REL_ "GenSigTimeoutTime" BU_SG_REL_ ZR_MIB_TOP_ab_Gen3 SG_ 2527679658 FA_FahrerAnf_Fahrwerk 3200;
BA_REL_ "GenSigTimeoutTime" BU_SG_REL_ ZR_MIB_TOP_ab_Gen3 SG_ 2527679658 FA_FahrerAnf_Lift 3200;
BA_REL_ "GenSigTimeoutTime" BU_SG_REL_ ZR_MIB_TOP_ab_Gen3 SG_ 2527679658 FA_FahrerAnf_Niveau 3200;
BA_REL_ "GenSigTimeoutTime" BU_SG_REL_ ZR_Standard SG_ 496 EA_Infotainment_Anf 500;
BA_REL_ "GenSigTimeoutTime" BU_SG_REL_ ZR_Standard SG_ 1603 KBI_Einheit_Datum 5000;
BA_REL_ "GenSigTimeoutTime" BU_SG_REL_ ZR_Standard SG_ 1603 KBI_Einheit_Druck 5000;
BA_REL_ "GenSigTimeoutTime" BU_SG_REL_ ZR_Standard SG_ 1603 KBI_Einheit_Streckenanz 5000;
BA_REL_ "GenSigTimeoutTime" BU_SG_REL_ ZR_Standard SG_ 1603 KBI_MFA_v_Einheit_02 5000;
BA_REL_ "GenSigTimeoutTime" BU_SG_REL_ ZR_Standard SG_ 1603 KBI_Einheit_Temp 5000;
BA_REL_ "GenSigTimeoutTime" BU_SG_REL_ ZR_Standard SG_ 1603 KBI_Einheit_Uhrzeit 5000;
BA_REL_ "GenSigTimeoutTime" BU_SG_REL_ ZR_Standard SG_ 1603 KBI_Einheit_Verbrauch 5000;
BA_REL_ "GenSigTimeoutTime" BU_SG_REL_ ZR_Standard SG_ 1603 KBI_Einheit_Volumen 5000;
BA_REL_ "GenSigTimeoutTime" BU_SG_REL_ ZR_Standard SG_ 1603 KBI_Einheit_Sprache 5000;
BA_REL_ "GenSigTimeoutTime" BU_SG_REL_ ZR_Standard SG_ 260 EPB_Status_02 5000;
BA_REL_ "GenSigTimeoutTime" BU_SG_REL_ ZR_Standard SG_ 262 ESP_QBit_Bremsdruck 2000;
BA_REL_ "GenSigTimeoutTime" BU_SG_REL_ ZR_Standard SG_ 262 ESP_Bremsdruck 2000;
BA_REL_ "GenSigTimeoutTime" BU_SG_REL_ ZR_Standard SG_ 278 ESP_QBit_Wegimpuls_VL 500;
BA_REL_ "GenSigTimeoutTime" BU_SG_REL_ ZR_Standard SG_ 278 ESP_QBit_Wegimpuls_VR 500;
BA_REL_ "GenSigTimeoutTime" BU_SG_REL_ ZR_Standard SG_ 278 ESP_QBit_Wegimpuls_HL 500;
BA_REL_ "GenSigTimeoutTime" BU_SG_REL_ ZR_Standard SG_ 278 ESP_QBit_Wegimpuls_HR 500;
BA_REL_ "GenSigTimeoutTime" BU_SG_REL_ ZR_Standard SG_ 278 ESP_Wegimpuls_VL 500;
BA_REL_ "GenSigTimeoutTime" BU_SG_REL_ ZR_Standard SG_ 278 ESP_Wegimpuls_VR 500;
BA_REL_ "GenSigTimeoutTime" BU_SG_REL_ ZR_Standard SG_ 278 ESP_Wegimpuls_HL 500;
BA_REL_ "GenSigTimeoutTime" BU_SG_REL_ ZR_Standard SG_ 278 ESP_Wegimpuls_HR 500;
BA_REL_ "GenSigTimeoutTime" BU_SG_REL_ ZR_Standard SG_ 278 ESP_VL_Fahrtrichtung 500;
BA_REL_ "GenSigTimeoutTime" BU_SG_REL_ ZR_Standard SG_ 278 ESP_VR_Fahrtrichtung 500;
BA_REL_ "GenSigTimeoutTime" BU_SG_REL_ ZR_Standard SG_ 278 ESP_HL_Fahrtrichtung 500;
BA_REL_ "GenSigTimeoutTime" BU_SG_REL_ ZR_Standard SG_ 278 ESP_HR_Fahrtrichtung 500;
BA_REL_ "GenSigTimeoutTime" BU_SG_REL_ ZR_Standard SG_ 1629 ESP_Zaehnezahl 1600;
BA_REL_ "GenSigTimeoutTime" BU_SG_REL_ ZR_Standard SG_ 253 ESP_v_Signal 1000;
BA_REL_ "GenSigTimeoutTime" BU_SG_REL_ ZR_Standard SG_ 253 ESP_QBit_v_Signal 1000;
BA_REL_ "GenSigTimeoutTime" BU_SG_REL_ ZR_Standard SG_ 795 ESP_Wegimp_VA 500;
BA_REL_ "GenSigTimeoutTime" BU_SG_REL_ ZR_Standard SG_ 795 ESP_Fehlerstatus_Wegimp 500;
BA_REL_ "GenSigTimeoutTime" BU_SG_REL_ ZR_Standard SG_ 795 ESP_Wegimp_Ueberlauf 500;
BA_REL_ "GenSigTimeoutTime" BU_SG_REL_ ZR_Standard SG_ 795 ESP_QBit_Wegimp_VA 500;
BA_REL_ "GenSigTimeoutTime" BU_SG_REL_ ZR_Standard SG_ 795 ESP_HDC_Regelgeschw 500;
VAL_ 496 EA_Texte 0 "keine_Anzeige" 1 "Nothalteassistent_fehlende_Fahreraktivitaet" 2 "Nothalteassistent_aktiv_Fahrzeugfuehrung_uebernehmen" 3 "Nothalteassistent_automatischer_Nothalt_wird_durchgefuehrt" 4 "Nothalteassistent_automatischer_Nothalt_durchgefuehrt" 5 "Nothalteassistent_Verbindung_zum_Notruf_wird_aufgebaut" 6 "Nothalteassistent_deaktiviert" 7 "Nothalteassistent_Eingriff_abgebrochen" 8 "Nothalteassistent_fehlende_Fahreraktivitaet_2" 9 "Sekundenschlaf_erkannt" 10 "LaneAssist_Lenkung_uebernehmen" 11 "ACA_Fahrzeugfuehrung_uebernehmen" 12 "EA_Fahr_Standstreifenwechsel" 14 "Nothalteassistent_nicht_verfuegbar_reversibel" 15 "Nothalteassistent_Stoerung_irreversibel" ;
VAL_ 496 ACF_Lampe_Hands_Off 0 "keine_Anzeige" 1 "Hands_Off_erkannt" ;
VAL_ 496 EA_Infotainment_Anf 0 "Init" 1 "Keine_Absenkung" 2 "Absenkung" 3 "Mute" ;
VAL_ 496 EA_Tueren_Anf 0 "Keine_Anforderung" 1 "Tueren_entriegeln" ;
VAL_ 496 EA_Innenraumlicht_Anf 0 "Innenraumbeleuchtung_ausschalten" 1 "Innenraumbeleuchtung_einschalten" ;
VAL_ 496 zFAS_Warnblinken 0 "Aus" 1 "Statisch" 2 "Taster" 3 "Statisch_ohne_WBT" ;
VAL_ 496 STP_Primaeranz 0 "keine_Anzeige" 1 "Verfuegbar" 2 "Aktiv" 3 "Uebernahme" 4 "Aktiv_Warnung" 5 "Nicht_Verfuegbar" ;
VAL_ 496 EA_Bremslichtblinken 0 "kein_Blinken" 1 "Anforderung_Bremslichtblinken" ;
VAL_ 496 EA_Blinken 0 "Kein_Blinken" 1 "Wechselblinken_links" 2 "Wechselblinken_rechts" 3 "Warnblinken" 4 "Warnblinken_Taster" ;
VAL_ 2527679980 eCall_Statuslicht_Farbe2 0 "Aus" 1 "Blinken_1" 2 "Blinken_2" 3 "An" ;
VAL_ 2527679980 eCall_Statuslicht_Farbe1 0 "Aus" 1 "Blinken_1" 2 "Blinken_2" 3 "An" ;
VAL_ 2527679980 bCall_active 0 "bcall_inactive" 1 "bcall_active" ;
VAL_ 2527679980 eCall_Funktionsstatus 0 "kein_Fehler" 1 "Fkt_eingeschraenkt" 2 "Fkt_eingeschraenkt_service" 3 "Fkt_nicht_verfuegbar" 4 "Fkt_Service" 5 "Fkt_deaktiviert" 6 "Fkt_aktiviert" 7 "init" ;
VAL_ 2527679980 eCall_Subscription 0 "Init" 1 "unsubscribed" 2 "subscribed" ;
VAL_ 2527679980 eCall_Funktionsstatus_02 0 "kein_Fehler" 1 "Manueller_Notruf_aktiv" 2 "Automatischer_Notruf_aktiv" 7 "Init" ;
VAL_ 2527679980 eCall_Mute_Anf 0 "kein_mute" 1 "mute" ;
VAL_ 996 EFF_Verbraucher_Balken 510 "Init" 511 "Fehler" ;
VAL_ 996 EFF_Verbraucher_Pos_1 0 "keine_Anzeige" 1 "Klimaautomatik" 2 "Standheizung" 3 "Heckscheibe" 4 "Sitzheizung_links" 5 "Sitzheizung_rechts" 6 "Sitzlueftung_links" 7 "Sitzlueftung_rechts" 8 "Nackenheizung_links" 9 "Nackenheizung_rechts" 10 "Nebellicht_vorne" 11 "Nebelschlussleuchte" 12 "Frontscheibenheizung" 13 "Lenkradheizung" 14 "Spiegelheizung" 15 "Sitzheizung_hinten" 16 "Sitzlueftung_hinten" ;
VAL_ 996 EFF_Verbraucher_Pos_2 0 "keine_Anzeige" 1 "Klimaautomatik" 2 "Standheizung" 3 "Heckscheibe" 4 "Sitzheizung_links" 5 "Sitzheizung_rechts" 6 "Sitzlueftung_links" 7 "Sitzlueftung_rechts" 8 "Nackenheizung_links" 9 "Nackenheizung_rechts" 10 "Nebellicht_vorne" 11 "Nebelschlussleuchte" 12 "Frontscheibenheizung" 13 "Lenkradheizung" 14 "Spiegelheizung" 15 "Sitzheizung_hinten" 16 "Sitzlueftung_hinten" ;
VAL_ 996 EFF_Verbraucher_Pos_3 0 "keine_Anzeige" 1 "Klimaautomatik" 2 "Standheizung" 3 "Heckscheibe" 4 "Sitzheizung_links" 5 "Sitzheizung_rechts" 6 "Sitzlueftung_links" 7 "Sitzlueftung_rechts" 8 "Nackenheizung_links" 9 "Nackenheizung_rechts" 10 "Nebellicht_vorne" 11 "Nebelschlussleuchte" 12 "Frontscheibenheizung" 13 "Lenkradheizung" 14 "Spiegelheizung" 15 "Sitzheizung_hinten" 16 "Sitzlueftung_hinten" ;
VAL_ 996 EFF_Einsparhinweis 0 "Init" 1 "Erhoehter_Luftwiderst_Fenster" 2 "Erhoehter_Luftwiderst_Schiebedach" 3 "Erhoehter_Luftwiderst_Fenst_Schiebed" 4 "Nutzung_Motorbremse" 5 "Gaspedal_bei_Motorstart" 6 "Schaltanzeige_beachten" 7 "StartStop_nutzen" 8 "StartStop_einschalten" 9 "Ineff_Betrieb_Klima_Fenster" 10 "Ineff_Betrieb_Klima_Schiebedach" 11 "Ineff_Betrieb_Klima_Fenst_Schiebed" 12 "Fahrstufe_D_verwenden" 13 "Gaspedal_im_Stand" ;
VAL_ 996 EFF_Verbrauch_STH 127 "Fehler" ;
VAL_ 996 MKE_Texte 0 "keine_Anzeige" 1 "Warnstufe_1" 2 "Warnstufe_2" ;
VAL_ 996 MKE_FAS 0 "keine_Anzeige" 1 "Warnstufe_1" 2 "Warnstufe_2" ;
VAL_ 996 MKE_Stufe 0 "deaktiviert" 1 "nicht_verfügbar" 2 "Stufe_1" 3 "Stufe_2" 4 "Stufe_3" 5 "Stufe_4" 6 "reserviert" 7 "reserviert" ;
VAL_ 996 MKE_FAS_Fkt_Status 0 "Init" 1 "Funktion_Ist_Ein" 2 "Funktion_Ist_Aus" 3 "Fehler" ;
VAL_ 996 MKE_Fehlercode 0 "Init" 1 "gueltig" 2 "eingeschraenkt_gueltig" 3 "ungueltig" 4 "nicht_verbaut" ;
VAL_ 1603 KBI_Einheit_Datum 0 "Tag/Monat/Jahr" 1 "Monat/Tag/Jahr" 2 "Jahr/Monat/Tag" 3 "reserviert" ;
VAL_ 1603 KBI_Einheit_Druck 0 "Druckangabe in bar" 1 "Druckangabe in psi" 2 "Druckangabe in kPa" 3 "tbd." ;
VAL_ 1603 KBI_Einheit_Streckenanz 0 "Kilometer" 1 "Meilen" ;
VAL_ 1603 KBI_MFA_v_Einheit_02 0 "kmh" 1 "mph" ;
VAL_ 1603 KBI_Einheit_Temp 0 "Grad Celsius °C" 1 "Grad Fahrenheit °F" ;
VAL_ 1603 KBI_Einheit_Uhrzeit 0 "24h" 1 " 12h AM/PM" ;
VAL_ 1603 KBI_Einheit_Verbrauch 0 "mpg UK" 1 "mpg USA" 2 "Liter/100km" 3 "km/Liter" ;
VAL_ 1603 KBI_Einheit_Volumen 0 "Liter" 1 "Gallonen UK" 2 "Gallonen USA" 3 "reserviert" ;
VAL_ 1603 KBI_Einheit_Verbrauch_elektr 0 "kWh_pro_100km" 1 "km_pro_kWh" 2 "kWh_pro_100mls" 3 "mls_pro_kWh" 4 "MPGe" ;
VAL_ 1603 KBI_Einheit_Verbrauch_Gas 0 "kg_per_100km" 1 "km_per_kg" 2 "m3_per_100km" 3 "km_per_m3" 4 "miles_per_lbs" 5 "miles_per_yard3" 6 "miles_per_kg" 7 "miles_per_m3" 8 "miles_per_gallon_equivalent_US" ;
VAL_ 1603 KBI_Einheit_Masse 0 "kg" 1 "lbs" 2 "reserviert" ;
VAL_ 1622 ELV_Anf_Klemme_S 0 "Aus" 1 "Ein" ;
VAL_ 1622 ELV_Anf_Klemme_15 0 "Aus" 1 "Ein" ;
VAL_ 1622 ELV_Anf_Klemme_50 0 "Aus" 1 "Ein" ;
VAL_ 1622 ELV_01_Sendestatus 0 "ELV_sendet_mit_1000ms" 1 "ELV_sendet_mit_50ms" ;
VAL_ 1622 ELV_Verriegelt 0 "nicht_verriegelt" 1 "verriegelt" ;
VAL_ 1622 ELV_Entriegelt 0 "ELV_nicht_entriegelt" 1 "ELV_entriegelt" ;
VAL_ 1622 ELV_ZAT_betaetigt 0 "nicht_betaetigt" 1 "betaetigt" ;
VAL_ 1622 ELV_Lebenszustand 0 "Lebenszustand_0" 1 "Lebenszustand_4" ;
VAL_ 1622 ELV_Anlernmodus 0 "Normalbetrieb" 1 "Anlernmodus" ;
VAL_ 1622 ELV_Klemmenfreigabe 0 "keine_Freigabe" 1 "Freigabe" ;
VAL_ 1622 ELV_Abbruch_Anf_Klemmenfreigabe 0 "kein_Abbruch" 1 "Abbruch" ;
VAL_ 1622 ELV_LED_Rot 0 "Aus" 1 "Ein" ;
VAL_ 1622 ELV_LED_Gelb 0 "Aus" 1 "Ein" ;
VAL_ 1622 ELV_Txt_Panikabschaltung 0 "Aus" 1 "Ein" ;
VAL_ 1622 ELV_Txt_Lkg_Bewegen 0 "Aus" 1 "Ein" ;
VAL_ 1622 ELV_Txt_Werkstatt 0 "Aus" 1 "Ein" ;
VAL_ 1622 ELV_Txt_Defekt 0 "Aus" 1 "Ein" ;
VAL_ 1622 ELV_Txt_P_Gang 0 "Aus" 1 "Ein" ;
VAL_ 1622 ELV_Txt_PN_Gang 0 "Aus" 1 "Ein" ;
VAL_ 1622 ELV_Txt_Kupplung 0 "Aus" 1 "Ein" ;
VAL_ 1622 ELV_Txt_Bremse 0 "Aus" 1 "Ein" ;
VAL_ 1622 ELV_P_verriegelt 0 "nicht_verriegelt" 1 "verriegelt" ;
VAL_ 260 EPB_QBit_Pedalweg_Kuppl 0 "gültiger Wert" 1 "Ersatz-, Init- oder Fehlerwert" ;
VAL_ 260 EPB_Freig_Verzoeg_Anf 0 "nicht freigegeben" 1 "freigegeben" ;
VAL_ 260 EPB_Pedalweg_Kuppl 0 "Init" 255 "Fehler" ;
VAL_ 260 EPB_DAA_Randbed_erf 0 "Randbed_nicht_erfuellt" 1 "Randbed_erfuellt" ;
VAL_ 260 EPB_Fehlerstatus_02 0 "kein_Fehler" 1 "Fehler_ausserhalb_apply_release" 2 "Fehler_einseitig_apply_release" 3 "Fehler_beidseitig_apply_release" ;
VAL_ 260 EPB_Schalterposition 0 "keine Fahreranforderung" 1 "Fahreranforderung Öffnen" 2 "Fahreranforderung Schließen" 3 "Fehler" ;
VAL_ 260 EPB_QBit_Schalterpos 0 "gültiger Wert (volle Funktion)" 1 " Ersatz-, Init- oder Fehlerwert (Schalter ausser Funktion)" ;
VAL_ 260 EPB_Spannkraft 30 "Init" 31 "Fehler" ;
VAL_ 260 EPB_Status_02 0 "offen" 1 "geschlossen_Parken" 2 "teilgespannt_Halten" 3 "im_Lauf_oeffnen" 4 "im_Lauf_schliessen" 5 "tbd" 6 "Init" 7 "unbekannt" ;
VAL_ 781 EPB_Fehlerlampe_Gelb 0 "Aus" 1 "Ein" ;
VAL_ 781 EPB_Fehlerlampe_BKL 0 "BKL aus" 1 "BKL an" ;
VAL_ 781 EPB_Funktionslampe 0 "Aus" 1 "Ein" ;
VAL_ 781 EPB_Texte 0 "keine_Anzeige" 1 "Neigungswinkel_zu_gross" 2 "Parkbremse_von_Hand_oeffnen" 3 "HU_Modus_oder_EPB_in_Diagnose" 4 "Bremspedal_betaetigen" 5 "tbd" 6 "tbd" 7 "Stoerung_Anfahrassistent" 8 "Motor_starten" 9 "Feststellbremse_nicht_automatisch_geschlossen" 10 "Parkbremse_loesen_nicht_moeglich_Ladekabel_gesteckt" 11 "Notbremsung_ueber_EPB_Taster" 12 "Parkbremse_angezogen" 13 "Parkbremse_loesen_nicht_moeglich_ParkPilot_aktiv" ;
VAL_ 781 EPB_Akustik 0 "Warnton aus" 1 "Warnton an" ;
VAL_ 781 EPB_Autoholdlampe 0 "Lampe aus (Autohold inaktiv)" 1 "Lampe ein (Autohold aktiv)" ;
VAL_ 781 EPB_Bremsbelag_Warn 0 "Bremsbelag_ok" 1 "Bremsbelag_unter_Minimum" ;
VAL_ 781 EPB_Fehlermeldungen 0 "keine_Anzeige" 1 "Systemstoerung_Kl15an" 2 "Systemstoerung_Kl15aus" 3 "Parkbremse_betaetigen" 4 "Systemstoerung_Hanghaltefaehigkeit" 5 "Funktionseinschraenkung_Kl15an" 6 "Funktionseinschraenkung_Kl15aus" 7 "HU_Modus_aktiv" 8 "Transportmodus" 9 "Produktionsmodus" 10 "FktEinschr_Taster_defekt" ;
VAL_ 259 ESP_VL_FR 0 "Vorwaerts" 1 "Rueckwaerts" ;
VAL_ 259 ESP_VR_FR 0 "Vorwaerts" 1 "Rueckwaerts" ;
VAL_ 259 ESP_HL_FR 0 "Vorwaerts" 1 "Rueckwaerts" ;
VAL_ 259 ESP_HR_FR 0 "Vorwaerts" 1 "Rueckwaerts" ;
VAL_ 259 ESP_VL_Radgeschw 4093 "Unterspannung" 4094 "Init" 4095 "Fehler" ;
VAL_ 259 ESP_VR_Radgeschw 4093 "Unterspannung" 4094 "Init" 4095 "Fehler" ;
VAL_ 259 ESP_HL_Radgeschw 4093 "Unterspannung" 4094 "Init" 4095 "Fehler" ;
VAL_ 259 ESP_HR_Radgeschw 4093 "Unterspannung" 4094 "Init" 4095 "Fehler" ;
VAL_ 262 ESP_QBit_Bremsdruck 0 "gueltiger_Wert" 1 "Ersatz_Init_oder_Fehlerwert" ;
VAL_ 262 ESP_QBit_Fahrer_bremst 0 "gueltiger_Wert" 1 "Ersatz_Init_oder_Fehlerwert" ;
VAL_ 262 ESP_Schwelle_Unterdruck 0 "kein_Signal" 1 "Unterdruck_kleiner_gleich_450_mbar" 2 "Unterdruck_groesser_450_mbar" 3 "Fehler_Unterdrucksensor" ;
VAL_ 262 ESP_Bremsdruck 1023 "Fehler" ;
VAL_ 262 ESP_Fahrer_bremst 0 "Bremsdruckschwelle_nicht_ueberschritten" 1 "Bremsdruckschwelle_ueberschritten" ;
VAL_ 262 ESP_Lenkeingriff_ADS 0 "kein_Lenkeingriff" 1 "stabilisierender_Lenkeingriff" ;
VAL_ 262 ECD_Fehler 0 "ECD_iO" 1 "ECD_Fehler" ;
VAL_ 262 ECD_nicht_verfuegbar 0 "ECD_Funktion_verfuegbar" 1 "ECD_Funktion_nicht_verfuegbar" ;
VAL_ 262 ESP_Status_Bremsentemp 0 "Bremse_nicht_ueberhitzt" 1 "Bremse_ueberhitzt" ;
VAL_ 262 ESP_Autohold_Standby 0 "Autohold_nicht_im_Standby" 1 "Autohold_im_Standby" ;
VAL_ 262 ESP_HDC_Standby 0 "HDC_Funktion_nicht_im_Standby" 1 "HDC_Funktion_im_Standby" ;
VAL_ 262 ESP_HBA_aktiv 0 "HBA_nicht_aktiv" 1 "HBA_aktiv" ;
VAL_ 262 ESP_Prefill_ausgeloest 0 "nicht_ausgeloest" 1 "Prefill_ausgeloest" ;
VAL_ 262 ESP_Rueckwaertsfahrt_erkannt 0 "keine_Rueckwaetsfahrt" 1 "Rueckwaertsfahrt_sicher_erkannt" ;
VAL_ 262 ESP_Status_Anfahrhilfe 0 "Aus" 1 "Ein" ;
VAL_ 262 ESP_HDC_aktiv 0 "inaktiv" 1 "aktiv" ;
VAL_ 262 ESP_StartStopp_Info 0 "Motorlauf_nicht_notwendig_(Stoppfreigabe)" 1 "Motoranlauf_nicht_zwingend_notwendig_(Stoppverbot,keine_Startanforderung)" 2 "Motoranlauf_zwingend_notwendig_(Startanforderung)" 3 "Systemfehler" ;
VAL_ 262 ESP_Eingr_HL 0 "kein_Eingriff" 1 "ESP_Eingriff_HL" ;
VAL_ 262 ESP_Eingr_HR 0 "kein_Eingriff" 1 "ESP_Eingriff_HR" ;
VAL_ 262 ESP_Eingr_VL 0 "kein_Eingriff" 1 "ESP_Eingriff_VL" ;
VAL_ 262 ESP_Eingr_VR 0 "kein_Eingriff" 1 "ESP_Eingriff_VR" ;
VAL_ 262 ESP_BKV_Unterdruck 0 "nicht_verbaut_oder_nicht_kodiert" 254 "Init" 255 "Fehler" ;
VAL_ 262 ESP_Autohold_aktiv 0 "Autohold_inaktiv" 1 "Autohold_aktiv" ;
VAL_ 262 ESP_FStatus_Anfahrhilfe 0 "kein_Fehler" 1 "Fehler" ;
VAL_ 262 ESP_Verz_EPB_aktiv 0 "nicht_aktiviert" 1 "aktiviert" ;
VAL_ 262 ESC_Bremslicht 0 "Aus" 1 "Ein" ;
VAL_ 262 ESP_Verzoeg_EPB_verf 0 "nicht_verfuegbar" 1 "System_verfuegbar" ;
VAL_ 262 ESP_Status_Bremsdruck 0 "Bremse_drucklos" 1 "mit_Bremsdruck" ;
VAL_ 262 ESP_Anforderung_EPB 0 "keine_Anforderung" 1 "Anforderung_Oeffnen" 2 "Anforderung_Schliessen" 3 "reserviert" ;
VAL_ 914 ESP_Allrad_Antrieb 0 "Front" 1 "Allrad" ;
VAL_ 914 ESP_Codierung_ADS 0 "Init" 1 "ESP_nicht_ADS_codiert" 2 "ADS_codiert" 3 "tbd" ;
VAL_ 914 ESP_RTA_HL 254 "Abgleich_nocht_nicht_genuegend_konvergent" 255 "Fehler" ;
VAL_ 914 ESP_RTA_HR 254 "Abgleich_nocht_nicht_genuegend_konvergent" 255 "Fehler" ;
VAL_ 914 ESP_RTA_VR 254 "Abgleich_nocht_nicht_genuegend_konvergent" 255 "Fehler" ;
VAL_ 914 OBD_Fehler_Radsensor_HL 0 "kein Fehler / Init / nicht verbaut" 1 "KS- (Kurzschluss nach minus)" 2 "KS+ (Kurzschluss nach plus)" 3 "OC (Leitungsunterbrechung)" 4 "OOR+ (Signal zu gross)" 5 "OOR- (Signal zu klein)" 6 "RC+ (Signal unplausibel zu gross)" 7 "RC- (Signal unplausibel zu klein)" 8 "KS+/OC (Kurzschluss nach plus/Unterbrechung)" 9 "KS-/OC  (Kurzschluss nach minus/Unterbrechung)" 10 "KS-/KS+  (Kurzschluss nach minus/plus)" 11 "KS-/KS+/OC (Kurzschluss nach minus/plus/Unterbrechung)" 12 "frei" 13 "frei" 14 "frei" 15 "frei" ;
VAL_ 914 OBD_Fehler_Radsensor_HR 0 "kein Fehler / Init / nicht verbaut" 1 "KS- (Kurzschluss nach minus)" 2 "KS+ (Kurzschluss nach plus)" 3 "OC (Leitungsunterbrechung)" 4 "OOR+ (Signal zu gross)" 5 "OOR- (Signal zu klein)" 6 "RC+ (Signal unplausibel zu gross)" 7 "RC- (Signal unplausibel zu klein)" 8 "KS+/OC (Kurzschluss nach plus/Unterbrechung)" 9 "KS-/OC  (Kurzschluss nach minus/Unterbrechung)" 10 "KS-/KS+  (Kurzschluss nach minus/plus)" 11 "KS-/KS+/OC (Kurzschluss nach minus/plus/Unterbrechung)" 12 "frei" 13 "frei" 14 "frei" 15 "frei" ;
VAL_ 914 OBD_Fehler_Radsensor_VL 0 "kein Fehler / Init / nicht verbaut" 1 "KS- (Kurzschluss nach minus)" 2 "KS+ (Kurzschluss nach plus)" 3 "OC (Leitungsunterbrechung)" 4 "OOR+ (Signal zu gross)" 5 "OOR- (Signal zu klein)" 6 "RC+ (Signal unplausibel zu gross)" 7 "RC- (Signal unplausibel zu klein)" 8 "KS+/OC (Kurzschluss nach plus/Unterbrechung)" 9 "KS-/OC  (Kurzschluss nach minus/Unterbrechung)" 10 "KS-/KS+  (Kurzschluss nach minus/plus)" 11 "KS-/KS+/OC (Kurzschluss nach minus/plus/Unterbrechung)" 12 "frei" 13 "frei" 14 "frei" 15 "frei" ;
VAL_ 914 OBD_Fehler_Radsensor_VR 0 "kein Fehler / Init / nicht verbaut" 1 "KS- (Kurzschluss nach minus)" 2 "KS+ (Kurzschluss nach plus)" 3 "OC (Leitungsunterbrechung)" 4 "OOR+ (Signal zu gross)" 5 "OOR- (Signal zu klein)" 6 "RC+ (Signal unplausibel zu gross)" 7 "RC- (Signal unplausibel zu klein)" 8 "KS+/OC (Kurzschluss nach plus/Unterbrechung)" 9 "KS-/OC  (Kurzschluss nach minus/Unterbrechung)" 10 "KS-/KS+  (Kurzschluss nach minus/plus)" 11 "KS-/KS+/OC (Kurzschluss nach minus/plus/Unterbrechung)" 12 "frei" 13 "frei" 14 "frei" 15 "frei" ;
VAL_ 914 ESP_Qualifizierung_Antriebsart 0 "alte_Bedeutung_Bit_ESP_Allrad_Antrieb" 1 "neue_Bedeutung_Bit_ESP_Allrad_Antrieb" ;
VAL_ 914 ESP_Offroad_Modus 0 "kein_ESP_Offroadmodus" 1 "ESP_Offroadmodus" ;
VAL_ 914 ESP_MKB_ausloesbar 0 "Multikollisionsbremsung_nicht_freigeschaltet" 1 "Multikollisionsbremsung_freigeschaltet" ;
VAL_ 914 ESP_Stat_FallBack_eBKV 0 "Rueckfallebene_nicht_vorhanden" 1 "Rueckfallebene_vorhanden" ;
VAL_ 914 ESC_cAQP_Trigger 0 "AQP_Trigger_nicht_aktiv" 1 "AQP_Trigger_aktiv" ;
VAL_ 914 ESP_OBD_Status 0 "MIL_aus" 1 "MIL_ein" ;
VAL_ 914 ESP_Rollenmodus_Deaktivieren 0 "keine_Aenderung" 1 "Abbruch" ;
VAL_ 914 ESP_nachtr_Stopp_Anf 0 "nicht_angefordert" 1 "angefordert" ;
VAL_ 278 ESP_QBit_Wegimpuls_VL 0 "gueltiger_Wert" 1 "Ersatz_Init_oder_Fehlerwert" ;
VAL_ 278 ESP_QBit_Wegimpuls_VR 0 "gueltiger_Wert" 1 "Ersatz_Init_oder_Fehlerwert" ;
VAL_ 278 ESP_QBit_Wegimpuls_HL 0 "gueltiger_Wert" 1 "Ersatz_Init_oder_Fehlerwert" ;
VAL_ 278 ESP_QBit_Wegimpuls_HR 0 "gueltiger_Wert" 1 "Ersatz_Init_oder_Fehlerwert" ;
VAL_ 278 ESP_Wegimpuls_VL 1021 "Init" 1022 "Unterspannung" 1023 "Fehler" ;
VAL_ 278 ESP_Wegimpuls_VR 1021 "Init" 1022 "Unterspannung" 1023 "Fehler" ;
VAL_ 278 ESP_Wegimpuls_HL 1021 "Init" 1022 "Unterspannung" 1023 "Fehler" ;
VAL_ 278 ESP_Wegimpuls_HR 1021 "Init" 1022 "Unterspannung" 1023 "Fehler" ;
VAL_ 278 ESP_VL_Fahrtrichtung 0 "Vorwaerts" 1 "Rueckwaerts" 2 "Init" 3 "ungueltig_oder_nicht_verbaut" ;
VAL_ 278 ESP_VR_Fahrtrichtung 0 "Vorwaerts" 1 "Rueckwaerts" 2 "Init" 3 "ungueltig_oder_nicht_verbaut" ;
VAL_ 278 ESP_HL_Fahrtrichtung 0 "Vorwaerts" 1 "Rueckwaerts" 2 "Init" 3 "ungueltig_oder_nicht_verbaut" ;
VAL_ 278 ESP_HR_Fahrtrichtung 0 "Vorwaerts" 1 "Rueckwaerts" 2 "Init" 3 "ungueltig_oder_nicht_verbaut" ;
VAL_ 418 HMS_P_beibehalten_GE 0 "P_nicht_beibehalten" 1 "P_beibehalten" 2 "Init" 3 "Fehler" ;
VAL_ 418 HMS_Konsistenz_GE 0 "kein_Fehler_erkannt" 1 "Fehler_erkannt" ;
VAL_ 418 HMS_Konsistenz_IPA 0 "kein_Fehler_erkannt" 1 "Fehler_erkannt" ;
VAL_ 418 HMS_Konsistenz_STA 0 "kein_Fehler_erkannt" 1 "Fehler_erkannt" ;
VAL_ 418 HMS_Konsistenz_MO 0 "kein_Fehler_erkannt" 1 "Fehler_erkannt" ;
VAL_ 418 HMS_halten_nicht_verfuegbar 0 "verfuegbar" 1 "nicht_verfuegbar" ;
VAL_ 418 NL_PRIM_STP_01_Status 0 "Notlauf_inaktiv" 1 "Notlauf_bereit" 2 "Notlauf_aktiv" 3 "Notlauf_nicht_verfuegbar" 4 "Notlauf_aktivierbar" ;
VAL_ 418 VMM_Warnblinken 0 "Aus" 1 "An" ;
VAL_ 418 VZM_Status 0 "Initialisierung" 1 "Verfuegbar" 2 "Verfuegbar_mit_eingeschraenkter_Performance" 3 "Nicht_Verfuegbar" 4 "Fehler" ;
VAL_ 418 HMS_Notstopp_Status 0 "Off_Init" 1 "Inaktiv" 2 "Ready" 3 "Aktiv" 4 "Pending" 7 "nicht_Verfuegbar" ;
VAL_ 418 HMS_parken_nicht_verfuegbar 0 "verfuegbar" 1 "nicht_verfuegbar" ;
VAL_ 418 HMS_Anforderung_GE 0 "keine_Anforderung" 1 "P_einlegen" ;
VAL_ 418 HMS_Systemstatus 0 "keine_Funktion_aktiv" 1 "Halten_aktiv" 2 "Parken_angefordert" 3 "Parken_aktiv" 4 "Parken_beibehalten_aktiv" 5 "Anfahren_aktiv" 6 "Loeseanforderung_aktiv" 7 "Loeseanforderung_durch_Fahrer" 8 "Abrutschen_erkannt" 9 "Halten_Standby_aktiv" 10 "Anfahren_Standby_aktiv" 14 "Init" 15 "Fehler" ;
VAL_ 418 HMS_Stillstand 0 "kein_Stillstand" 1 "Stillstand_frueh" 2 "Stillstand" 6 "Init" 7 "Fehler" ;
VAL_ 418 HMS_aktives_System 0 "kein_System__Init_Fehler" 1 "Fahreranforderung_aktiv" 2 "HMS_intern_aktiv" 3 "ACC_aktiv" 4 "Autohold_aktiv" 5 "HHC_aktiv" 6 "HVLM_aktiv" 7 "Getriebe_aktiv" 8 "EBKV_aktiv" 9 "ParkAssist_aktiv" 10 "ARA_aktiv" 12 "autonomous_Hold_aktiv" 13 "STA_aktiv" 14 "Motor_aktiv" 15 "EA_aktiv" 16 "VLK_aktiv" ;
VAL_ 418 HMS_Konsistenz_HVLM 0 "kein_Fehler_erkannt" 1 "Fehler_erkannt" ;
VAL_ 418 HMS_Konsistenz_ACC 0 "kein_Fehler_erkannt" 1 "Fehler_erkannt" ;
VAL_ 418 HMS_Fehlerstatus 0 "kein_Fehler" 1 "Halten_nicht_moeglich" 2 "Sonderbetriebsmodus_aktiv" 3 "Systemeinschraenkung" 4 "Systemstoerung" ;
VAL_ 418 ESP_Index_Haltemoment 0 "Bremsmoment" 1 "Antriebsmoment" ;
VAL_ 418 ESP_Haltemoment 1022 "Init" 1023 "Fehler" ;
VAL_ 1629 BR_Systemart 0 "ABS" 1 "ABS_ASR" 2 "ESP" 3 "ESP_mit_integrierter_EPB" ;
VAL_ 1629 ESP_SpannungsAnf_02 0 "keine_Anforderung" 1 "Anforderung_Stufe1" 2 "Anforderung_Stufe2" 3 "Anforderung_Stufe3" ;
VAL_ 1629 ESP_Charisma_FahrPr 0 "keine_Funktion" 1 "Programm_1" 2 "Programm_2" 3 "Programm_3" 4 "Programm_4" 5 "Programm_5" 6 "Programm_6" 7 "Programm_7" 8 "Programm_8" 9 "Programm_9" 10 "Programm_10" 11 "Programm_11" 12 "Programm_12" 13 "Programm_13" 14 "Programm_14" 15 "Programm_15" ;
VAL_ 1629 ESP_Charisma_Status 0 "Init" 1 "verfuegbar" 2 "nicht_verfuegbar" 3 "asynchron_durch_Fahrerwunsch" ;
VAL_ 1629 ESP_Wiederstart_Anz_01 0 "keine_Anzeige" 1 "Rueckwaertsrollen" ;
VAL_ 1629 ESP_Wiederstart_Anz_02 0 "keine_Anzeige" 1 "Autohold_Rutschen" ;
VAL_ 1629 ESP_Wiederstart_Anz_03 0 "keine_Anzeige" 1 "Offroad_HDC" ;
VAL_ 1629 ESP_Wiederstart_Anz_04 0 "keine_Anzeige" 1 "ESC_Off" ;
VAL_ 1629 ESP_Stoppverbot_Anz_01 0 "keine_Anzeige" 1 "Notbremsung_aktiv" ;
VAL_ 1629 ESP_Stoppverbot_Anz_02 0 "keine_Anzeige" 1 "Autohold_AVH_Rutschen" ;
VAL_ 1629 ESP_Stoppverbot_Anz_03 0 "keine_Anzeige" 1 "Rueckwaertsrollen" ;
VAL_ 1629 ESP_Stoppverbot_Anz_04 0 "keine_Anzeige" 1 "ESP_Pumpenlauf" ;
VAL_ 1629 ESP_Stoppverbot_Anz_05 0 "keine_Anzeige" 1 "ESP_OFF" ;
VAL_ 1629 ESP_Stoppverbot_Anz_06 0 "keine_Anzeige" 1 "Offroad_HDC" ;
VAL_ 1629 ESP_Stoppverbot_Anz_07 0 "keine_Anzeige" 1 "ESP_Haltefunktion_nicht_verfuegbar" ;
VAL_ 1629 ESP_Stoppverbot_Anz_Std 0 "keine_Anzeige" 1 "Standard_Stoppvetogrund" ;
VAL_ 1629 ESP_Dachrelingsensor 0 "Sensor_nicht_verbaut" 1 "Quertraeger_montiert" 2 "Quertraeger_nicht_montiert" 3 "Fehler" ;
VAL_ 1629 ESP_Stoppverbot_Anz_08 0 "keine_Anzeige" 1 "Neigungsbegrenzung" ;
VAL_ 1629 HDC_Charisma_FahrPr 0 "keine_Funktion" 1 "Programm_1" 2 "Programm_2" 3 "Programm_3" 4 "Programm_4" 5 "Programm_5" 6 "Programm_6" 7 "Programm_7" 8 "Programm_8" 9 "Programm_9" 10 "Programm_10" 11 "Programm_11" 12 "Programm_12" 13 "Programm_13" 14 "Programm_14" 15 "Programm_15" ;
VAL_ 1629 HDC_Charisma_Status 0 "Init" 1 "verfuegbar" 2 "nicht_verfuegbar" 3 "asynchron_durch_Fahrerwunsch" ;
VAL_ 1629 BR_QBit_Reifenumfang 0 "gueltiger_Wert" 1 "Ersatz_Init_oder_Fehlerwert" ;
VAL_ 253 BR_Eingriffsmoment 1022 "Init" 1023 "Fehler" ;
VAL_ 253 ESP_Diagnose 0 "ESP_nicht_in_Diagnose" 1 "ESP_in_Diagnose" ;
VAL_ 253 ESC_v_Signal_Qualifier_High_Low 0 "Gueteschwelle_kleiner_1kmh" 1 "Gueteschwelle_kleiner_3kmh" 2 "Gueteschwelle_kleiner_5kmh" 3 "Gueteschwelle_kleiner_10kmh" 4 "Gueteschwelle_kleiner_20kmh" 5 "Gueteschwelle_groessergleich_20kmh" 6 "Init" 7 "Fehler" ;
VAL_ 253 ESP_Vorsteuerung 0 "keine_Vorsteuerung_aktiv" 1 "Vorsteuerung_aktiv" ;
VAL_ 253 OBD_Schlechtweg 0 "kein_Schlechtweg_erkannt" 1 "Schlechtweg_erkannt" ;
VAL_ 253 OBD_QBit_Schlechtweg 0 "gueltiger_Wert" 1 "Ersatz_Init_oder_Fehlerwert" ;
VAL_ 253 ESP_v_Signal 65533 "Unterspannung" 65534 "Init" 65535 "Fehler" ;
VAL_ 253 ASR_Tastung_passiv 0 "ASR_aktiviert" 1 "ASR_passiv_getastet_oder_Schwellen_geaendert" ;
VAL_ 253 ESP_Tastung_passiv 0 "ESP_aktiviert" 1 "ESP_passiv_getastet_oder_Schwellen_geaendert" ;
VAL_ 253 ESP_Systemstatus 0 "iO" 1 "Fehler" ;
VAL_ 253 ASR_Schalteingriff 0 "keine_Anforderung" 1 "ASR_Schaltkennfeld" 2 "Rueckschaltung" 3 "Schaltverbot" ;
VAL_ 253 ESP_QBit_v_Signal 0 "gueltiger_Wert" 1 "Ersatz_Init_oder_Fehlerwert" ;
VAL_ 253 ABS_Bremsung 0 "keine_ABS_Regelung" 1 "ABS_Regelung_aktiv" ;
VAL_ 253 ASR_Anf 0 "keine_Anforderung" 1 "ASR_Anforderung" ;
VAL_ 253 MSR_Anf 0 "keine Anfoderung" 1 "MSR-Anforderung" ;
VAL_ 253 EBV_Eingriff 0 "kein_EBV_Eingriff" 1 "EBV_Eingriff" ;
VAL_ 253 EDS_Eingriff 0 "kein_EDS_Eingriff" 1 "EDS_Eingriff" ;
VAL_ 253 ESP_Eingriff 0 "kein_ESP_Eingriff" 1 "ESP_Eingriff_aktiv" ;
VAL_ 253 ESP_ASP 0 "inaktiv" 1 "aktiv" ;
VAL_ 253 ESC_Neutralschaltung 0 "keine_Anforderung" 1 "Neutralschaltung_angefordert" ;
VAL_ 239 ESP_QBit_VL_Bremsmoment 0 "gueltiger_Wert" 1 "Ersatz_Init_oder_Fehlerwert" ;
VAL_ 239 ESP_QBit_VR_Bremsmoment 0 "gueltiger_Wert" 1 "Ersatz_Init_oder_Fehlerwert" ;
VAL_ 239 ESP_QBit_HL_Bremsmoment 0 "gueltiger_Wert" 1 "Ersatz_Init_oder_Fehlerwert" ;
VAL_ 239 ESP_QBit_HR_Bremsmoment 0 "gueltiger_Wert" 1 "Ersatz_Init_oder_Fehlerwert" ;
VAL_ 239 ESP_VL_Bremsmoment 254 "Init" 255 "Fehler" ;
VAL_ 239 ESP_VR_Bremsmoment 254 "Init" 255 "Fehler" ;
VAL_ 239 ESP_HL_Bremsmoment 254 "Init" 255 "Fehler" ;
VAL_ 239 ESP_HR_Bremsmoment 254 "Init" 255 "Fehler" ;
VAL_ 239 ESP_FZR_uebersteuern 254 "Init" 255 "Fehler" ;
VAL_ 239 ESP_FZR_untersteuern 254 "Init" 255 "Fehler" ;
VAL_ 1470 ESP_Gierrate_Offset_2 2046 "Init" 2047 "Fehler" ;
VAL_ 1470 ESP_Lenkwinkel_Offset 510 "Init" 511 "Fehler" ;
VAL_ 1470 BR_QBit_Reifenumfang_sekundaer 0 "gueltiger_Wert" 1 "Ersatz_Init_oder_Fehlerwert" ;
VAL_ 1470 ESP_Status_Bremsentemp_Anz 0 "Init" 1 "kalt" 2 "warm" 3 "heiss" 4 "ueberhitzt" 5 "nass" 7 "Fehler" ;
VAL_ 1470 ESP_Querbeschleunigung_Offset 62 "Init" 63 "Fehler" ;
VAL_ 1470 ESP_Laengsbeschleunigung_Offset 254 "Init" 255 "Fehler" ;
VAL_ 795 ESP_Lampe 0 "Aus" 1 "Ein" ;
VAL_ 795 ABS_Lampe 0 "Aus" 1 "Ein" ;
VAL_ 795 BK_Lampe_02 0 "aus" 1 "Typ1_ein_statisch" 2 "Typ2_ein_statisch" 3 "Warnung" ;
VAL_ 795 TC_Lampe 0 "Aus" 1 "Ein" ;
VAL_ 795 ESP_m_Raddrehz 32765 "Unterspannung" 32766 "Init" 32767 "Fehler" ;
VAL_ 795 ESP_Textanzeigen_03 0 "kein_Text" 1 "ESP_Stoerung" 2 "ABS_Stoerung" 3 "ESP_ABS_Stoerung" 4 "Werkstatt_Bremse" 5 "ASR_Stoerung" 6 "ESP_switched_off" 7 "ASR_off" 8 "ESP_ASR_on" 10 "keine_Bremskraftverstaerkung" 11 "ASR_aktiviert" 12 "ABS_ASR_Stoerung" 15 "ESP_offroad" 17 "ESP_sport" 18 "ESP_Zwangsaktivierung" 19 "ESP_Taster_Info" 20 "TC_aktiv" 21 "reserviert_fuer_Verlwarn" 22 "TC_switched_off" 23 "Verlwarn_akt_Rollsicher_inakt" 24 "ESP_SuperSport" 25 "ESP_Offroad_nicht_verfuegbar" ;
VAL_ 795 ESP_Meldungen 0 "keine_Anzeige" 1 "Autohold_Hinweis_1" 2 "Stoerung_Autohold" 3 "Stoerung_Hillholder" 4 "Uebernehmen" 5 "Autohold_aus" 6 "Autohold_Hinweis_2" ;
VAL_ 795 ESP_Fehlerstatus_Wegimp 0 "Wegimpulse_iO" 1 "Fehler" ;
VAL_ 795 ESP_Wegimp_Ueberlauf 0 "Reset_und_kein_Ueberlauf" 1 "mindestens_1x_Ueberlauf" ;
VAL_ 795 ESP_QBit_Wegimp_VA 0 "gueltiger_Wert" 1 "Ersatz_Init_oder_Fehlerwert" ;
VAL_ 795 ESP_HDC_Geschw_Farbe 0 "Standard_Farbe" 1 "abweichende_Farbe" ;
VAL_ 795 ESP_Off_Lampe 0 "Lampe_aus" 1 "Lampe_ein" ;
VAL_ 795 ESP_HDC_Regelgeschw 0 "nicht_verbaut" 125 "HDC_Standby" 126 "Init" 127 "Fehler" ;
VAL_ 795 ESP_BKV_Warnung 0 "keine_Anzeige" 1 "keine_Bremskraftverstaerkung" ;
VAL_ 508 ESP_Status_Bremsentemp_02 0 "nicht_erhoeht" 1 "Schwelle_1" 2 "Schwelle_2" ;
VAL_ 508 ESP_Aggregataktivitaet 0 "inaktiv" 1 "aktiv" ;
VAL_ 508 ESP_Stillstandsflag 0 "kein_Stillstand_erkannt" 1 "Stillstand_erkannt" ;
VAL_ 508 ESC_MBK_Meldungen 0 "kein_Text" 1 "MBK_Hinweis_aktiv" 2 "MBK_Eskalation1_aktiv" ;
VAL_ 508 ESP_EDS_Anzeige 0 "Keine_Anzeige_aktiv" 1 "EDS_nicht_aktiv" 2 "EDS_aktiv_an_VA" 3 "EDS_aktiv_an_HA" 4 "EDS_aktiv_an_VA_und_HA" 5 "EDS_Uebertemperatur" 6 "EDS_Fehler" ;
VAL_ 508 RLE_Anzeigen 0 "keine_Anzeige" 1 "Rad_lose_allgemein" 2 "Rad_VL_lose" 3 "Rad_VR_lose" 4 "Rad_HL_lose" 5 "Rad_HR_lose" 6 "RLE_Pruefphase" 7 "RLE_Systemstoerung" ;
VAL_ 508 ESP_Wiederstart_Anz_Std 0 "keine_Anzeige" 1 "Standard_Wiederstartgrund" ;
VAL_ 508 ESC_Anforderung_Airbrake 0 "keine_Anforderung" 1 "Anf_Bremsperformancestellung" ;
VAL_ 508 ESC_FBA_Meldungen 0 "kein_Text" 1 "FBA_Warnung_aktiv_MT" 2 "FBA_Warnung_aktiv_AT" ;
VAL_ 508 ESP_Rollover_Status_dyn 0 "Auspraegung1" 1 "Auspraegung2" 2 "Auspraegung3" 3 "Auspraegung4" ;
VAL_ 508 ESP_Rollover_Status_stat 0 "Auspraegung1" 1 "Auspraegung2" 2 "Auspraegung3" 3 "Auspraegung4" ;
VAL_ 508 ESP_AVH_LED 0 "LED_aus" 1 "LED_ein" 2 "LED_blinken" 3 "Funktion_gesperrt__LED_aus" 6 "Init" ;
VAL_ 508 ESP_HDC_LED 0 "LED_aus" 1 "LED_ein" 2 "LED_blinken" 3 "Funktion_gesperrt__LED_aus" 6 "Init" ;
VAL_ 508 ESP_Off_LED 0 "LED_aus" 1 "LED_ein" 2 "LED_blinken" 3 "Funktion_gesperrt__LED_aus" 6 "Init" ;
VAL_ 508 ESP_Notbremsanzeige 0 "keine_Notbremsung_erkannt" 1 "Notbremsung_erkannt" ;
VAL_ 508 ESC_Motorstartverzoegerung 0 "Startfreigabe" 1 "Anforderung_Startverzoegerung" ;
VAL_ 508 ESP_Offroad_Lampe 0 "Aus" 1 "Ein" ;
VAL_ 508 ESP_HDC_Textanzeigen 0 "kein_Text" 1 "HDC_ein" 2 "HDC_aus" 3 "HDC_nicht_verfuegbar_in_FahrPr" 4 "HDC_nicht_verfuegbar_Uebertemp" 5 "HDC_verfuegbar_keine_Uebertemp" 6 "HDC_nicht_verfuegbar_ACC_aktiv" 7 "HDC_nicht_verfuegbar_GRA_aktiv" 8 "HDC_nicht_verfuegbar_LIM_aktiv" 9 "HDC_nicht_verfuegbar_IPA_aktiv" 10 "HDC_nicht_verfuegbar_PLA_aktiv" 11 "HDC_nicht_verf_anderes_Syst_akt" 12 "HDC_nicht_verfuegbar_Fehler" 13 "GRA_Hebel_einschalten" 14 "Funk_nicht_verfuegbar_bei_HDC" 15 "Funk_verfuegbar_wenn_HDC_aktiv" 16 "Deaktivierung_ESP_Eingriff" 17 "HDC_nicht_verfuegbar_ABS_solo" 18 "HDC_nicht_verfuegbar_Gaspedal" ;
VAL_ 508 ESP_HOLD_verf 0 "nicht_verfuegbar" 1 "verfuegbar" ;
VAL_ 600 ESP_DriftLevel 0 "Init" 1 "Level_1" 2 "Level_2" 3 "Level_3" 4 "Level_4" 5 "Level_5" 6 "Not_Available" ;
VAL_ 600 ESP_DriftText 0 "Text_1" 1 "Text_2" 2 "Text_3" 3 "Text_4" 4 "Text_5" 5 "Text_6" 6 "Text_7" 7 "Text_8" 8 "Text_9" 9 "Text_10" ;
VAL_ 600 ESP_DriftStatus 0 "Not_active" 1 "Active" ;
VAL_ 600 ESP_DriftGong 0 "Not_Active" 1 "Active" ;
VAL_ 600 ESP_Slider_Text 0 "Text_1" 1 "Text_2" 2 "Text_3" 3 "Text_4" 4 "Text_5" 5 "Text_6" 6 "Text_7" 7 "Text_8" 8 "Text_9" 9 "Text_10" ;
VAL_ 600 ESP_Slider_Lamp 0 "Lamp_off" 1 "Lamp_on" ;
VAL_ 600 ESP_Slider_Gong 0 "Not_Active" 1 "Active" ;
VAL_ 600 ESP_Slider_Status 0 "Not_active" 1 "Active" 2 "Disabled" ;
VAL_ 600 ESP_Slider_ist_01 127 "invalid" ;
VAL_ 600 ESP_Slider_ist_02 127 "invalid" ;
VAL_ 600 ESP_Slider_ist_03 127 "invalid" ;
VAL_ 264 FA_Hoehenwerte_kalibriert 0 "kalibrierte_Hoehenwerte_in_mm" 1 "Rohwerte" ;
VAL_ 264 EFP_Anf_Bremsenkuehlung 0 "keine_Anforderung" 1 "SKE_oeffnen" 2 "SKE_oeffnen_Luefter_ansteuern" ;
VAL_ 264 FA_Hoehenwert_VL_00 254 "nicht initialisiert" 255 "Fehler" ;
VAL_ 264 FA_Hoehenwert_VR_00 254 "nicht initialisiert" 255 "Fehler" ;
VAL_ 264 FA_Hoehenwert_HL_00 254 "nicht initialisiert" 255 "Fehler" ;
VAL_ 264 FA_Hoehenwert_HR_00 254 "nicht initialisiert" 255 "Fehler" ;
VAL_ 264 FA_Fahrbahnunebenheit 254 "Init" 255 "Fehler" ;
VAL_ 2527679659 FA_Niveau_Druck_HL 255 "Fehler" ;
VAL_ 2527679659 FA_Niveau_Druck_HR 255 "Fehler" ;
VAL_ 2527679659 FA_Niveau_Druck_VL 255 "Fehler" ;
VAL_ 2527679659 FA_Niveau_Druck_VR 255 "Fehler" ;
VAL_ 429 NR_Reglerstatus 0 "nicht_definiert" 1 "Hochniveau_2" 2 "Hochniveau_1" 3 "Zwischenniveau" 4 "Normalniveau" 5 "Tiefniveau_1" 6 "Tiefniveau_2" 7 "Tiefniveau_3" 8 "Verladeniveau" 9 "Beladungsniveau" 10 "Heckabsenkung" ;
VAL_ 429 FA_Verstellung_in_Kuerze 0 "keine_Verstellung_erwartet" 1 "Verstellung_erwartet" ;
VAL_ 429 FA_Verstellung_aktiv 0 "keine_Verstellung" 1 "Verstellung_aktiv" ;
VAL_ 429 FA_Kompressor_laeuft_in_Kuerze 0 "kein_Kompressorlauf_erwartet" 1 "Kompressorlauf_steht_bevor" ;
VAL_ 429 FA_Kompressor_laeuft 0 "Kompressor_nicht_angesteuert" 1 "Kompressor_angesteuert" ;
VAL_ 429 NR_Anforderung_v_Begrenzung 0 "keine_Begrenzung_angefordert" 1 "Sicherheitsbegrenzung_1_aktiv" 2 "Sicherheitsbegrenzung_2_aktiv" 3 "Komfortbegrenzung_aktiv" ;
VAL_ 429 NR_LED_SGN 0 "LED_aus" 1 "LED_ein" ;
VAL_ 429 NR_LED_TN 0 "LED_aus" 1 "LED_ein" ;
VAL_ 429 NR_LED_BN 0 "LED_aus" 1 "LED_ein" ;
VAL_ 429 FA_Absenkung_Fahrzeug 0 "keine_Absenkung" 1 "Absenkung_Fahrzeug" ;
VAL_ 429 FA_Anhaengerstatus_intern 0 "Anhaenger_intern_nicht_erkannt" 1 "Anhaenger_intern_erkannt_manuell" 2 "Anhaenger_intern_erkannt_automatisch" 3 "Anhaenger_intern_erkannt_automatisch_manuelle_Deaktivierung_aktiv" 4 "Anhaenger_intern_erkannt_Failsafe" ;
VAL_ 429 FA_Anhebung_Fahrzeug 0 "keine_Anhebung" 1 "Anhebung_Fahrzeug" ;
VAL_ 429 FA_Druckspeicher_verfuegbar 0 "Druckspeicher_nicht_verfuegbar" 1 "Regelung_aus_Druckspeicher_moeglich" ;
VAL_ 429 FA_HAL_Abschaltung 0 "keine_Beeinflussung" 1 "Abschaltung_angefordert" ;
VAL_ 429 FA_ESP_Zuschaltung 0 "keine_ESP_Beeinflussung" 1 "ESP_Zwangszuschaltung_angefordert" ;
VAL_ 429 NR_LED_HN 0 "LED_aus" 1 "LED_ein" ;
VAL_ 429 FA_Zwischenniveau 0 "kein_Zwischenniveau" 1 "Zwischenniveau" ;
VAL_ 429 FA_Systemstatus 0 "nicht_funktionsfaehig" 1 "funktionsfaehig" ;
VAL_ 429 EFP_Soll_FahrPr_HAL 0 "nicht_gesteuert" 1 "Zwang_Programm_1" 2 "Zwang_Programm_2" 3 "Zwang_Programm_3" 4 "Zwang_Programm_4" 5 "Zwang_Programm_5" 6 "Zwang_Programm_6" 7 "Zwang_Programm_7" 8 "Zwang_Programm_8" 9 "Zwang_Programm_9" 10 "Zwang_Programm_10" 11 "Zwang_Programm_11" 12 "Zwang_Programm_12" 13 "Zwang_Programm_13" 14 "Zwang_Programm_14" 15 "Zwang_Programm_15" ;
VAL_ 429 NR_Kompressor_Strom_02 255 "Fehler" ;
VAL_ 429 NR_Kompressor_Temp_Zylinderkopf 254 "Init" 255 "Fehler" ;
VAL_ 429 FA_Signal_Drucksensor 254 "Init" 255 "Fehler" ;
VAL_ 2527679658 FA_FahrerAnf_Fahrwerk 0 "KeinFahrerAnf_Fahrwerk" 1 "FahrerAnf_FahrwerkNormal" 2 "FahrerAnf_FahrwerkSport" 3 "FahrerAnf_FahrwerkSportPlus" ;
VAL_ 2527679658 FA_FahrerAnf_Lift 0 "KeinFahrerAnf_Lift" 1 "FahrerAnf_Lift" ;
VAL_ 2527679658 FA_FahrerAnf_Niveau 0 "KeinFahrerAnf_Niveau" 1 "FahrerAnf_NiveauSGN" 2 "FahrerAnf_NiveauGN" 3 "FahrerAnf_NiveauNN" 4 "FahrerAnf_NiveauTN" 5 "FahrerAnf_NiveauBN" ;
VAL_ 2527679658 EFP_ReifenTemp_HL 63 "Init" ;
VAL_ 2527679658 EFP_ReifenTemp_HR 63 "Init" ;
VAL_ 2527679658 EFP_ReifenTemp_VL 63 "Init" ;
VAL_ 2527679658 EFP_ReifenTemp_VR 63 "Init" ;
VAL_ 2527679658 FA_Beladung_HA 14 "Init" 15 "Fehler" ;
VAL_ 2527679658 FA_Beladung_VA 14 "Init" 15 "Fehler" ;
